VERSION "dbc-export 1 2025.20.8"

NS_ :

BS_:

BU_: ADSP APB APP APS APSB BB BMS CC CMP CMPD CP DAS DI DIF DIR DPB EPAS3P EPAS3S EPASTP EPASTS EPBL EPBR ESP GTW HVP IBST ICR IDB OCS1P ODIN PARK PCS PLG PM PMF PMR PTC RADC RCM RCM2 RCU SCCM SDCR TAS TCU TPMS TRCM UDS UI UIS UMC USM VC VCFRONT VCLEFT VCRIGHT VCSEC

BO_ 1000 EPBR_alertMatrix: 8 EPBR
 SG_ EPBR_matrixIndex M : 0|4@1+ (1,0) [0|15] "" Vector__XXX
 SG_ EPBR_a001_WatchdogReset m0 : 4|1@1+ (1,0) [0|1] "" Vector__XXX
 SG_ EPBR_a002_PowerLossReset m0 : 5|1@1+ (1,0) [0|1] "" Vector__XXX
 SG_ EPBR_a003_SWAssertion m0 : 6|1@1+ (1,0) [0|1] "" Vector__XXX
 SG_ EPBR_a005_CANTXError m0 : 8|1@1+ (1,0) [0|1] "" Vector__XXX
 SG_ EPBR_a006_CANTX_cyclicError m0 : 9|1@1+ (1,0) [0|1] "" Vector__XXX
 SG_ EPBR_a012_CPUReset m0 : 15|1@1+ (1,0) [0|1] "" Vector__XXX
 SG_ EPBR_a013_AlertManagerFault m0 : 16|1@1+ (1,0) [0|1] "" Vector__XXX
 SG_ EPBR_a015_NVMMError m0 : 18|1@1+ (1,0) [0|1] "" Vector__XXX
 SG_ EPBR_a016_NVMMRecordError m0 : 19|1@1+ (1,0) [0|1] "" Vector__XXX
 SG_ EPBR_a021_TaskSchedulerError m0 : 24|1@1+ (1,0) [0|1] "" Vector__XXX
 SG_ EPBR_a022_TaskInitError m0 : 25|1@1+ (1,0) [0|1] "" Vector__XXX
 SG_ EPBR_a029_CoreDump m0 : 32|1@1+ (1,0) [0|1] "" Vector__XXX
 SG_ EPBR_a030_ECULogUploadRequest m0 : 33|1@1+ (1,0) [0|1] "" Vector__XXX
 SG_ EPBR_a031_UDSActive m0 : 34|1@1+ (1,0) [0|1] "" Vector__XXX
 SG_ EPBR_a041_HighCPULoad m0 : 44|1@1+ (1,0) [0|1] "" Vector__XXX
 SG_ EPBR_a042_HighStackUsage m0 : 45|1@1+ (1,0) [0|1] "" Vector__XXX
 SG_ EPBR_a043_Task1msError m0 : 46|1@1+ (1,0) [0|1] "" Vector__XXX
 SG_ EPBR_a044_Task10msError m0 : 47|1@1+ (1,0) [0|1] "" Vector__XXX
 SG_ EPBR_a045_Task100msError m0 : 48|1@1+ (1,0) [0|1] "" Vector__XXX
 SG_ EPBR_a046_Task1000msError m0 : 49|1@1+ (1,0) [0|1] "" Vector__XXX
 SG_ EPBR_a057_HVP_MIA m0 : 60|1@1+ (1,0) [0|1] "" Vector__XXX
 SG_ EPBR_a058_inputRHighSyncDebug m0 : 61|1@1+ (1,0) [0|1] "" Vector__XXX
 SG_ EPBR_a059_inputResistanceHigh m0 : 62|1@1+ (1,0) [0|1] "" Vector__XXX
 SG_ EPBR_a060_engineeringBuild m0 : 63|1@1+ (1,0) [0|1] "" Vector__XXX
 SG_ EPBR_a061_XCPConnected m1 : 4|1@1+ (1,0) [0|1] "" Vector__XXX
 SG_ EPBR_a062_XCPWasConnected m1 : 5|1@1+ (1,0) [0|1] "" Vector__XXX
 SG_ EPBR_a063_SwitchFault m1 : 6|1@1+ (1,0) [0|1] "" Vector__XXX
 SG_ EPBR_a064_busSleepReqTimeout m1 : 7|1@1+ (1,0) [0|1] "" Vector__XXX
 SG_ EPBR_a081_APP_MIA m1 : 24|1@1+ (1,0) [0|1] "" Vector__XXX
 SG_ EPBR_a082_VCRIGHT_IPC_MIA m1 : 25|1@1+ (1,0) [0|1] "" Vector__XXX
 SG_ EPBR_a083_VCLEFT_IPC_MIA m1 : 26|1@1+ (1,0) [0|1] "" Vector__XXX
 SG_ EPBR_a084_TPMS_MIA m1 : 27|1@1+ (1,0) [0|1] "" Vector__XXX
 SG_ EPBR_a085_CCCM_MIA m1 : 28|1@1+ (1,0) [0|1] "" Vector__XXX
 SG_ EPBR_a086_VCBATT_MIA m1 : 29|1@1+ (1,0) [0|1] "" Vector__XXX
 SG_ EPBR_a087_DIREL_MIA m1 : 30|1@1+ (1,0) [0|1] "" Vector__XXX
 SG_ EPBR_a088_DIRER_MIA m1 : 31|1@1+ (1,0) [0|1] "" Vector__XXX
 SG_ EPBR_a089_IBST_MIA m1 : 32|1@1+ (1,0) [0|1] "" Vector__XXX
 SG_ EPBR_a090_APS_MIA m1 : 33|1@1+ (1,0) [0|1] "" Vector__XXX
 SG_ EPBR_a091_CMPD_MIA m1 : 34|1@1+ (1,0) [0|1] "" Vector__XXX
 SG_ EPBR_a092_VCSEATD_MIA m1 : 35|1@1+ (1,0) [0|1] "" Vector__XXX
 SG_ EPBR_a093_VCSEATP_MIA m1 : 36|1@1+ (1,0) [0|1] "" Vector__XXX
 SG_ EPBR_a094_EPAS3P_MIA m1 : 37|1@1+ (1,0) [0|1] "" Vector__XXX
 SG_ EPBR_a095_CHG_MIA m1 : 38|1@1+ (1,0) [0|1] "" Vector__XXX
 SG_ EPBR_a096_OCS1P_MIA m1 : 39|1@1+ (1,0) [0|1] "" Vector__XXX
 SG_ EPBR_a097_CMP_MIA m1 : 40|1@1+ (1,0) [0|1] "" Vector__XXX
 SG_ EPBR_a098_DIR_MIA m1 : 41|1@1+ (1,0) [0|1] "" Vector__XXX
 SG_ EPBR_a099_PARK_MIA m1 : 42|1@1+ (1,0) [0|1] "" Vector__XXX
 SG_ EPBR_a100_CANbus_MIA m1 : 43|1@1+ (1,0) [0|1] "" Vector__XXX
 SG_ EPBR_a101_PM_MIA m1 : 44|1@1+ (1,0) [0|1] "" Vector__XXX
 SG_ EPBR_a102_PTC_MIA m1 : 45|1@1+ (1,0) [0|1] "" Vector__XXX
 SG_ EPBR_a103_CP_MIA m1 : 46|1@1+ (1,0) [0|1] "" Vector__XXX
 SG_ EPBR_a104_DAS_MIA m1 : 47|1@1+ (1,0) [0|1] "" Vector__XXX
 SG_ EPBR_a105_TAS_MIA m1 : 48|1@1+ (1,0) [0|1] "" Vector__XXX
 SG_ EPBR_a106_PCS_MIA m1 : 49|1@1+ (1,0) [0|1] "" Vector__XXX
 SG_ EPBR_a107_BMS_MIA m1 : 50|1@1+ (1,0) [0|1] "" Vector__XXX
 SG_ EPBR_a108_DIF_MIA m1 : 51|1@1+ (1,0) [0|1] "" Vector__XXX
 SG_ EPBR_a109_RCM_MIA m1 : 52|1@1+ (1,0) [0|1] "" Vector__XXX
 SG_ EPBR_a110_GTW_MIA m1 : 53|1@1+ (1,0) [0|1] "" Vector__XXX
 SG_ EPBR_a111_EPBR_MIA m1 : 54|1@1+ (1,0) [0|1] "" Vector__XXX
 SG_ EPBR_a112_EPBL_MIA m1 : 55|1@1+ (1,0) [0|1] "" Vector__XXX
 SG_ EPBR_a113_UI_MIA m1 : 56|1@1+ (1,0) [0|1] "" Vector__XXX
 SG_ EPBR_a114_ESP_MIA m1 : 57|1@1+ (1,0) [0|1] "" Vector__XXX
 SG_ EPBR_a115_VCSEC_MIA m1 : 58|1@1+ (1,0) [0|1] "" Vector__XXX
 SG_ EPBR_a116_VCRIGHT_MIA m1 : 59|1@1+ (1,0) [0|1] "" Vector__XXX
 SG_ EPBR_a117_VCLEFT_MIA m1 : 60|1@1+ (1,0) [0|1] "" Vector__XXX
 SG_ EPBR_a118_VCFRONT_MIA m1 : 61|1@1+ (1,0) [0|1] "" Vector__XXX
 SG_ EPBR_a119_SCCM_MIA m1 : 62|1@1+ (1,0) [0|1] "" Vector__XXX
 SG_ EPBR_a120_DI_DRIVE_MIA m1 : 63|1@1+ (1,0) [0|1] "" Vector__XXX
 SG_ EPBR_a121_nDriveFault m2 : 4|1@1+ (1,0) [0|1] "" Vector__XXX
 SG_ EPBR_a122_Oc m2 : 5|1@1+ (1,0) [0|1] "" Vector__XXX
 SG_ EPBR_a123_Uc m2 : 6|1@1+ (1,0) [0|1] "" Vector__XXX
 SG_ EPBR_a124_calOutOfBounds m2 : 7|1@1+ (1,0) [0|1] "" Vector__XXX
 SG_ EPBR_a125_IdleVMismatch m2 : 8|1@1+ (1,0) [0|1] "" Vector__XXX
 SG_ EPBR_a126_MotorNVoltLow m2 : 9|1@1+ (1,0) [0|1] "" Vector__XXX
 SG_ EPBR_a127_MotorNVoltHigh m2 : 10|1@1+ (1,0) [0|1] "" Vector__XXX
 SG_ EPBR_a128_MotorPVoltHigh m2 : 11|1@1+ (1,0) [0|1] "" Vector__XXX
 SG_ EPBR_a129_ICR_MIA m2 : 12|1@1+ (1,0) [0|1] "" Vector__XXX
 SG_ EPBR_a130_BB_MIA m2 : 13|1@1+ (1,0) [0|1] "" Vector__XXX
 SG_ EPBR_a131_RCU_MIA m2 : 14|1@1+ (1,0) [0|1] "" Vector__XXX
 SG_ EPBR_a132_VCBATT1_MIA m2 : 15|1@1+ (1,0) [0|1] "" Vector__XXX
 SG_ EPBR_a134_NvOv m2 : 17|1@1+ (1,0) [0|1] "" Vector__XXX
 SG_ EPBR_a135_NvUv m2 : 18|1@1+ (1,0) [0|1] "" Vector__XXX
 SG_ EPBR_a136_PvOv m2 : 19|1@1+ (1,0) [0|1] "" Vector__XXX
 SG_ EPBR_a137_PvUv m2 : 20|1@1+ (1,0) [0|1] "" Vector__XXX
 SG_ EPBR_a138_NvmDualFailure m2 : 21|1@1+ (1,0) [0|1] "" Vector__XXX
 SG_ EPBR_a139_NvmRedundancyLoss m2 : 22|1@1+ (1,0) [0|1] "" Vector__XXX
 SG_ EPBR_a140_NvmSlowWrite m2 : 23|1@1+ (1,0) [0|1] "" Vector__XXX
 SG_ EPBR_a141_invalidState m2 : 24|1@1+ (1,0) [0|1] "" Vector__XXX
 SG_ EPBR_a170_12vOv m2 : 53|1@1+ (1,0) [0|1] "" Vector__XXX
 SG_ EPBR_a171_12vUv m2 : 54|1@1+ (1,0) [0|1] "" Vector__XXX
 SG_ EPBR_a172_SPI_MIA m2 : 55|1@1+ (1,0) [0|1] "" Vector__XXX
 SG_ EPBR_a173_hiCurrentMissing m2 : 56|1@1+ (1,0) [0|1] "" Vector__XXX
 SG_ EPBR_a174_csmReleaseFailed m2 : 57|1@1+ (1,0) [0|1] "" Vector__XXX
 SG_ EPBR_a175_csmReleaseRetry m2 : 58|1@1+ (1,0) [0|1] "" Vector__XXX
 SG_ EPBR_a176_csmApplyFailed m2 : 59|1@1+ (1,0) [0|1] "" Vector__XXX
 SG_ EPBR_a177_csmApplyRetry m2 : 60|1@1+ (1,0) [0|1] "" Vector__XXX
 SG_ EPBR_a178_caliperStateUnknown m2 : 61|1@1+ (1,0) [0|1] "" Vector__XXX
 SG_ EPBR_a179_epbProblem m2 : 62|1@1+ (1,0) [0|1] "" Vector__XXX
 SG_ EPBR_a180_dynamicActive m2 : 63|1@1+ (1,0) [0|1] "" Vector__XXX
 SG_ EPBR_a181_TooSteepGradeToPark m3 : 4|1@1+ (1,0) [0|1] "" Vector__XXX
 SG_ EPBR_a182_OneEPBAppliedUnsecEnv m3 : 5|1@1+ (1,0) [0|1] "" Vector__XXX
 SG_ EPBR_a183_cdpNotAvailable m3 : 6|1@1+ (1,0) [0|1] "" Vector__XXX
 SG_ EPBR_a184_dynamicParkAbort m3 : 7|1@1+ (1,0) [0|1] "" Vector__XXX
 SG_ EPBR_a185_summonAborted m3 : 8|1@1+ (1,0) [0|1] "" Vector__XXX
 SG_ EPBR_a186_externalParkAbort m3 : 9|1@1+ (1,0) [0|1] "" Vector__XXX
 SG_ EPBR_a187_cdpDynamic m3 : 10|1@1+ (1,0) [0|1] "" Vector__XXX
 SG_ EPBR_a188_epbDynamic m3 : 11|1@1+ (1,0) [0|1] "" Vector__XXX
 SG_ EPBR_a189_epbDynamicParkCanceled m3 : 12|1@1+ (1,0) [0|1] "" Vector__XXX
 SG_ EPBR_a190_csmApplyDegraded m3 : 13|1@1+ (1,0) [0|1] "" Vector__XXX
 SG_ EPBR_a191_csmReleaseDegraded m3 : 14|1@1+ (1,0) [0|1] "" Vector__XXX
 SG_ EPBR_a195_parkForDriverIsLeaving m3 : 18|1@1+ (1,0) [0|1] "" Vector__XXX
 SG_ EPBR_a196_freeRollModeActive m3 : 19|1@1+ (1,0) [0|1] "" Vector__XXX
 SG_ EPBR_a197_freeRollModeAtSpeed m3 : 20|1@1+ (1,0) [0|1] "" Vector__XXX
 SG_ EPBR_a198_holdClampComplete m3 : 21|1@1+ (1,0) [0|1] "" Vector__XXX
 SG_ EPBR_a200_PmUnparkNotAllowed m3 : 23|1@1+ (1,0) [0|1] "" Vector__XXX
 SG_ EPBR_a202_remoteEpbConfigIncompa m3 : 25|1@1+ (1,0) [0|1] "" Vector__XXX
 SG_ EPBR_a203_hwBrakeTypeMismatch m3 : 26|1@1+ (1,0) [0|1] "" Vector__XXX
 SG_ EPBR_a210_parkForDriverIsLeaving m3 : 33|1@1+ (1,0) [0|1] "" Vector__XXX
 SG_ EPBR_a216_SPI_MIA_debugData1 m3 : 39|1@1+ (1,0) [0|1] "" Vector__XXX
 SG_ EPBR_a217_SPI_MIA_debugData2 m3 : 40|1@1+ (1,0) [0|1] "" Vector__XXX
 SG_ EPBR_a225_epbActiveDecel m3 : 48|1@1+ (1,0) [0|1] "" Vector__XXX
 SG_ EPBR_a241_diOutputLocked m4 : 4|1@1+ (1,0) [0|1] "" Vector__XXX
 SG_ EPBR_a242_hvOutputLocked m4 : 5|1@1+ (1,0) [0|1] "" Vector__XXX
 SG_ EPBR_a243_bdwUnavailable m4 : 6|1@1+ (1,0) [0|1] "" Vector__XXX
 SG_ EPBR_a244_WinchModeActive m4 : 7|1@1+ (1,0) [0|1] "" Vector__XXX
 SG_ EPBR_a245_serviceModeActive m4 : 8|1@1+ (1,0) [0|1] "" Vector__XXX
 SG_ EPBR_a246_idleFaultApply m4 : 9|1@1+ (1,0) [0|1] "" Vector__XXX
 SG_ EPBR_a247_csmDynamicApplyRetry m4 : 10|1@1+ (1,0) [0|1] "" Vector__XXX
 SG_ EPBR_a248_csmDynamicApplyFailed m4 : 11|1@1+ (1,0) [0|1] "" Vector__XXX
 SG_ EPBR_a249_idleFaultRelease m4 : 12|1@1+ (1,0) [0|1] "" Vector__XXX
 SG_ EPBR_a250_WinchModeCanceled m4 : 13|1@1+ (1,0) [0|1] "" Vector__XXX
 SG_ EPBR_a251_currentVarianceHigh m4 : 14|1@1+ (1,0) [0|1] "" Vector__XXX
 SG_ EPBR_a252_winchModePending m4 : 15|1@1+ (1,0) [0|1] "" Vector__XXX
 SG_ EPBR_a253_esmReleaseBlocked m4 : 16|1@1+ (1,0) [0|1] "" Vector__XXX
 SG_ EPBR_a254_showStalkParkButtonFau m4 : 17|1@1+ (1,0) [0|1] "" Vector__XXX
 SG_ EPBR_a256_epbSystemApply m4 : 19|1@1+ (1,0) [0|1] "" Vector__XXX
 SG_ EPBR_a261_winchModeWithoutSteeri m4 : 24|1@1+ (1,0) [0|1] "" Vector__XXX
 SG_ EPBR_a262_cannotPrepareWinchMode m4 : 25|1@1+ (1,0) [0|1] "" Vector__XXX
 SG_ EPBR_a263_epbRecoveryPark m4 : 26|1@1+ (1,0) [0|1] "" Vector__XXX
 SG_ EPBR_a264_winchModeDeactivated m4 : 27|1@1+ (1,0) [0|1] "" Vector__XXX
 SG_ EPBR_a272_vhclPwrStateMsmtch m4 : 35|1@1+ (1,0) [0|1] "" Vector__XXX
 SG_ EPBR_a300_leftRightConfusion m4 : 63|1@1+ (1,0) [0|1] "" Vector__XXX
 SG_ EPBR_a301_oocSpeedViolation m5 : 4|1@1+ (1,0) [0|1] "" Vector__XXX
 SG_ EPBR_a302_csmLongRelease m5 : 5|1@1+ (1,0) [0|1] "" Vector__XXX
 SG_ EPBR_a303_clampingOccuredEarly m5 : 6|1@1+ (1,0) [0|1] "" Vector__XXX
 SG_ EPBR_a304_rearSeatControllerEFus m5 : 7|1@1+ (1,0) [0|1] "" Vector__XXX
 SG_ EPBR_a305_premiumAmpEFuseTrip m5 : 8|1@1+ (1,0) [0|1] "" Vector__XXX
 SG_ EPBR_a350_ensOutOfRange m5 : 53|1@1+ (1,0) [0|1] "" Vector__XXX
 SG_ EPBR_a352_audioCurrentSpikeData m5 : 55|1@1+ (1,0) [0|1] "" Vector__XXX
 SG_ EPBR_a353_missingSpeedUnableToPa m5 : 56|1@1+ (1,0) [0|1] "" Vector__XXX
 SG_ EPBR_a354_parkedForLowBrakeFluid m5 : 57|1@1+ (1,0) [0|1] "" Vector__XXX
 SG_ EPBR_a355_brakeHwAndEpbHwMismatc m5 : 58|1@1+ (1,0) [0|1] "" Vector__XXX
 SG_ EPBR_a356_parkingForStationaryDe m5 : 59|1@1+ (1,0) [0|1] "" Vector__XXX
 SG_ EPBR_a357_brakesTooHotForSlope m5 : 60|1@1+ (1,0) [0|1] "" Vector__XXX
 SG_ EPBR_a358_brakesTooHotForSlopeWi m5 : 61|1@1+ (1,0) [0|1] "" Vector__XXX
 SG_ EPBR_a360_ibstBrakeSwitchInvalid m5 : 63|1@1+ (1,0) [0|1] "" Vector__XXX
 SG_ EPBR_a361_espBrakeSwitchInvalid m6 : 4|1@1+ (1,0) [0|1] "" Vector__XXX
 SG_ EPBR_a362_ibstPressedEspNotPress m6 : 5|1@1+ (1,0) [0|1] "" Vector__XXX
 SG_ EPBR_a363_ibstNotPressedEspPress m6 : 6|1@1+ (1,0) [0|1] "" Vector__XXX
 SG_ EPBR_a364_espMasterCylCompOverTh m6 : 7|1@1+ (1,0) [0|1] "" Vector__XXX
 SG_ EPBR_a365_TooSteepToParkWithTrai m6 : 8|1@1+ (1,0) [0|1] "" Vector__XXX
 SG_ EPBR_a366_TooSteepToParkWithTrai m6 : 9|1@1+ (1,0) [0|1] "" Vector__XXX

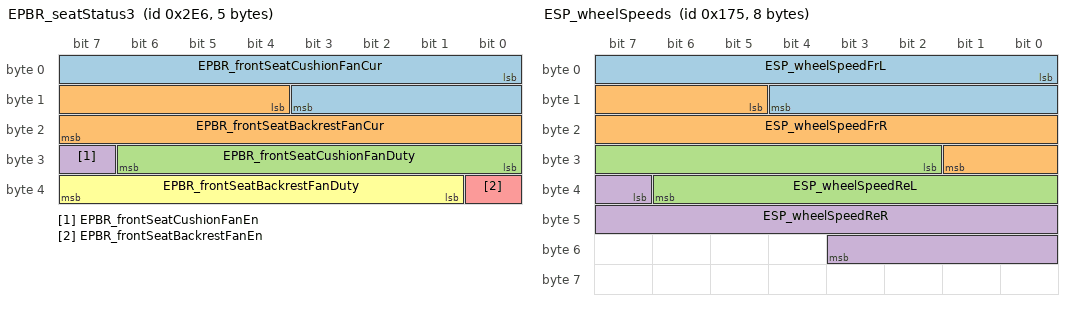
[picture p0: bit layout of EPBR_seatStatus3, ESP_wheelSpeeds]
BO_ 742 EPBR_seatStatus3: 5 EPBR
 SG_ EPBR_frontSeatCushionFanCur : 0|12@1+ (0.01,0) [0|40.95] "A" Vector__XXX
 SG_ EPBR_frontSeatBackrestFanCur : 12|12@1+ (0.01,0) [0|40.95] "A" Vector__XXX
 SG_ EPBR_frontSeatCushionFanDuty : 24|7@1+ (1,0) [0|100] "%" Vector__XXX
 SG_ EPBR_frontSeatCushionFanEn : 31|1@1+ (1,0) [0|1] "" Vector__XXX
 SG_ EPBR_frontSeatBackrestFanEn : 32|1@1+ (1,0) [0|1] "" Vector__XXX
 SG_ EPBR_frontSeatBackrestFanDuty : 33|7@1+ (1,0) [0|100] "%" Vector__XXX

BO_ 744 EPBR_status: 8 EPBR
 SG_ EPBR_systemStatus : 0|4@1+ (1,0) [0|15] "" Vector__XXX
 SG_ EPBR_freeRollModeStatus : 4|2@1+ (1,0) [0|3] "" Vector__XXX
 SG_ EPBR_driverIsLeaving : 6|1@1+ (1,0) [0|1] "" Vector__XXX
 SG_ EPBR_driverIsLeavingAnySpeed : 7|1@1+ (1,0) [0|1] "" Vector__XXX
 SG_ EPBR_systemCdpAvailable : 8|1@1+ (1,0) [0|1] "" Vector__XXX
 SG_ EPBR_chimeRequest : 9|3@1+ (1,0) [0|7] "" Vector__XXX
 SG_ EPBR_telltale : 12|3@1+ (1,0) [0|6] "" Vector__XXX
 SG_ EPBR_audioCurrentSpikeDetected : 15|1@1+ (1,0) [0|1] "" Vector__XXX
 SG_ EPBR_redundantBrakingEnabled : 16|1@1+ (1,0) [0|1] "" Vector__XXX
 SG_ EPBR_summonEnabled : 17|1@1+ (1,0) [0|1] "" Vector__XXX
 SG_ EPBR_brakeLight : 18|1@1+ (1,0) [0|1] "" Vector__XXX
 SG_ EPBR_epbConfigMismatch : 19|1@1+ (1,0) [0|1] "" Vector__XXX
 SG_ EPBR_brakeConfirmedPressed : 20|1@1+ (1,0) [0|1] "" Vector__XXX
 SG_ EPBR_requestUserConfirmation : 21|1@1+ (1,0) [0|1] "" Vector__XXX
 SG_ EPBR_uiWinchModeMiscBlocking : 22|1@1+ (1,0) [0|1] "" Vector__XXX
 SG_ EPBR_winchModeActive : 23|1@1+ (1,0) [0|1] "" Vector__XXX
 SG_ EPBR_updateMode : 24|1@1+ (1,0) [0|1] "" Vector__XXX
 SG_ EPBR_winchModePermissive : 25|1@1+ (1,0) [0|1] "" Vector__XXX
 SG_ EPBR_winchModePending : 26|1@1+ (1,0) [0|1] "" Vector__XXX
 SG_ EPBR_cdpRequest : 27|1@1+ (1,0) [0|1] "" Vector__XXX
 SG_ EPBR_uiParkAvailable : 28|2@1+ (1,0) [0|3] "" Vector__XXX
 SG_ EPBR_brakeDiscWipeRequest : 30|2@1+ (1,0) [0|2] "" Vector__XXX
 SG_ EPBR_showUiGearShifter : 32|1@1+ (1,0) [0|1] "" Vector__XXX
 SG_ EPBR_uiWinchModeLvStatus : 33|2@1+ (1,0) [0|3] "" Vector__XXX
 SG_ EPBR_contactorCycleNotNeededForW : 35|1@1+ (1,0) [0|1] "" Vector__XXX
 SG_ EPBR_showStalkFaultedOnUi : 45|1@1+ (1,0) [0|1] "" Vector__XXX
 SG_ EPBR_espPowerRequest : 46|1@1+ (1,0) [0|1] "" Vector__XXX
 SG_ EPBR_okToPark : 47|1@1+ (1,0) [0|1] "" Vector__XXX
 SG_ EPBR_hornRequest : 48|1@1+ (1,0) [0|1] "" Vector__XXX
 SG_ EPBR_winchModeAvailable : 49|1@1+ (1,0) [0|1] "" Vector__XXX
 SG_ EPBR_bothDisconnected : 50|1@1+ (1,0) [0|1] "" Vector__XXX
 SG_ EPBR_blockDrive : 51|1@1+ (1,0) [0|1] "" Vector__XXX
 SG_ EPBR_statusCounter : 52|4@1+ (1,0) [0|15] "" Vector__XXX
 SG_ EPBR_statusChecksum : 56|8@1+ (1,0) [0|255] "" Vector__XXX

BO_ 1575 EPBR_udsResponse: 8 EPBR
 SG_ EPBR_udsResponseData_H : 7|32@0+ (1,0) [0|4294967295] "" Vector__XXX
 SG_ EPBR_udsResponseData_L : 39|32@0+ (1,0) [0|4294967295] "" Vector__XXX

BO_ 981 ESP_alertMatrix: 8 ESP
 SG_ ESP_matrixIndex M : 0|4@1+ (1,0) [0|15] "" Vector__XXX
 SG_ ESP_a001_ecuGenericFault m0 : 4|1@1+ (1,0) [0|1] "" Vector__XXX
 SG_ ESP_a002_valvesGenericFault m0 : 5|1@1+ (1,0) [0|1] "" Vector__XXX
 SG_ ESP_a003_outletValvesFault m0 : 6|1@1+ (1,0) [0|1] "" Vector__XXX
 SG_ ESP_a004_inletValvesFault m0 : 7|1@1+ (1,0) [0|1] "" Vector__XXX
 SG_ ESP_a005_HSVValvesFault m0 : 8|1@1+ (1,0) [0|1] "" Vector__XXX
 SG_ ESP_a006_USVValvesFault m0 : 9|1@1+ (1,0) [0|1] "" Vector__XXX
 SG_ ESP_a007_pumpMotorFault m0 : 10|1@1+ (1,0) [0|1] "" Vector__XXX
 SG_ ESP_a008_pumpMotor12VsupplyLow m0 : 11|1@1+ (1,0) [0|1] "" Vector__XXX
 SG_ ESP_a009_12VHardUndervoltage m0 : 12|1@1+ (1,0) [0|1] "" Vector__XXX
 SG_ ESP_a010_12VUndervoltage m0 : 13|1@1+ (1,0) [0|1] "" Vector__XXX
 SG_ ESP_a011_12VSystemUndervoltage m0 : 14|1@1+ (1,0) [0|1] "" Vector__XXX
 SG_ ESP_a012_netUndervoltage m0 : 15|1@1+ (1,0) [0|1] "" Vector__XXX
 SG_ ESP_a013_valveRelayUndervoltage m0 : 16|1@1+ (1,0) [0|1] "" Vector__XXX
 SG_ ESP_a014_WSSSupplyUndervoltage m0 : 17|1@1+ (1,0) [0|1] "" Vector__XXX
 SG_ ESP_a015_12VSupplyOvervoltage m0 : 18|1@1+ (1,0) [0|1] "" Vector__XXX
 SG_ ESP_a016_12VSystemOvervoltage m0 : 19|1@1+ (1,0) [0|1] "" Vector__XXX
 SG_ ESP_a017_netOvervoltage m0 : 20|1@1+ (1,0) [0|1] "" Vector__XXX
 SG_ ESP_a018_WSSSignFrontAxle m0 : 21|1@1+ (1,0) [0|1] "" Vector__XXX
 SG_ ESP_a019_WSSSignRearAxle m0 : 22|1@1+ (1,0) [0|1] "" Vector__XXX
 SG_ ESP_a020_WSSGenericTempFault m0 : 23|1@1+ (1,0) [0|1] "" Vector__XXX
 SG_ ESP_a021_WSSGeneralVDiffFault m0 : 24|1@1+ (1,0) [0|1] "" Vector__XXX
 SG_ ESP_a022_WSSDirectionFault m0 : 25|1@1+ (1,0) [0|1] "" Vector__XXX
 SG_ ESP_a023_WSSSeveralSuspected m0 : 26|1@1+ (1,0) [0|1] "" Vector__XXX
 SG_ ESP_a024_WSSReverseCurrent m0 : 27|1@1+ (1,0) [0|1] "" Vector__XXX
 SG_ ESP_a025_FrLWSSOpenOrShortToGnd m0 : 28|1@1+ (1,0) [0|1] "" Vector__XXX
 SG_ ESP_a026_FrLWSSShortTo12V m0 : 29|1@1+ (1,0) [0|1] "" Vector__XXX
 SG_ ESP_a027_FrLWSSLineInterruption m0 : 30|1@1+ (1,0) [0|1] "" Vector__XXX
 SG_ ESP_a028_FrLWSSMaxSpeedExceeded m0 : 31|1@1+ (1,0) [0|1] "" Vector__XXX
 SG_ ESP_a029_FrLWSSTooManyPulses m0 : 32|1@1+ (1,0) [0|1] "" Vector__XXX
 SG_ ESP_a030_FrLWSSLostSignal m0 : 33|1@1+ (1,0) [0|1] "" Vector__XXX
 SG_ ESP_a031_FrLWSSNoPulsesDetected m0 : 34|1@1+ (1,0) [0|1] "" Vector__XXX
 SG_ ESP_a032_FrLWSSWrongSensorType m0 : 35|1@1+ (1,0) [0|1] "" Vector__XXX
 SG_ ESP_a033_FrLWSSSignalNoise m0 : 36|1@1+ (1,0) [0|1] "" Vector__XXX
 SG_ ESP_a034_FrLWSSVDiffFault m0 : 37|1@1+ (1,0) [0|1] "" Vector__XXX
 SG_ ESP_a035_FrLWSSDirectionFault m0 : 38|1@1+ (1,0) [0|1] "" Vector__XXX
 SG_ ESP_a036_FrLWSSLargeAirGap m0 : 39|1@1+ (1,0) [0|1] "" Vector__XXX
 SG_ ESP_a037_FrLWSSSupplyShortToGnd m0 : 40|1@1+ (1,0) [0|1] "" Vector__XXX
 SG_ ESP_a038_FrLWSSGeneralFault m0 : 41|1@1+ (1,0) [0|1] "" Vector__XXX
 SG_ ESP_a039_FrRWSSOpenOrShortToGnd m0 : 42|1@1+ (1,0) [0|1] "" Vector__XXX
 SG_ ESP_a040_FrRWSSShortTo12V m0 : 43|1@1+ (1,0) [0|1] "" Vector__XXX
 SG_ ESP_a041_FrRWSSLineInterruption m0 : 44|1@1+ (1,0) [0|1] "" Vector__XXX
 SG_ ESP_a042_FrRWSSMaxSpeedExceeded m0 : 45|1@1+ (1,0) [0|1] "" Vector__XXX
 SG_ ESP_a043_FrRWSSTooManyPulses m0 : 46|1@1+ (1,0) [0|1] "" Vector__XXX
 SG_ ESP_a044_FrRWSSLostSignal m0 : 47|1@1+ (1,0) [0|1] "" Vector__XXX
 SG_ ESP_a045_FrRWSSNoPulsesDetected m0 : 48|1@1+ (1,0) [0|1] "" Vector__XXX
 SG_ ESP_a046_FrRWSSWrongSensorType m0 : 49|1@1+ (1,0) [0|1] "" Vector__XXX
 SG_ ESP_a047_FrRWSSSignalNoise m0 : 50|1@1+ (1,0) [0|1] "" Vector__XXX
 SG_ ESP_a048_FrRWSSVDiffFault m0 : 51|1@1+ (1,0) [0|1] "" Vector__XXX
 SG_ ESP_a049_FrRWSSDirectionFault m0 : 52|1@1+ (1,0) [0|1] "" Vector__XXX
 SG_ ESP_a050_FrRWSSLargeAirGap m0 : 53|1@1+ (1,0) [0|1] "" Vector__XXX
 SG_ ESP_a051_FrRWSSSupplyShortToGnd m0 : 54|1@1+ (1,0) [0|1] "" Vector__XXX
 SG_ ESP_a052_FrRWSSGeneralFault m0 : 55|1@1+ (1,0) [0|1] "" Vector__XXX
 SG_ ESP_a053_ReLWSSOpenOrShortToGnd m0 : 56|1@1+ (1,0) [0|1] "" Vector__XXX
 SG_ ESP_a054_ReLWSSShortTo12V m0 : 57|1@1+ (1,0) [0|1] "" Vector__XXX
 SG_ ESP_a055_ReLWSSLineInterruption m0 : 58|1@1+ (1,0) [0|1] "" Vector__XXX
 SG_ ESP_a056_ReLWSSMaxSpeedExceeded m0 : 59|1@1+ (1,0) [0|1] "" Vector__XXX
 SG_ ESP_a057_ReLWSSTooManyPulses m0 : 60|1@1+ (1,0) [0|1] "" Vector__XXX
 SG_ ESP_a058_ReLWSSLostSignal m0 : 61|1@1+ (1,0) [0|1] "" Vector__XXX
 SG_ ESP_a059_ReLWSSNoPulsesDetected m0 : 62|1@1+ (1,0) [0|1] "" Vector__XXX
 SG_ ESP_a060_ReLWSSWrongSensorType m0 : 63|1@1+ (1,0) [0|1] "" Vector__XXX
 SG_ ESP_a061_ReLWSSSignalNoise m1 : 4|1@1+ (1,0) [0|1] "" Vector__XXX
 SG_ ESP_a062_ReLWSSVDiffFault m1 : 5|1@1+ (1,0) [0|1] "" Vector__XXX
 SG_ ESP_a063_ReLWSSDirectionFault m1 : 6|1@1+ (1,0) [0|1] "" Vector__XXX
 SG_ ESP_a064_ReLWSSLargeAirGap m1 : 7|1@1+ (1,0) [0|1] "" Vector__XXX
 SG_ ESP_a065_ReLWSSSupplyShortToGnd m1 : 8|1@1+ (1,0) [0|1] "" Vector__XXX
 SG_ ESP_a066_ReLWSSGeneralFault m1 : 9|1@1+ (1,0) [0|1] "" Vector__XXX
 SG_ ESP_a067_ReRWSSOpenOrShortToGnd m1 : 10|1@1+ (1,0) [0|1] "" Vector__XXX
 SG_ ESP_a068_ReRWSSShortTo12V m1 : 11|1@1+ (1,0) [0|1] "" Vector__XXX
 SG_ ESP_a069_ReRWSSLineInterruption m1 : 12|1@1+ (1,0) [0|1] "" Vector__XXX
 SG_ ESP_a070_ReRWSSMaxSpeedExceeded m1 : 13|1@1+ (1,0) [0|1] "" Vector__XXX
 SG_ ESP_a071_ReRWSSTooManyPulses m1 : 14|1@1+ (1,0) [0|1] "" Vector__XXX
 SG_ ESP_a072_ReRWSSLostSignal m1 : 15|1@1+ (1,0) [0|1] "" Vector__XXX
 SG_ ESP_a073_ReRWSSNoPulsesDetected m1 : 16|1@1+ (1,0) [0|1] "" Vector__XXX
 SG_ ESP_a074_ReRWSSWrongSensorType m1 : 17|1@1+ (1,0) [0|1] "" Vector__XXX
 SG_ ESP_a075_ReRWSSSignalNoise m1 : 18|1@1+ (1,0) [0|1] "" Vector__XXX
 SG_ ESP_a076_ReRWSSVDiffFault m1 : 19|1@1+ (1,0) [0|1] "" Vector__XXX
 SG_ ESP_a077_ReRWSSDirectionFault m1 : 20|1@1+ (1,0) [0|1] "" Vector__XXX
 SG_ ESP_a078_ReRWSSLargeAirGap m1 : 21|1@1+ (1,0) [0|1] "" Vector__XXX
 SG_ ESP_a079_ReRWSSSupplyShortToGnd m1 : 22|1@1+ (1,0) [0|1] "" Vector__XXX
 SG_ ESP_a080_ReRWSSGeneralFault m1 : 23|1@1+ (1,0) [0|1] "" Vector__XXX
 SG_ ESP_a081_PressureSensorShort m1 : 24|1@1+ (1,0) [0|1] "" Vector__XXX
 SG_ ESP_a082_PMCSensorOffsetHigh m1 : 25|1@1+ (1,0) [0|1] "" Vector__XXX
 SG_ ESP_a083_PMCSensorFault m1 : 26|1@1+ (1,0) [0|1] "" Vector__XXX
 SG_ ESP_a084_BrakeFluidReservoirLow m1 : 27|1@1+ (1,0) [0|1] "" Vector__XXX
 SG_ ESP_a085_BrakeSwitchStuckHigh m1 : 28|1@1+ (1,0) [0|1] "" Vector__XXX
 SG_ ESP_a086_BrakeSwitchImplausible1 m1 : 29|1@1+ (1,0) [0|1] "" Vector__XXX
 SG_ ESP_a087_BrakeSwitchImplausible3 m1 : 30|1@1+ (1,0) [0|1] "" Vector__XXX
 SG_ ESP_a088_absContinuousControl m1 : 31|1@1+ (1,0) [0|1] "" Vector__XXX
 SG_ ESP_a089_absNoPressureIncrease m1 : 32|1@1+ (1,0) [0|1] "" Vector__XXX
 SG_ ESP_a090_vdcContinuousControl m1 : 33|1@1+ (1,0) [0|1] "" Vector__XXX
 SG_ ESP_a091_CANUndervoltage m1 : 34|1@1+ (1,0) [0|1] "" Vector__XXX
 SG_ ESP_a092_CANOvervoltage m1 : 35|1@1+ (1,0) [0|1] "" Vector__XXX
 SG_ ESP_a093_partyBusOff m1 : 36|1@1+ (1,0) [0|1] "" Vector__XXX
 SG_ ESP_a094_partyBusPassive m1 : 37|1@1+ (1,0) [0|1] "" Vector__XXX
 SG_ ESP_a095_chassisBusOff m1 : 38|1@1+ (1,0) [0|1] "" Vector__XXX
 SG_ ESP_a096_chassisBusPassive m1 : 39|1@1+ (1,0) [0|1] "" Vector__XXX
 SG_ ESP_a097_tcsRefSpeedNotInit m1 : 40|1@1+ (1,0) [0|1] "" Vector__XXX
 SG_ ESP_a098_vdcRefSpeedNotInit m1 : 41|1@1+ (1,0) [0|1] "" Vector__XXX
 SG_ ESP_a099_brakeTempModelOverheat m1 : 42|1@1+ (1,0) [0|1] "" Vector__XXX
 SG_ ESP_a100_brakeTempModelDisabled m1 : 43|1@1+ (1,0) [0|1] "" Vector__XXX
 SG_ ESP_a101_ebdFault m1 : 44|1@1+ (1,0) [0|1] "" Vector__XXX
 SG_ ESP_a102_absFault m1 : 45|1@1+ (1,0) [0|1] "" Vector__XXX
 SG_ ESP_a103_stabilityControlFault m1 : 46|1@1+ (1,0) [0|1] "" Vector__XXX
 SG_ ESP_a104_hbcEnabled m1 : 47|1@1+ (1,0) [0|1] "" Vector__XXX
 SG_ ESP_a105_ebrFault m1 : 48|1@1+ (1,0) [0|1] "" Vector__XXX
 SG_ ESP_a106_vdcActuatorFault m1 : 49|1@1+ (1,0) [0|1] "" Vector__XXX
 SG_ ESP_a107_reserved107 m1 : 50|1@1+ (1,0) [0|1] "" Vector__XXX
 SG_ ESP_a108_reserved108 m1 : 51|1@1+ (1,0) [0|1] "" Vector__XXX
 SG_ ESP_a109_reserved109 m1 : 52|1@1+ (1,0) [0|1] "" Vector__XXX
 SG_ ESP_a110_rollerBenchActive m1 : 53|1@1+ (1,0) [0|1] "" Vector__XXX
 SG_ ESP_a111_absActive m1 : 54|1@1+ (1,0) [0|1] "" Vector__XXX
 SG_ ESP_a112_espActive m1 : 55|1@1+ (1,0) [0|1] "" Vector__XXX
 SG_ ESP_a113_btcActive m1 : 56|1@1+ (1,0) [0|1] "" Vector__XXX
 SG_ ESP_a114_tvdcActive m1 : 57|1@1+ (1,0) [0|1] "" Vector__XXX
 SG_ ESP_a115_ebdActive m1 : 58|1@1+ (1,0) [0|1] "" Vector__XXX
 SG_ ESP_a116_tsmActive m1 : 59|1@1+ (1,0) [0|1] "" Vector__XXX
 SG_ ESP_a117_hbaActive m1 : 60|1@1+ (1,0) [0|1] "" Vector__XXX
 SG_ ESP_a118_hfcActive m1 : 61|1@1+ (1,0) [0|1] "" Vector__XXX
 SG_ ESP_a119_hbbActive m1 : 62|1@1+ (1,0) [0|1] "" Vector__XXX
 SG_ ESP_a120_rmiActive m1 : 63|1@1+ (1,0) [0|1] "" Vector__XXX
 SG_ ESP_a121_regenTcActive m2 : 4|1@1+ (1,0) [0|1] "" Vector__XXX
 SG_ ESP_a122_bdwActive m2 : 5|1@1+ (1,0) [0|1] "" Vector__XXX
 SG_ ESP_a123_ebrActive m2 : 6|1@1+ (1,0) [0|1] "" Vector__XXX
 SG_ ESP_a124_ebrSkidActive m2 : 7|1@1+ (1,0) [0|1] "" Vector__XXX
 SG_ ESP_a125_reserved125 m2 : 8|1@1+ (1,0) [0|1] "" Vector__XXX
 SG_ ESP_a126_reserved126 m2 : 9|1@1+ (1,0) [0|1] "" Vector__XXX
 SG_ ESP_a127_reserved127 m2 : 10|1@1+ (1,0) [0|1] "" Vector__XXX
 SG_ ESP_a128_reserved128 m2 : 11|1@1+ (1,0) [0|1] "" Vector__XXX
 SG_ ESP_a129_reserved129 m2 : 12|1@1+ (1,0) [0|1] "" Vector__XXX
 SG_ ESP_a130_EPAS3PsysStatusTimeout m2 : 13|1@1+ (1,0) [0|1] "" Vector__XXX
 SG_ ESP_a131_EPAS3PsysStatusDLC m2 : 14|1@1+ (1,0) [0|1] "" Vector__XXX
 SG_ ESP_a132_EPAS3PsysStatusChecksum m2 : 15|1@1+ (1,0) [0|1] "" Vector__XXX
 SG_ ESP_a133_EPAS3PsysStatusCounter m2 : 16|1@1+ (1,0) [0|1] "" Vector__XXX
 SG_ ESP_a134_steeringAngleInvalid m2 : 17|1@1+ (1,0) [0|1] "" Vector__XXX
 SG_ ESP_a135_steeringAngleNoCenter m2 : 18|1@1+ (1,0) [0|1] "" Vector__XXX
 SG_ ESP_a136_steeringAngleFrozen m2 : 19|1@1+ (1,0) [0|1] "" Vector__XXX
 SG_ ESP_a137_steeringOffsetTooLarge m2 : 20|1@1+ (1,0) [0|1] "" Vector__XXX
 SG_ ESP_a138_steeringAngleImplaus m2 : 21|1@1+ (1,0) [0|1] "" Vector__XXX
 SG_ ESP_a139_steeringAngleWrongSign m2 : 22|1@1+ (1,0) [0|1] "" Vector__XXX
 SG_ ESP_a140_RCMInertial1Timeout m2 : 23|1@1+ (1,0) [0|1] "" Vector__XXX
 SG_ ESP_a141_RCMInertial1DLC m2 : 24|1@1+ (1,0) [0|1] "" Vector__XXX
 SG_ ESP_a142_RCMInertial1Checksum m2 : 25|1@1+ (1,0) [0|1] "" Vector__XXX
 SG_ ESP_a143_RCMInertial1Counter m2 : 26|1@1+ (1,0) [0|1] "" Vector__XXX
 SG_ ESP_a144_yawMaxLatency m2 : 27|1@1+ (1,0) [0|1] "" Vector__XXX
 SG_ ESP_a145_yawInitFault m2 : 28|1@1+ (1,0) [0|1] "" Vector__XXX
 SG_ ESP_a146_yawInvalidValue m2 : 29|1@1+ (1,0) [0|1] "" Vector__XXX
 SG_ ESP_a147_yawSensorNotAvailable m2 : 30|1@1+ (1,0) [0|1] "" Vector__XXX
 SG_ ESP_a148_yawSignalFault m2 : 31|1@1+ (1,0) [0|1] "" Vector__XXX
 SG_ ESP_a149_yawInvalidSign m2 : 32|1@1+ (1,0) [0|1] "" Vector__XXX
 SG_ ESP_a150_yawImplausible m2 : 33|1@1+ (1,0) [0|1] "" Vector__XXX
 SG_ ESP_a151_RCMInertial2Timeout m2 : 34|1@1+ (1,0) [0|1] "" Vector__XXX
 SG_ ESP_a152_RCMInertial2DLC m2 : 35|1@1+ (1,0) [0|1] "" Vector__XXX
 SG_ ESP_a153_RCMInertial2Checksum m2 : 36|1@1+ (1,0) [0|1] "" Vector__XXX
 SG_ ESP_a154_RCMInertial2Counter m2 : 37|1@1+ (1,0) [0|1] "" Vector__XXX
 SG_ ESP_a155_ayMaxLatency m2 : 38|1@1+ (1,0) [0|1] "" Vector__XXX
 SG_ ESP_a156_ayInitFault m2 : 39|1@1+ (1,0) [0|1] "" Vector__XXX
 SG_ ESP_a157_ayInvalidValue m2 : 40|1@1+ (1,0) [0|1] "" Vector__XXX
 SG_ ESP_a158_aySensorNotAvailable m2 : 41|1@1+ (1,0) [0|1] "" Vector__XXX
 SG_ ESP_a159_aySignalFault m2 : 42|1@1+ (1,0) [0|1] "" Vector__XXX
 SG_ ESP_a160_ayRangeExceeded m2 : 43|1@1+ (1,0) [0|1] "" Vector__XXX
 SG_ ESP_a161_ayOffsetExceeded m2 : 44|1@1+ (1,0) [0|1] "" Vector__XXX
 SG_ ESP_a162_ayImplausible m2 : 45|1@1+ (1,0) [0|1] "" Vector__XXX
 SG_ ESP_a163_axMaxLatency m2 : 46|1@1+ (1,0) [0|1] "" Vector__XXX
 SG_ ESP_a164_axInitFault m2 : 47|1@1+ (1,0) [0|1] "" Vector__XXX
 SG_ ESP_a165_axInvalidValue m2 : 48|1@1+ (1,0) [0|1] "" Vector__XXX
 SG_ ESP_a166_axSensorNotAvailable m2 : 49|1@1+ (1,0) [0|1] "" Vector__XXX
 SG_ ESP_a167_axSignalFault m2 : 50|1@1+ (1,0) [0|1] "" Vector__XXX
 SG_ ESP_a168_axRangeExceeded m2 : 51|1@1+ (1,0) [0|1] "" Vector__XXX
 SG_ ESP_a169_axOffsetExceeded m2 : 52|1@1+ (1,0) [0|1] "" Vector__XXX
 SG_ ESP_a170_axSignalFrozen m2 : 53|1@1+ (1,0) [0|1] "" Vector__XXX
 SG_ ESP_a171_axImplausible m2 : 54|1@1+ (1,0) [0|1] "" Vector__XXX
 SG_ ESP_a172_IBSTparty1Timeout m2 : 55|1@1+ (1,0) [0|1] "" Vector__XXX
 SG_ ESP_a173_IBSTparty1DLC m2 : 56|1@1+ (1,0) [0|1] "" Vector__XXX
 SG_ ESP_a174_IBSTparty1Checksum m2 : 57|1@1+ (1,0) [0|1] "" Vector__XXX
 SG_ ESP_a175_IBSTparty1Counter m2 : 58|1@1+ (1,0) [0|1] "" Vector__XXX
 SG_ ESP_a176_IBSTEBRNotAvailable m2 : 59|1@1+ (1,0) [0|1] "" Vector__XXX
 SG_ ESP_a177_IBSTOutputRodDrvInvalid m2 : 60|1@1+ (1,0) [0|1] "" Vector__XXX
 SG_ ESP_a178_IBSTOutputRodActInvalid m2 : 61|1@1+ (1,0) [0|1] "" Vector__XXX
 SG_ ESP_a179_IBSTparty2Timeout m2 : 62|1@1+ (1,0) [0|1] "" Vector__XXX
 SG_ ESP_a180_IBSTparty2Checksum m2 : 63|1@1+ (1,0) [0|1] "" Vector__XXX
 SG_ ESP_a181_IBSTparty2DLC m3 : 4|1@1+ (1,0) [0|1] "" Vector__XXX
 SG_ ESP_a182_IBSTparty2Counter m3 : 5|1@1+ (1,0) [0|1] "" Vector__XXX
 SG_ ESP_a183_IBSTStatusOff m3 : 6|1@1+ (1,0) [0|1] "" Vector__XXX
 SG_ ESP_a184_IBSTpRunoutInvalid m3 : 7|1@1+ (1,0) [0|1] "" Vector__XXX
 SG_ ESP_a185_IBSTFeedforwardBackup m3 : 8|1@1+ (1,0) [0|1] "" Vector__XXX
 SG_ ESP_a186_IBSTBrakeAppliedInvalid m3 : 9|1@1+ (1,0) [0|1] "" Vector__XXX
 SG_ ESP_a187_DIbtcRequestTimeout m3 : 10|1@1+ (1,0) [0|1] "" Vector__XXX
 SG_ ESP_a188_DIbtcRequestDLC m3 : 11|1@1+ (1,0) [0|1] "" Vector__XXX
 SG_ ESP_a189_DIbtcRequestChecksum m3 : 12|1@1+ (1,0) [0|1] "" Vector__XXX
 SG_ ESP_a190_DIbtcRequestCounter m3 : 13|1@1+ (1,0) [0|1] "" Vector__XXX
 SG_ ESP_a191_DIchassisControlTimeout m3 : 14|1@1+ (1,0) [0|1] "" Vector__XXX
 SG_ ESP_a192_DIchassisControlDLC m3 : 15|1@1+ (1,0) [0|1] "" Vector__XXX
 SG_ ESP_a193_DIchassisControlChecksu m3 : 16|1@1+ (1,0) [0|1] "" Vector__XXX
 SG_ ESP_a194_DIchassisControlCounter m3 : 17|1@1+ (1,0) [0|1] "" Vector__XXX
 SG_ ESP_a195_ptcStateInvalid m3 : 18|1@1+ (1,0) [0|1] "" Vector__XXX
 SG_ ESP_a196_DIsystemStatusTimeout m3 : 19|1@1+ (1,0) [0|1] "" Vector__XXX
 SG_ ESP_a197_DIsystemStatusDLC m3 : 20|1@1+ (1,0) [0|1] "" Vector__XXX
 SG_ ESP_a198_DIsystemStatusChecksum m3 : 21|1@1+ (1,0) [0|1] "" Vector__XXX
 SG_ ESP_a199_DIsystemStatusCounter m3 : 22|1@1+ (1,0) [0|1] "" Vector__XXX
 SG_ ESP_a200_reverseGearStuckHigh m3 : 23|1@1+ (1,0) [0|1] "" Vector__XXX
 SG_ ESP_a201_reverseGearStuckLow m3 : 24|1@1+ (1,0) [0|1] "" Vector__XXX
 SG_ ESP_a202_accelPedalInvalid m3 : 25|1@1+ (1,0) [0|1] "" Vector__XXX
 SG_ ESP_a203_DItorqueTimeout m3 : 26|1@1+ (1,0) [0|1] "" Vector__XXX
 SG_ ESP_a204_DItorqueDLC m3 : 27|1@1+ (1,0) [0|1] "" Vector__XXX
 SG_ ESP_a205_DItorqueChecksum m3 : 28|1@1+ (1,0) [0|1] "" Vector__XXX
 SG_ ESP_a206_DItorqueCounter m3 : 29|1@1+ (1,0) [0|1] "" Vector__XXX
 SG_ ESP_a207_DITorqueCommandInvalid m3 : 30|1@1+ (1,0) [0|1] "" Vector__XXX
 SG_ ESP_a208_DIRPMInvalid m3 : 31|1@1+ (1,0) [0|1] "" Vector__XXX
 SG_ ESP_a209_DITorqueActualInvalid m3 : 32|1@1+ (1,0) [0|1] "" Vector__XXX
 SG_ ESP_a210_DIStorqueTimeout m3 : 33|1@1+ (1,0) [0|1] "" Vector__XXX
 SG_ ESP_a211_DIStorqueDLC m3 : 34|1@1+ (1,0) [0|1] "" Vector__XXX
 SG_ ESP_a212_DIStorqueChecksum m3 : 35|1@1+ (1,0) [0|1] "" Vector__XXX
 SG_ ESP_a213_DIStorqueCounter m3 : 36|1@1+ (1,0) [0|1] "" Vector__XXX
 SG_ ESP_a214_DISTorqueCommandInvalid m3 : 37|1@1+ (1,0) [0|1] "" Vector__XXX
 SG_ ESP_a215_DISRPMInvalid m3 : 38|1@1+ (1,0) [0|1] "" Vector__XXX
 SG_ ESP_a216_DISTorqueActualInvalid m3 : 39|1@1+ (1,0) [0|1] "" Vector__XXX
 SG_ ESP_a217_DIvdcLeftTimeout m3 : 40|1@1+ (1,0) [0|1] "" Vector__XXX
 SG_ ESP_a218_DIvdcLeftDLC m3 : 41|1@1+ (1,0) [0|1] "" Vector__XXX
 SG_ ESP_a219_DIvdcLeftChecksum m3 : 42|1@1+ (1,0) [0|1] "" Vector__XXX
 SG_ ESP_a220_DIvdcLeftCounter m3 : 43|1@1+ (1,0) [0|1] "" Vector__XXX
 SG_ ESP_a221_DIvdcRightTimeout m3 : 44|1@1+ (1,0) [0|1] "" Vector__XXX
 SG_ ESP_a222_DIvdcRightDLC m3 : 45|1@1+ (1,0) [0|1] "" Vector__XXX
 SG_ ESP_a223_DIvdcRightChecksum m3 : 46|1@1+ (1,0) [0|1] "" Vector__XXX
 SG_ ESP_a224_DIvdcRightCounter m3 : 47|1@1+ (1,0) [0|1] "" Vector__XXX
 SG_ ESP_a225_configMismatch m3 : 48|1@1+ (1,0) [0|1] "" Vector__XXX
 SG_ ESP_a226_bdwRequestInvalid m3 : 49|1@1+ (1,0) [0|1] "" Vector__XXX
 SG_ ESP_a227_bdwRequestActiveInvalid m3 : 50|1@1+ (1,0) [0|1] "" Vector__XXX
 SG_ ESP_a228_GTWvinTimeout m3 : 51|1@1+ (1,0) [0|1] "" Vector__XXX
 SG_ ESP_a229_GTWvinDLC m3 : 52|1@1+ (1,0) [0|1] "" Vector__XXX
 SG_ ESP_a230_vinNotLearned m3 : 53|1@1+ (1,0) [0|1] "" Vector__XXX
 SG_ ESP_a231_storedVINMismatch m3 : 54|1@1+ (1,0) [0|1] "" Vector__XXX
 SG_ ESP_a232_PMstate2Timeout m3 : 55|1@1+ (1,0) [0|1] "" Vector__XXX
 SG_ ESP_a233_PMstate2Checksum m3 : 56|1@1+ (1,0) [0|1] "" Vector__XXX
 SG_ ESP_a234_PMstate2DLC m3 : 57|1@1+ (1,0) [0|1] "" Vector__XXX
 SG_ ESP_a235_PMstate2Counter m3 : 58|1@1+ (1,0) [0|1] "" Vector__XXX
 SG_ ESP_a236_ebrCommandStateInvalid m3 : 59|1@1+ (1,0) [0|1] "" Vector__XXX
 SG_ ESP_a237_vdcCommandStateInvalid m3 : 60|1@1+ (1,0) [0|1] "" Vector__XXX
 SG_ ESP_a238_UIodoTimeout m3 : 61|1@1+ (1,0) [0|1] "" Vector__XXX
 SG_ ESP_a239_UIodoDLC m3 : 62|1@1+ (1,0) [0|1] "" Vector__XXX
 SG_ ESP_a240_LVPowerStateTimeout m3 : 63|1@1+ (1,0) [0|1] "" Vector__XXX
 SG_ ESP_a241_LVPowerStateChecksum m4 : 4|1@1+ (1,0) [0|1] "" Vector__XXX
 SG_ ESP_a242_LVPowerStateDLC m4 : 5|1@1+ (1,0) [0|1] "" Vector__XXX
 SG_ ESP_a243_LVPowerStateCounter m4 : 6|1@1+ (1,0) [0|1] "" Vector__XXX
 SG_ ESP_a244_LVOffStateInvalid m4 : 7|1@1+ (1,0) [0|1] "" Vector__XXX
 SG_ ESP_a245_LVGoingDownStateInvalid m4 : 8|1@1+ (1,0) [0|1] "" Vector__XXX
 SG_ ESP_a246_VCFRONTsensorTimeout m4 : 9|1@1+ (1,0) [0|1] "" Vector__XXX
 SG_ ESP_a247_VCFRONTsensorDLC m4 : 10|1@1+ (1,0) [0|1] "" Vector__XXX
 SG_ ESP_a248_vdcBrkeTrqTarFrLInvalid m4 : 11|1@1+ (1,0) [0|1] "" Vector__XXX
 SG_ ESP_a249_vdcBrkeTrqTarFrRInvalid m4 : 12|1@1+ (1,0) [0|1] "" Vector__XXX
 SG_ ESP_a250_vdcBrkeTrqTarReLInvalid m4 : 13|1@1+ (1,0) [0|1] "" Vector__XXX
 SG_ ESP_a251_vdcBrkeTrqTarReRInvalid m4 : 14|1@1+ (1,0) [0|1] "" Vector__XXX
 SG_ ESP_a252_vdcWhlSlipLimFrLInvalid m4 : 15|1@1+ (1,0) [0|1] "" Vector__XXX
 SG_ ESP_a253_vdcWhlSlipLimFrRInvalid m4 : 16|1@1+ (1,0) [0|1] "" Vector__XXX
 SG_ ESP_a254_vdcWhlSlipLimReLInvalid m4 : 17|1@1+ (1,0) [0|1] "" Vector__XXX
 SG_ ESP_a255_vdcWhlSlipLimReRInvalid m4 : 18|1@1+ (1,0) [0|1] "" Vector__XXX
 SG_ ESP_a256_epbmStatusTimeout m4 : 19|1@1+ (1,0) [0|1] "" Vector__XXX
 SG_ ESP_a257_epbmStatusChecksum m4 : 20|1@1+ (1,0) [0|1] "" Vector__XXX
 SG_ ESP_a258_epbmStatusDLC m4 : 21|1@1+ (1,0) [0|1] "" Vector__XXX
 SG_ ESP_a259_epbmStatusCounter m4 : 22|1@1+ (1,0) [0|1] "" Vector__XXX
 SG_ ESP_a260_epblStatusTimeout m4 : 23|1@1+ (1,0) [0|1] "" Vector__XXX
 SG_ ESP_a261_epblStatusChecksum m4 : 24|1@1+ (1,0) [0|1] "" Vector__XXX
 SG_ ESP_a262_epblStatusDLC m4 : 25|1@1+ (1,0) [0|1] "" Vector__XXX
 SG_ ESP_a263_epblStatusCounter m4 : 26|1@1+ (1,0) [0|1] "" Vector__XXX
 SG_ ESP_a264_pumpSpeedLimitInvalid m4 : 27|1@1+ (1,0) [0|1] "" Vector__XXX
 SG_ ESP_a265_DIRELtorqueTimeout m4 : 28|1@1+ (1,0) [0|1] "" Vector__XXX
 SG_ ESP_a266_DIRELtorqueDLC m4 : 29|1@1+ (1,0) [0|1] "" Vector__XXX
 SG_ ESP_a267_DIRELtorqueChecksum m4 : 30|1@1+ (1,0) [0|1] "" Vector__XXX
 SG_ ESP_a268_DIRELtorqueCounter m4 : 31|1@1+ (1,0) [0|1] "" Vector__XXX
 SG_ ESP_a269_DIRELTorqueCommandInval m4 : 32|1@1+ (1,0) [0|1] "" Vector__XXX
 SG_ ESP_a270_DIRELRPMInvalid m4 : 33|1@1+ (1,0) [0|1] "" Vector__XXX
 SG_ ESP_a271_DIRELTorqueActualInvali m4 : 34|1@1+ (1,0) [0|1] "" Vector__XXX
 SG_ ESP_a272_DIRERtorqueTimeout m4 : 35|1@1+ (1,0) [0|1] "" Vector__XXX
 SG_ ESP_a273_DIRERtorqueDLC m4 : 36|1@1+ (1,0) [0|1] "" Vector__XXX
 SG_ ESP_a274_DIRERtorqueChecksum m4 : 37|1@1+ (1,0) [0|1] "" Vector__XXX
 SG_ ESP_a275_DIRERtorqueCounter m4 : 38|1@1+ (1,0) [0|1] "" Vector__XXX
 SG_ ESP_a276_DIRERTorqueCommandInval m4 : 39|1@1+ (1,0) [0|1] "" Vector__XXX
 SG_ ESP_a277_DIRERRPMInvalid m4 : 40|1@1+ (1,0) [0|1] "" Vector__XXX
 SG_ ESP_a278_DIRERTorqueActualInvali m4 : 41|1@1+ (1,0) [0|1] "" Vector__XXX
 SG_ ESP_a279_lifetimeManagementOverr m4 : 42|1@1+ (1,0) [0|1] "" Vector__XXX
 SG_ ESP_a280_trackModeABSEnabled m4 : 43|1@1+ (1,0) [0|1] "" Vector__XXX
 SG_ ESP_a281_trackModeABSdisabled m4 : 44|1@1+ (1,0) [0|1] "" Vector__XXX
 SG_ ESP_a282_trackModeABSRequestInva m4 : 45|1@1+ (1,0) [0|1] "" Vector__XXX
 SG_ ESP_a283_secondaryCollisionMitig m4 : 46|1@1+ (1,0) [0|1] "" Vector__XXX
 SG_ ESP_a284_scmRequestInvalidChecks m4 : 47|1@1+ (1,0) [0|1] "" Vector__XXX
 SG_ ESP_a285_scmRequestDLC m4 : 48|1@1+ (1,0) [0|1] "" Vector__XXX
 SG_ ESP_a286_hydroplaneDetected m4 : 49|1@1+ (1,0) [0|1] "" Vector__XXX
 SG_ ESP_a287_failedBrakeCircuitDetec m4 : 50|1@1+ (1,0) [0|1] "" Vector__XXX
 SG_ ESP_a288_leftBusOff m4 : 51|1@1+ (1,0) [0|1] "" Vector__XXX
 SG_ ESP_a289_leftBusPassive m4 : 52|1@1+ (1,0) [0|1] "" Vector__XXX
 SG_ ESP_a290_brakeBusOff m4 : 53|1@1+ (1,0) [0|1] "" Vector__XXX
 SG_ ESP_a291_brakeBusPassive m4 : 54|1@1+ (1,0) [0|1] "" Vector__XXX
 SG_ ESP_a292_PEPSstatusTimeout m4 : 55|1@1+ (1,0) [0|1] "" Vector__XXX
 SG_ ESP_a293_PEPSstatusDLC m4 : 56|1@1+ (1,0) [0|1] "" Vector__XXX
 SG_ ESP_a294_PEPSstatusChecksum m4 : 57|1@1+ (1,0) [0|1] "" Vector__XXX
 SG_ ESP_a295_PEPSstatusCounter m4 : 58|1@1+ (1,0) [0|1] "" Vector__XXX
 SG_ ESP_a296_roadWheelAngleHealthDeg m4 : 59|1@1+ (1,0) [0|1] "" Vector__XXX
 SG_ ESP_a297_roadWheelAngleHealthFau m4 : 60|1@1+ (1,0) [0|1] "" Vector__XXX
 SG_ ESP_a298_RSArearSteerStatusTimeo m4 : 61|1@1+ (1,0) [0|1] "" Vector__XXX
 SG_ ESP_a299_RSArearSteerStatusDLC m4 : 62|1@1+ (1,0) [0|1] "" Vector__XXX
 SG_ ESP_a300_RSArearSteerStatusCheck m4 : 63|1@1+ (1,0) [0|1] "" Vector__XXX
 SG_ ESP_a301_PEPSstatusCounter m5 : 4|1@1+ (1,0) [0|1] "" Vector__XXX
 SG_ ESP_a302_rearRoadWheelAngleHealt m5 : 5|1@1+ (1,0) [0|1] "" Vector__XXX
 SG_ ESP_a303_rearRoadWheelAngleHealt m5 : 6|1@1+ (1,0) [0|1] "" Vector__XXX
 SG_ ESP_a304_rearVCLVPowerStateTimeo m5 : 7|1@1+ (1,0) [0|1] "" Vector__XXX
 SG_ ESP_a305_rearVCLVPowerStateDLC m5 : 8|1@1+ (1,0) [0|1] "" Vector__XXX
 SG_ ESP_a306_rearVCLVPowerStateCheck m5 : 9|1@1+ (1,0) [0|1] "" Vector__XXX
 SG_ ESP_a307_rearVCLVPowerStateCount m5 : 10|1@1+ (1,0) [0|1] "" Vector__XXX
 SG_ ESP_a308_evacFillNotComplete m5 : 11|1@1+ (1,0) [0|1] "" Vector__XXX
 SG_ ESP_a309_factoryModeActive m5 : 12|1@1+ (1,0) [0|1] "" Vector__XXX
 SG_ ESP_a310_brakeLatencyReductionAc m5 : 13|1@1+ (1,0) [0|1] "" Vector__XXX
 SG_ ESP_a311_aesActive m5 : 14|1@1+ (1,0) [0|1] "" Vector__XXX
 SG_ ESP_a312_undefinedAlertDetected m5 : 15|1@1+ (1,0) [0|1] "" Vector__XXX
 SG_ ESP_a313_cdpRequestStateInvalid m5 : 16|1@1+ (1,0) [0|1] "" Vector__XXX
 SG_ ESP_a314_aesFault m5 : 17|1@1+ (1,0) [0|1] "" Vector__XXX
 SG_ ESP_a315_EMCBackup11Timeout m5 : 18|1@1+ (1,0) [0|1] "" Vector__XXX
 SG_ ESP_a316_EMCBackup11DLC m5 : 19|1@1+ (1,0) [0|1] "" Vector__XXX
 SG_ ESP_a317_EMCBackup11Checksum m5 : 20|1@1+ (1,0) [0|1] "" Vector__XXX
 SG_ ESP_a318_EMCBackup11Counter m5 : 21|1@1+ (1,0) [0|1] "" Vector__XXX
 SG_ ESP_a319_AES_BackupActuatorActiv m5 : 22|1@1+ (1,0) [0|1] "" Vector__XXX
 SG_ ESP_a320_DPB_actuator1Counter m5 : 23|1@1+ (1,0) [0|1] "" Vector__XXX
 SG_ ESP_a321_DPB_actuator1Checksum m5 : 24|1@1+ (1,0) [0|1] "" Vector__XXX
 SG_ ESP_a322_DPB_actuator1DLC m5 : 25|1@1+ (1,0) [0|1] "" Vector__XXX
 SG_ ESP_a323_DPB_actuator1Timeout m5 : 26|1@1+ (1,0) [0|1] "" Vector__XXX
 SG_ ESP_a324_DPB_actuator2Counter m5 : 27|1@1+ (1,0) [0|1] "" Vector__XXX
 SG_ ESP_a325_DPB_actuator2Checksum m5 : 28|1@1+ (1,0) [0|1] "" Vector__XXX
 SG_ ESP_a326_DPB_actuator2DLC m5 : 29|1@1+ (1,0) [0|1] "" Vector__XXX
 SG_ ESP_a327_DPB_actuator2Timeout m5 : 30|1@1+ (1,0) [0|1] "" Vector__XXX
 SG_ ESP_a328_DPB_actuator3Counter m5 : 31|1@1+ (1,0) [0|1] "" Vector__XXX
 SG_ ESP_a329_DPB_actuator3Checksum m5 : 32|1@1+ (1,0) [0|1] "" Vector__XXX
 SG_ ESP_a330_DPB_actuator3DLC m5 : 33|1@1+ (1,0) [0|1] "" Vector__XXX
 SG_ ESP_a331_DPB_actuator3Timeout m5 : 34|1@1+ (1,0) [0|1] "" Vector__XXX
 SG_ ESP_a332_PressureSensorValHigh m5 : 35|1@1+ (1,0) [0|1] "" Vector__XXX
 SG_ ESP_a333_ActCircuitNoPressure m5 : 36|1@1+ (1,0) [0|1] "" Vector__XXX
 SG_ ESP_a334_BrakePedalAppliedInvali m5 : 37|1@1+ (1,0) [0|1] "" Vector__XXX
 SG_ ESP_a335_LdmFxTarBrakeActInvalid m5 : 38|1@1+ (1,0) [0|1] "" Vector__XXX
 SG_ ESP_a336_FxTargetDriverInvalid m5 : 39|1@1+ (1,0) [0|1] "" Vector__XXX
 SG_ ESP_a337_pReductionPotentialInva m5 : 40|1@1+ (1,0) [0|1] "" Vector__XXX
 SG_ ESP_a338_pRunoutInvalid m5 : 41|1@1+ (1,0) [0|1] "" Vector__XXX
 SG_ ESP_a339_sInputRodInvalid m5 : 42|1@1+ (1,0) [0|1] "" Vector__XXX
 SG_ ESP_a340_RollerBenchMisuse m5 : 43|1@1+ (1,0) [0|1] "" Vector__XXX
 SG_ ESP_a341_EnhancedPressureBuildAc m5 : 44|1@1+ (1,0) [0|1] "" Vector__XXX
 SG_ ESP_a342_EnhancedPressureBuildNo m5 : 45|1@1+ (1,0) [0|1] "" Vector__XXX
 SG_ ESP_a343_EnhancedPressureBuildLt m5 : 46|1@1+ (1,0) [0|1] "" Vector__XXX
 SG_ ESP_a344_DIbrakeCommandCounter m5 : 47|1@1+ (1,0) [0|1] "" Vector__XXX
 SG_ ESP_a345_DIbrakeCommandChecksum m5 : 48|1@1+ (1,0) [0|1] "" Vector__XXX
 SG_ ESP_a346_DIbrakeCommandDLC m5 : 49|1@1+ (1,0) [0|1] "" Vector__XXX
 SG_ ESP_a347_DIbrakeCommandTimeout m5 : 50|1@1+ (1,0) [0|1] "" Vector__XXX
 SG_ ESP_a348_brakeCmdStateInvalid m5 : 51|1@1+ (1,0) [0|1] "" Vector__XXX
 SG_ ESP_a349_ForceLampToRed m5 : 52|1@1+ (1,0) [0|1] "" Vector__XXX
 SG_ ESP_a350_ActuatorOff m5 : 53|1@1+ (1,0) [0|1] "" Vector__XXX
 SG_ ESP_a351_ActuatorYellowLampReque m5 : 54|1@1+ (1,0) [0|1] "" Vector__XXX
 SG_ ESP_a352_ActuatorLDMFailure m5 : 55|1@1+ (1,0) [0|1] "" Vector__XXX
 SG_ ESP_a353_PressureSensorImplausHi m5 : 56|1@1+ (1,0) [0|1] "" Vector__XXX
 SG_ ESP_a354_HBCRequestInvalid m5 : 57|1@1+ (1,0) [0|1] "" Vector__XXX
 SG_ ESP_a355_RecuStatusActInvalid m5 : 58|1@1+ (1,0) [0|1] "" Vector__XXX
 SG_ ESP_a356_DIFAxleTorqueInvalid m5 : 59|1@1+ (1,0) [0|1] "" Vector__XXX
 SG_ ESP_a357_DIRAxleTorqueInvalid m5 : 60|1@1+ (1,0) [0|1] "" Vector__XXX
 SG_ ESP_a358_externalActuatorFallbac m5 : 61|1@1+ (1,0) [0|1] "" Vector__XXX
 SG_ ESP_a359_externalActuatorNoExtRe m5 : 62|1@1+ (1,0) [0|1] "" Vector__XXX
 SG_ ESP_a360_BBbrakeActuationTimeout m5 : 63|1@1+ (1,0) [0|1] "" Vector__XXX
 SG_ ESP_a361_BBbrakeActuationDLC m6 : 4|1@1+ (1,0) [0|1] "" Vector__XXX
 SG_ ESP_a362_BBbrakeActuationChecksu m6 : 5|1@1+ (1,0) [0|1] "" Vector__XXX
 SG_ ESP_a363_BBbrakeActuationCounter m6 : 6|1@1+ (1,0) [0|1] "" Vector__XXX
 SG_ ESP_a364_DIgearInvalid m6 : 7|1@1+ (1,0) [0|1] "" Vector__XXX
 SG_ ESP_a365_TCSInputQualityTooLow m6 : 8|1@1+ (1,0) [0|1] "" Vector__XXX
 SG_ ESP_a366_ActuatorBlendingModeReq m6 : 9|1@1+ (1,0) [0|1] "" Vector__XXX
 SG_ ESP_a367_CBDS_fillBufferThreshol m6 : 10|1@1+ (1,0) [0|1] "" Vector__XXX
 SG_ ESP_a368_CBDS_fmeInternalEvent m6 : 11|1@1+ (1,0) [0|1] "" Vector__XXX
 SG_ ESP_a369_LargeLeakageDetectedByD m6 : 12|1@1+ (1,0) [0|1] "" Vector__XXX
 SG_ ESP_a370_DPB_actuator4Timeout m6 : 13|1@1+ (1,0) [0|1] "" Vector__XXX
 SG_ ESP_a371_DPB_actuator4DLC m6 : 14|1@1+ (1,0) [0|1] "" Vector__XXX
 SG_ ESP_a372_DPB_actuator4Checksum m6 : 15|1@1+ (1,0) [0|1] "" Vector__XXX
 SG_ ESP_a373_DPB_actuator4Counter m6 : 16|1@1+ (1,0) [0|1] "" Vector__XXX
 SG_ ESP_a374_StatInvalid_DI_FullSNA m6 : 17|1@1+ (1,0) [0|1] "" Vector__XXX
 SG_ ESP_a375_PM_locStateCounter m6 : 18|1@1+ (1,0) [0|1] "" Vector__XXX
 SG_ ESP_a376_PM_locStateChecksum m6 : 19|1@1+ (1,0) [0|1] "" Vector__XXX
 SG_ ESP_a377_PM_locStateDLC m6 : 20|1@1+ (1,0) [0|1] "" Vector__XXX
 SG_ ESP_a378_PM_locStateTimeout m6 : 21|1@1+ (1,0) [0|1] "" Vector__XXX

BO_ 1621 ESP_udsResponse: 8 ESP
 SG_ ESP_udsResponseData : 7|64@0+ (1,0) [0|1.84467440737e+19] "" Vector__XXX

BO_ 373 ESP_wheelSpeeds: 8 ESP
 SG_ ESP_wheelSpeedFrL : 0|13@1+ (0.042,0) [0|343.98] "km/h" Vector__XXX
 SG_ ESP_wheelSpeedFrR : 13|13@1+ (0.042,0) [0|343.98] "km/h" Vector__XXX
 SG_ ESP_wheelSpeedReL : 26|13@1+ (0.042,0) [0|343.98] "km/h" Vector__XXX
 SG_ ESP_wheelSpeedReR : 39|13@1+ (0.042,0) [0|343.98] "km/h" Vector__XXX

BO_ 888 GTW_ECall: 1 GTW
 SG_ GTW_GTW_SOS_ECALL_RQST : 0|1@1+ (1,0) [0|1] "" Vector__XXX
 SG_ GTW_LTE_ECALL_LOCK : 1|1@1+ (1,0) [0|1] "" Vector__XXX

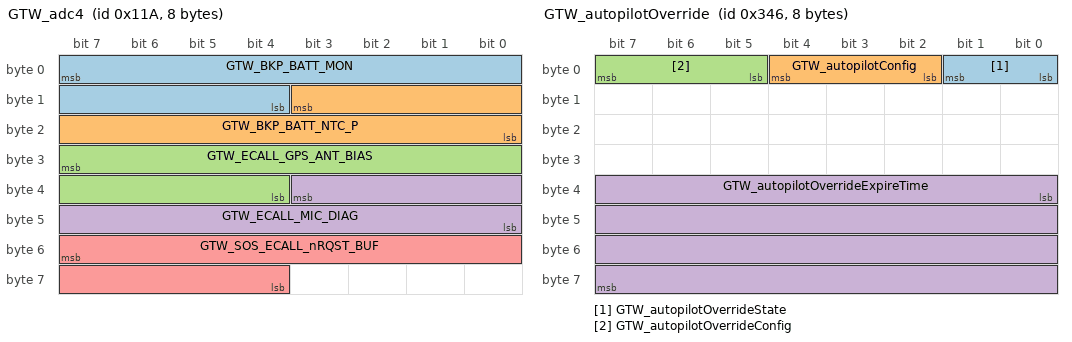
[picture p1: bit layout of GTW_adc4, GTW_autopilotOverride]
BO_ 282 GTW_adc4: 8 GTW
 SG_ GTW_BKP_BATT_MON : 7|12@0+ (1,0) [0|4094] "mV" Vector__XXX
 SG_ GTW_BKP_BATT_NTC_P : 11|12@0+ (1,0) [0|4094] "mV" Vector__XXX
 SG_ GTW_ECALL_GPS_ANT_BIAS : 31|12@0+ (1,0) [0|4094] "mV" Vector__XXX
 SG_ GTW_ECALL_MIC_DIAG : 35|12@0+ (1,0) [0|4094] "mV" Vector__XXX
 SG_ GTW_SOS_ECALL_nRQST_BUF : 55|12@0+ (1,0) [0|4094] "mV" Vector__XXX

BO_ 1384 GTW_alertLog: 8 GTW
 SG_ GTW_alertID M : 0|9@1+ (1,0) [0|511] "" Vector__XXX
 SG_ GTW_alertState : 15|1@1+ (1,0) [0|1] "" Vector__XXX
 SG_ GTW_a014_crcVersion m14 : 16|32@1+ (1,0) [0|4294967295] "" Vector__XXX
 SG_ GTW_a015_crcVersion m15 : 16|32@1+ (1,0) [0|4294967295] "" Vector__XXX
 SG_ GTW_a016_crcVersion m16 : 16|32@1+ (1,0) [0|4294967295] "" Vector__XXX
 SG_ GTW_a017_crcVersion m17 : 16|32@1+ (1,0) [0|4294967295] "" Vector__XXX
 SG_ GTW_a018_crcVersion m18 : 16|32@1+ (1,0) [0|4294967295] "" Vector__XXX
 SG_ GTW_a019_crcVersion m19 : 16|32@1+ (1,0) [0|4294967295] "" Vector__XXX
 SG_ GTW_a020_crcVersion m20 : 16|32@1+ (1,0) [0|4294967295] "" Vector__XXX
 SG_ GTW_a021_crcVersion m21 : 16|32@1+ (1,0) [0|4294967295] "" Vector__XXX
 SG_ GTW_a022_crcVersion m22 : 16|32@1+ (1,0) [0|4294967295] "" Vector__XXX
 SG_ GTW_a023_crcVersion m23 : 16|32@1+ (1,0) [0|4294967295] "" Vector__XXX
 SG_ GTW_a024_crcVersion m24 : 16|32@1+ (1,0) [0|4294967295] "" Vector__XXX
 SG_ GTW_a025_crcVersion m25 : 16|32@1+ (1,0) [0|4294967295] "" Vector__XXX
 SG_ GTW_a026_crcVersion m26 : 16|32@1+ (1,0) [0|4294967295] "" Vector__XXX
 SG_ GTW_a027_crcVersion m27 : 16|32@1+ (1,0) [0|4294967295] "" Vector__XXX
 SG_ GTW_a028_crcVersion m28 : 16|32@1+ (1,0) [0|4294967295] "" Vector__XXX
 SG_ GTW_a029_crcVersion m29 : 16|32@1+ (1,0) [0|4294967295] "" Vector__XXX
 SG_ GTW_a030_crcVersion m30 : 16|32@1+ (1,0) [0|4294967295] "" Vector__XXX
 SG_ GTW_a031_crcVersion m31 : 16|32@1+ (1,0) [0|4294967295] "" Vector__XXX
 SG_ GTW_a032_crcVersion m32 : 16|32@1+ (1,0) [0|4294967295] "" Vector__XXX
 SG_ GTW_a033_crcVersion m33 : 16|32@1+ (1,0) [0|4294967295] "" Vector__XXX
 SG_ GTW_a034_crcVersion m34 : 16|32@1+ (1,0) [0|4294967295] "" Vector__XXX
 SG_ GTW_a035_crcVersion m35 : 16|32@1+ (1,0) [0|4294967295] "" Vector__XXX
 SG_ GTW_a036_crcVersion m36 : 16|32@1+ (1,0) [0|4294967295] "" Vector__XXX
 SG_ GTW_a037_crcVersion m37 : 16|32@1+ (1,0) [0|4294967295] "" Vector__XXX
 SG_ GTW_a038_crcVersion m38 : 16|32@1+ (1,0) [0|4294967295] "" Vector__XXX
 SG_ GTW_a039_crcVersion m39 : 16|32@1+ (1,0) [0|4294967295] "" Vector__XXX
 SG_ GTW_a040_crcVersion m40 : 16|32@1+ (1,0) [0|4294967295] "" Vector__XXX
 SG_ GTW_a041_crcVersion m41 : 16|32@1+ (1,0) [0|4294967295] "" Vector__XXX
 SG_ GTW_a042_crcVersion m42 : 16|32@1+ (1,0) [0|4294967295] "" Vector__XXX
 SG_ GTW_a043_crcVersion m43 : 16|32@1+ (1,0) [0|4294967295] "" Vector__XXX
 SG_ GTW_a045_crcVersion m45 : 16|32@1+ (1,0) [0|4294967295] "" Vector__XXX
 SG_ GTW_a046_crcVersion m46 : 16|32@1+ (1,0) [0|4294967295] "" Vector__XXX
 SG_ GTW_a047_crcVersion m47 : 16|32@1+ (1,0) [0|4294967295] "" Vector__XXX
 SG_ GTW_a048_crcVersion m48 : 16|32@1+ (1,0) [0|4294967295] "" Vector__XXX
 SG_ GTW_a049_headerError m49 : 16|2@1+ (1,0) [0|3] "" Vector__XXX
 SG_ GTW_a054_crcVersion m54 : 16|32@1+ (1,0) [0|4294967295] "" Vector__XXX
 SG_ GTW_a055_crcVersion m55 : 16|32@1+ (1,0) [0|4294967295] "" Vector__XXX
 SG_ GTW_a062_bmpWatchdogReason m62 : 16|2@1+ (1,0) [0|3] "" Vector__XXX
 SG_ GTW_a063_VEH_faultConfinement m63 : 16|2@1+ (1,0) [0|3] "" Vector__XXX
 SG_ GTW_a064_CH_faultConfinement m64 : 16|2@1+ (1,0) [0|3] "" Vector__XXX
 SG_ GTW_a065_PARTY_faultConfinement m65 : 16|2@1+ (1,0) [0|3] "" Vector__XXX
 SG_ GTW_a066_type m66 : 16|8@1+ (1,0) [0|255] "" Vector__XXX
 SG_ GTW_a066_exceptionCfgId m66 : 24|8@1+ (1,0) [0|255] "" Vector__XXX
 SG_ GTW_a066_uptime m66 : 32|32@1+ (1,0) [0|4294967295] "" Vector__XXX
 SG_ GTW_a068_codeKeyMissing m68 : 16|1@1+ (1,0) [0|1] "" Vector__XXX
 SG_ GTW_a068_cmdKeyMissing m68 : 17|1@1+ (1,0) [0|1] "" Vector__XXX
 SG_ GTW_a069_sdIntStatusErrs m69 : 16|1@1+ (1,0) [0|1] "" Vector__XXX
 SG_ GTW_a069_sdTimeout m69 : 17|1@1+ (1,0) [0|1] "" Vector__XXX
 SG_ GTW_a069_sdCmdErr m69 : 18|1@1+ (1,0) [0|1] "" Vector__XXX
 SG_ GTW_a069_sdWriteErr m69 : 19|1@1+ (1,0) [0|1] "" Vector__XXX
 SG_ GTW_a069_sdReadErr m69 : 20|1@1+ (1,0) [0|1] "" Vector__XXX
 SG_ GTW_a069_autoCmd12Err m69 : 21|1@1+ (1,0) [0|1] "" Vector__XXX
 SG_ GTW_a072_updtFailureMask m72 : 16|32@1+ (1,0) [0|4294967295] "" Vector__XXX
 SG_ GTW_a077_bmpPmicErrorType m77 : 16|3@1+ (1,0) [0|7] "" Vector__XXX
 SG_ GTW_a078_loadPercent m78 : 16|7@1+ (1,0) [0|127] "percent" Vector__XXX
 SG_ GTW_a079_loadPercent m79 : 16|7@1+ (1,0) [0|127] "percent" Vector__XXX
 SG_ GTW_a080_loadPercent m80 : 16|7@1+ (1,0) [0|127] "percent" Vector__XXX
 SG_ GTW_a081_canId m81 : 16|11@1+ (1,0) [0|2047] "" Vector__XXX
 SG_ GTW_a081_ISOTPmsgType m81 : 27|2@1+ (1,0) [0|3] "" Vector__XXX
 SG_ GTW_a081_udsSID m81 : 32|30@1+ (1,0) [0|1073741823] "" Vector__XXX
 SG_ GTW_a097_crcVersion m97 : 16|32@1+ (1,0) [0|4294967295] "" Vector__XXX
 SG_ GTW_a098_crcVersion m98 : 16|32@1+ (1,0) [0|4294967295] "" Vector__XXX
 SG_ GTW_a099_crcVersion m99 : 16|32@1+ (1,0) [0|4294967295] "" Vector__XXX
 SG_ GTW_a100_crcVersion m100 : 16|32@1+ (1,0) [0|4294967295] "" Vector__XXX
 SG_ GTW_a101_switchStuck m101 : 16|1@1+ (1,0) [0|1] "" Vector__XXX
 SG_ GTW_a101_ETH_SW_nINT m101 : 17|1@1+ (1,0) [0|1] "" Vector__XXX
 SG_ GTW_a106_crcVersion m106 : 16|32@1+ (1,0) [0|4294967295] "" Vector__XXX
 SG_ GTW_a107_crcVersion m107 : 16|32@1+ (1,0) [0|4294967295] "" Vector__XXX
 SG_ GTW_a108_crcVersion m108 : 16|32@1+ (1,0) [0|4294967295] "" Vector__XXX
 SG_ GTW_a113_bus m113 : 16|8@1+ (1,0) [0|255] "" Vector__XXX
 SG_ GTW_a113_id m113 : 24|11@1+ (1,0) [0|2047] "" Vector__XXX
 SG_ GTW_a117_MC_RGM_DES m117 : 16|32@1+ (1,0) [0|4294967295] "" Vector__XXX
 SG_ GTW_a118_MC_RGM_FES m118 : 16|32@1+ (1,0) [0|4294967295] "" Vector__XXX
 SG_ GTW_a122_BDY_faultConfinement m122 : 16|2@1+ (1,0) [0|3] "" Vector__XXX
 SG_ GTW_a129_crcVersion m129 : 16|32@1+ (1,0) [0|4294967295] "" Vector__XXX
 SG_ GTW_a138_sdLifetimeUsed m138 : 16|8@1+ (1,0) [0|255] "" Vector__XXX
 SG_ GTW_a139_crcVersion m139 : 16|32@1+ (1,0) [0|4294967295] "" Vector__XXX
 SG_ GTW_a150_crcVersion m150 : 16|32@1+ (1,0) [0|4294967295] "" Vector__XXX
 SG_ GTW_a151_crcVersion m151 : 16|32@1+ (1,0) [0|4294967295] "" Vector__XXX
 SG_ GTW_a155_crcVersion m155 : 16|32@1+ (1,0) [0|4294967295] "" Vector__XXX
 SG_ GTW_a165_crcVersion m165 : 16|32@1+ (1,0) [0|4294967295] "" Vector__XXX
 SG_ GTW_a169_TPMS_pressureFL m169 : 16|8@1+ (1,0) [0|255] "" Vector__XXX
 SG_ GTW_a170_TPMS_pressureFR m170 : 16|8@1+ (1,0) [0|255] "" Vector__XXX
 SG_ GTW_a171_TPMS_pressureRL m171 : 16|8@1+ (1,0) [0|255] "" Vector__XXX
 SG_ GTW_a172_TPMS_pressureRR m172 : 16|8@1+ (1,0) [0|255] "" Vector__XXX
 SG_ GTW_a173_TPMS_pressureFL m173 : 16|8@1+ (1,0) [0|255] "" Vector__XXX
 SG_ GTW_a174_TPMS_pressureFR m174 : 16|8@1+ (1,0) [0|255] "" Vector__XXX
 SG_ GTW_a175_TPMS_pressureRL m175 : 16|8@1+ (1,0) [0|255] "" Vector__XXX
 SG_ GTW_a176_TPMS_pressureRR m176 : 16|8@1+ (1,0) [0|255] "" Vector__XXX
 SG_ GTW_a219_crcVersion m219 : 16|32@1+ (1,0) [0|4294967295] "" Vector__XXX
 SG_ GTW_a223_crcVersion m223 : 16|32@1+ (1,0) [0|4294967295] "" Vector__XXX
 SG_ GTW_a226_crcVersion m226 : 16|32@1+ (1,0) [0|4294967295] "" Vector__XXX
 SG_ GTW_a227_crcVersion m227 : 16|32@1+ (1,0) [0|4294967295] "" Vector__XXX
 SG_ GTW_a228_crcVersion m228 : 16|32@1+ (1,0) [0|4294967295] "" Vector__XXX
 SG_ GTW_a244_crcVersion m244 : 16|32@1+ (1,0) [0|4294967295] "" Vector__XXX
 SG_ GTW_a245_page0ControlValue m245 : 16|16@1+ (1,0) [0|65535] "" Vector__XXX
 SG_ GTW_a245_page1ControlValue m245 : 32|16@1+ (1,0) [0|65535] "" Vector__XXX
 SG_ GTW_a261_failureReason m261 : 16|3@1+ (1,0) [0|7] "" Vector__XXX
 SG_ GTW_a261_failureData1 m261 : 24|16@1+ (1,0) [0|65535] "" Vector__XXX
 SG_ GTW_a261_failureData2 m261 : 40|16@1+ (1,0) [0|65535] "" Vector__XXX
 SG_ GTW_a273_crcVersion m273 : 16|32@1+ (1,0) [0|4294967295] "" Vector__XXX
 SG_ GTW_a274_crcVersion m274 : 16|32@1+ (1,0) [0|4294967295] "" Vector__XXX
 SG_ GTW_a277_mitigationFailureReason m277 : 16|3@1+ (1,0) [0|7] "" Vector__XXX
 SG_ GTW_a279_repeatCount m279 : 16|8@1+ (1,0) [0|255] "" Vector__XXX
 SG_ GTW_a279_failureReason m279 : 24|3@1+ (1,0) [0|7] "" Vector__XXX
 SG_ GTW_a279_failureData1 m279 : 32|16@1+ (1,0) [0|65535] "" Vector__XXX
 SG_ GTW_a279_failureData2 m279 : 48|16@1+ (1,0) [0|65535] "" Vector__XXX
 SG_ GTW_a309_crcVersion m309 : 16|32@1+ (1,0) [0|4294967295] "" Vector__XXX
 SG_ GTW_a317_status m317 : 16|3@1+ (1,0) [0|7] "" Vector__XXX
 SG_ GTW_a317_errorCode m317 : 19|5@1+ (1,0) [0|31] "" Vector__XXX
 SG_ GTW_a329_crcVersion m329 : 16|32@1+ (1,0) [0|4294967295] "" Vector__XXX
 SG_ GTW_a330_crcVersion m330 : 16|32@1+ (1,0) [0|4294967295] "" Vector__XXX
 SG_ GTW_a331_crcVersion m331 : 16|32@1+ (1,0) [0|4294967295] "" Vector__XXX
 SG_ GTW_a342_crcVersion m342 : 16|32@1+ (1,0) [0|4294967295] "" Vector__XXX
 SG_ GTW_a348_crcVersion m348 : 16|32@1+ (1,0) [0|4294967295] "" Vector__XXX
 SG_ GTW_a349_crcVersion m349 : 16|32@1+ (1,0) [0|4294967295] "" Vector__XXX
 SG_ GTW_a354_crcVersion m354 : 16|32@1+ (1,0) [0|4294967295] "" Vector__XXX
 SG_ GTW_a355_crcVersion m355 : 16|32@1+ (1,0) [0|4294967295] "" Vector__XXX
 SG_ GTW_a358_crcVersion m358 : 16|32@1+ (1,0) [0|4294967295] "" Vector__XXX
 SG_ GTW_a359_crcVersion m359 : 16|32@1+ (1,0) [0|4294967295] "" Vector__XXX
 SG_ GTW_a360_crcVersion m360 : 16|32@1+ (1,0) [0|4294967295] "" Vector__XXX
 SG_ GTW_a361_crcVersion m361 : 16|32@1+ (1,0) [0|4294967295] "" Vector__XXX
 SG_ GTW_a362_crcVersion m362 : 16|32@1+ (1,0) [0|4294967295] "" Vector__XXX
 SG_ GTW_a363_crcVersion m363 : 16|32@1+ (1,0) [0|4294967295] "" Vector__XXX
 SG_ GTW_a364_crcVersion m364 : 16|32@1+ (1,0) [0|4294967295] "" Vector__XXX
 SG_ GTW_a380_crcVersion m380 : 16|32@1+ (1,0) [0|4294967295] "" Vector__XXX
 SG_ GTW_a381_crcVersion m381 : 16|32@1+ (1,0) [0|4294967295] "" Vector__XXX
 SG_ GTW_a382_crcVersion m382 : 16|32@1+ (1,0) [0|4294967295] "" Vector__XXX
 SG_ GTW_a383_crcVersion m383 : 16|32@1+ (1,0) [0|4294967295] "" Vector__XXX
 SG_ GTW_a384_crcVersion m384 : 16|32@1+ (1,0) [0|4294967295] "" Vector__XXX
 SG_ GTW_a385_crcVersion m385 : 16|32@1+ (1,0) [0|4294967295] "" Vector__XXX
 SG_ GTW_a386_crcVersion m386 : 16|32@1+ (1,0) [0|4294967295] "" Vector__XXX
 SG_ GTW_a409_RES_CAUSE m409 : 16|32@1+ (1,0) [0|4294967295] "" Vector__XXX
 SG_ GTW_a410_RES_CAUSE2 m410 : 16|32@1+ (1,0) [0|4294967295] "" Vector__XXX

BO_ 62 GTW_alertMatrix: 8 GTW
 SG_ GTW_matrixIndex M : 0|4@1+ (1,0) [0|15] "" Vector__XXX
 SG_ GTW_w001_canEthTxQueue m0 : 4|1@1+ (1,0) [0|1] "" Vector__XXX
 SG_ GTW_w002_taskError m0 : 5|1@1+ (1,0) [0|1] "" Vector__XXX
 SG_ GTW_w003_logWriteRecord m0 : 6|1@1+ (1,0) [0|1] "" Vector__XXX
 SG_ GTW_w004_mallocHook m0 : 7|1@1+ (1,0) [0|1] "" Vector__XXX
 SG_ GTW_w005_stackOverflowHook m0 : 8|1@1+ (1,0) [0|1] "" Vector__XXX
 SG_ GTW_w006_ifTxOutputFull m0 : 9|1@1+ (1,0) [0|1] "" Vector__XXX
 SG_ GTW_w007_ifRxBufError m0 : 10|1@1+ (1,0) [0|1] "" Vector__XXX
 SG_ GTW_w008_ifPbufAllocError m0 : 11|1@1+ (1,0) [0|1] "" Vector__XXX
 SG_ GTW_w009_lateTask m0 : 12|1@1+ (1,0) [0|1] "" Vector__XXX
 SG_ GTW_w010_wdTaskCount m0 : 13|1@1+ (1,0) [0|1] "" Vector__XXX
 SG_ GTW_w011_cancoreWatchdog m0 : 14|1@1+ (1,0) [0|1] "" Vector__XXX
 SG_ GTW_w012_maincoreWatchdog m0 : 15|1@1+ (1,0) [0|1] "" Vector__XXX
 SG_ GTW_w014_APSversionMismatch m0 : 17|1@1+ (1,0) [0|1] "" Vector__XXX
 SG_ GTW_w015_DIFversionMismatch m0 : 18|1@1+ (1,0) [0|1] "" Vector__XXX
 SG_ GTW_w016_BLEEPCENTERversionMisma m0 : 19|1@1+ (1,0) [0|1] "" Vector__XXX
 SG_ GTW_w017_BMSversionMismatch m0 : 20|1@1+ (1,0) [0|1] "" Vector__XXX
 SG_ GTW_w018_CMPversionMismatch m0 : 21|1@1+ (1,0) [0|1] "" Vector__XXX
 SG_ GTW_w019_CPversionMismatch m0 : 22|1@1+ (1,0) [0|1] "" Vector__XXX
 SG_ GTW_w020_DIRversionMismatch m0 : 23|1@1+ (1,0) [0|1] "" Vector__XXX
 SG_ GTW_w021_EPAS3PversionMismatch m0 : 24|1@1+ (1,0) [0|1] "" Vector__XXX
 SG_ GTW_w022_EPBLversionMismatch m0 : 25|1@1+ (1,0) [0|1] "" Vector__XXX
 SG_ GTW_w023_EPBRversionMismatch m0 : 26|1@1+ (1,0) [0|1] "" Vector__XXX
 SG_ GTW_w024_ESPversionMismatch m0 : 27|1@1+ (1,0) [0|1] "" Vector__XXX
 SG_ GTW_w025_ESPCALversionMismatch m0 : 28|1@1+ (1,0) [0|1] "" Vector__XXX
 SG_ GTW_w026_GTWversionMismatch m0 : 29|1@1+ (1,0) [0|1] "" Vector__XXX
 SG_ GTW_w027_HVPversionMismatch m0 : 30|1@1+ (1,0) [0|1] "" Vector__XXX
 SG_ GTW_w028_IBSTversionMismatch m0 : 31|1@1+ (1,0) [0|1] "" Vector__XXX
 SG_ GTW_w029_IBSTCALversionMismatch m0 : 32|1@1+ (1,0) [0|1] "" Vector__XXX
 SG_ GTW_w030_OCS1PversionMismatch m0 : 33|1@1+ (1,0) [0|1] "" Vector__XXX
 SG_ GTW_w031_PARKversionMismatch m0 : 34|1@1+ (1,0) [0|1] "" Vector__XXX
 SG_ GTW_w032_PCSversionMismatch m0 : 35|1@1+ (1,0) [0|1] "" Vector__XXX
 SG_ GTW_w033_PCSCPU2versionMismatch m0 : 36|1@1+ (1,0) [0|1] "" Vector__XXX
 SG_ GTW_w034_PMRversionMismatch m0 : 37|1@1+ (1,0) [0|1] "" Vector__XXX
 SG_ GTW_w035_PMFversionMismatch m0 : 38|1@1+ (1,0) [0|1] "" Vector__XXX
 SG_ GTW_w036_PTCversionMismatch m0 : 39|1@1+ (1,0) [0|1] "" Vector__XXX
 SG_ GTW_w037_RADCversionMismatch m0 : 40|1@1+ (1,0) [0|1] "" Vector__XXX
 SG_ GTW_w038_RCMversionMismatch m0 : 41|1@1+ (1,0) [0|1] "" Vector__XXX
 SG_ GTW_w039_RCMCALversionMismatch m0 : 42|1@1+ (1,0) [0|1] "" Vector__XXX
 SG_ GTW_w040_SCCMversionMismatch m0 : 43|1@1+ (1,0) [0|1] "" Vector__XXX
 SG_ GTW_w041_VCSECversionMismatch m0 : 44|1@1+ (1,0) [0|1] "" Vector__XXX
 SG_ GTW_w042_TASversionMismatch m0 : 45|1@1+ (1,0) [0|1] "" Vector__XXX
 SG_ GTW_w043_THSversionMismatch m0 : 46|1@1+ (1,0) [0|1] "" Vector__XXX
 SG_ GTW_w045_VCFRONTversionMismatch m0 : 48|1@1+ (1,0) [0|1] "" Vector__XXX
 SG_ GTW_w046_VCLEFTversionMismatch m0 : 49|1@1+ (1,0) [0|1] "" Vector__XXX
 SG_ GTW_w047_VCRIGHTversionMismatch m0 : 50|1@1+ (1,0) [0|1] "" Vector__XXX
 SG_ GTW_w048_EPAS3SversionMismatch m0 : 51|1@1+ (1,0) [0|1] "" Vector__XXX
 SG_ GTW_w049_corruptedManifest m0 : 52|1@1+ (1,0) [0|1] "" Vector__XXX
 SG_ GTW_w050_sdCardInitFailure m0 : 53|1@1+ (1,0) [0|1] "" Vector__XXX
 SG_ GTW_w051_sdCardFileSystemFailure m0 : 54|1@1+ (1,0) [0|1] "" Vector__XXX
 SG_ GTW_w052_ifTxSpans m0 : 55|1@1+ (1,0) [0|1] "" Vector__XXX
 SG_ GTW_w053_busSleepFailure m0 : 56|1@1+ (1,0) [0|1] "" Vector__XXX
 SG_ GTW_w054_OPCRversionMismatch m0 : 57|1@1+ (1,0) [0|1] "" Vector__XXX
 SG_ GTW_w055_OPCFversionMismatch m0 : 58|1@1+ (1,0) [0|1] "" Vector__XXX
 SG_ GTW_w057_i2cFailure m0 : 60|1@1+ (1,0) [0|1] "" Vector__XXX
 SG_ GTW_w058_rtcAlarmFailure m0 : 61|1@1+ (1,0) [0|1] "" Vector__XXX
 SG_ GTW_w059_inFactoryMode m0 : 62|1@1+ (1,0) [0|1] "" Vector__XXX
 SG_ GTW_w060_unFused m0 : 63|1@1+ (1,0) [0|1] "" Vector__XXX
 SG_ GTW_w061_bmpSleepFailure m1 : 4|1@1+ (1,0) [0|1] "" Vector__XXX
 SG_ GTW_w062_bmpWatchdog m1 : 5|1@1+ (1,0) [0|1] "" Vector__XXX
 SG_ GTW_w063_VEH_canFault m1 : 6|1@1+ (1,0) [0|1] "" Vector__XXX
 SG_ GTW_w064_CH_canFault m1 : 7|1@1+ (1,0) [0|1] "" Vector__XXX
 SG_ GTW_w065_PARTY_canFault m1 : 8|1@1+ (1,0) [0|1] "" Vector__XXX
 SG_ GTW_w066_exception m1 : 9|1@1+ (1,0) [0|1] "" Vector__XXX
 SG_ GTW_w067_tcpDebug m1 : 10|1@1+ (1,0) [0|1] "" Vector__XXX
 SG_ GTW_w068_prodKeyMissing m1 : 11|1@1+ (1,0) [0|1] "" Vector__XXX
 SG_ GTW_w069_diskioErr m1 : 12|1@1+ (1,0) [0|1] "" Vector__XXX
 SG_ GTW_w070_hrlDump m1 : 13|1@1+ (1,0) [0|1] "" Vector__XXX
 SG_ GTW_w071_hrlTrigger m1 : 14|1@1+ (1,0) [0|1] "" Vector__XXX
 SG_ GTW_w072_updateFailure m1 : 15|1@1+ (1,0) [0|1] "" Vector__XXX
 SG_ GTW_w073_steeringWheelReset m1 : 16|1@1+ (1,0) [0|1] "" Vector__XXX
 SG_ GTW_w074_epas3pMIA m1 : 17|1@1+ (1,0) [0|1] "" Vector__XXX
 SG_ GTW_w075_epas3sMIA m1 : 18|1@1+ (1,0) [0|1] "" Vector__XXX
 SG_ GTW_w076_ethInterfaceReset m1 : 19|1@1+ (1,0) [0|1] "" Vector__XXX
 SG_ GTW_w077_bmpPmicError m1 : 20|1@1+ (1,0) [0|1] "" Vector__XXX
 SG_ GTW_w078_VEHbusOverloaded m1 : 21|1@1+ (1,0) [0|1] "" Vector__XXX
 SG_ GTW_w079_PARTYbusOverloaded m1 : 22|1@1+ (1,0) [0|1] "" Vector__XXX
 SG_ GTW_w080_CHbusOverloaded m1 : 23|1@1+ (1,0) [0|1] "" Vector__XXX
 SG_ GTW_w081_udsMessageRejected m1 : 24|1@1+ (1,0) [0|1] "" Vector__XXX
 SG_ GTW_w082_sdCardBSCorrupted m1 : 25|1@1+ (1,0) [0|1] "" Vector__XXX
 SG_ GTW_w083_udsMsgDroppedByTcpStack m1 : 26|1@1+ (1,0) [0|1] "" Vector__XXX
 SG_ GTW_w084_canFrameDropped m1 : 27|1@1+ (1,0) [0|1] "" Vector__XXX
 SG_ GTW_w086_ocu m1 : 29|1@1+ (1,0) [0|1] "" Vector__XXX
 SG_ GTW_w087_ocuInProgress m1 : 30|1@1+ (1,0) [0|1] "" Vector__XXX
 SG_ GTW_w088_sdCardInvReqParallel m1 : 31|1@1+ (1,0) [0|1] "" Vector__XXX
 SG_ GTW_w089_sdCardWatchdog m1 : 32|1@1+ (1,0) [0|1] "" Vector__XXX
 SG_ GTW_w090_ocuFailed m1 : 33|1@1+ (1,0) [0|1] "" Vector__XXX
 SG_ GTW_w091_lowStack m1 : 34|1@1+ (1,0) [0|1] "" Vector__XXX
 SG_ GTW_w092_sdCardInvReqZero m1 : 35|1@1+ (1,0) [0|1] "" Vector__XXX
 SG_ GTW_w093_sdCardInvReqOverflowBas m1 : 36|1@1+ (1,0) [0|1] "" Vector__XXX
 SG_ GTW_w094_sdCardInvReqOverflowCou m1 : 37|1@1+ (1,0) [0|1] "" Vector__XXX
 SG_ GTW_w095_sdCardFull m1 : 38|1@1+ (1,0) [0|1] "" Vector__XXX
 SG_ GTW_w096_sdCardFatCorrupted m1 : 39|1@1+ (1,0) [0|1] "" Vector__XXX
 SG_ GTW_w097_HCMLversionMismatch m1 : 40|1@1+ (1,0) [0|1] "" Vector__XXX
 SG_ GTW_w098_HCMRversionMismatch m1 : 41|1@1+ (1,0) [0|1] "" Vector__XXX
 SG_ GTW_w099_SWCversionMismatch m1 : 42|1@1+ (1,0) [0|1] "" Vector__XXX
 SG_ GTW_w100_CBCversionMismatch m1 : 43|1@1+ (1,0) [0|1] "" Vector__XXX
 SG_ GTW_w101_switchWatchdog m1 : 44|1@1+ (1,0) [0|1] "" Vector__XXX
 SG_ GTW_w103_sdCardFormatted m1 : 46|1@1+ (1,0) [0|1] "" Vector__XXX
 SG_ GTW_w104_sdCardDriverArgCorrupte m1 : 47|1@1+ (1,0) [0|1] "" Vector__XXX
 SG_ GTW_w105_eBuckConfigured m1 : 48|1@1+ (1,0) [0|1] "" Vector__XXX
 SG_ GTW_w106_BLEEPLEFTversionMismatc m1 : 49|1@1+ (1,0) [0|1] "" Vector__XXX
 SG_ GTW_w107_BLEEPRIGHTversionMismat m1 : 50|1@1+ (1,0) [0|1] "" Vector__XXX
 SG_ GTW_w108_BLEEPREARversionMismatc m1 : 51|1@1+ (1,0) [0|1] "" Vector__XXX
 SG_ GTW_w109_failedToStartUpdater m1 : 52|1@1+ (1,0) [0|1] "" Vector__XXX
 SG_ GTW_w110_readMdioFailed m1 : 53|1@1+ (1,0) [0|1] "" Vector__XXX
 SG_ GTW_w111_writeMdioFailed m1 : 54|1@1+ (1,0) [0|1] "" Vector__XXX
 SG_ GTW_w112_z4bDisabled m1 : 55|1@1+ (1,0) [0|1] "" Vector__XXX
 SG_ GTW_w113_unrecognizedCanMessage m1 : 56|1@1+ (1,0) [0|1] "" Vector__XXX
 SG_ GTW_w114_updtRetried m1 : 57|1@1+ (1,0) [0|1] "" Vector__XXX
 SG_ GTW_w115_hrlEventFileAvail m1 : 58|1@1+ (1,0) [0|1] "" Vector__XXX
 SG_ GTW_w116_switchInitFailed m1 : 59|1@1+ (1,0) [0|1] "" Vector__XXX
 SG_ GTW_w117_unexpectedDestructiveRe m1 : 60|1@1+ (1,0) [0|1] "" Vector__XXX
 SG_ GTW_w118_unexpectedFunctionalRes m1 : 61|1@1+ (1,0) [0|1] "" Vector__XXX
 SG_ GTW_w120_switchUnlocked m1 : 63|1@1+ (1,0) [0|1] "" Vector__XXX
 SG_ GTW_w122_BDY_canFault m2 : 5|1@1+ (1,0) [0|1] "" Vector__XXX
 SG_ GTW_w123_BDYbusOverloaded m2 : 6|1@1+ (1,0) [0|1] "" Vector__XXX
 SG_ GTW_w125_switchReplayUnlocked m2 : 8|1@1+ (1,0) [0|1] "" Vector__XXX
 SG_ GTW_w127_noFilePointersAvailable m2 : 10|1@1+ (1,0) [0|1] "" Vector__XXX
 SG_ GTW_w129_ICRversionMismatch m2 : 12|1@1+ (1,0) [0|1] "" Vector__XXX
 SG_ GTW_w133_adspFaultDetected m2 : 16|1@1+ (1,0) [0|1] "" Vector__XXX
 SG_ GTW_w134_disableFeatureFailed m2 : 17|1@1+ (1,0) [0|1] "" Vector__XXX
 SG_ GTW_w135_canLogQueueFull m2 : 18|1@1+ (1,0) [0|1] "" Vector__XXX
 SG_ GTW_w136_hrlGameModeFileAvail m2 : 19|1@1+ (1,0) [0|1] "" Vector__XXX
 SG_ GTW_w137_lowHeap m2 : 20|1@1+ (1,0) [0|1] "" Vector__XXX
 SG_ GTW_w138_sdCardEndOfLife m2 : 21|1@1+ (1,0) [0|1] "" Vector__XXX
 SG_ GTW_w139_CMPDversionMismatch m2 : 22|1@1+ (1,0) [0|1] "" Vector__XXX
 SG_ GTW_w140_cancoreHeartbeat m2 : 23|1@1+ (1,0) [0|1] "" Vector__XXX
 SG_ GTW_w141_teleCANETHis m2 : 24|1@1+ (1,0) [0|1] "" Vector__XXX
 SG_ GTW_w143_possibleCanWakeIssue m2 : 26|1@1+ (1,0) [0|1] "" Vector__XXX
 SG_ GTW_w144_hrlStateMachine m2 : 27|1@1+ (1,0) [0|1] "" Vector__XXX
 SG_ GTW_w145_carConfigsNotWritten m2 : 28|1@1+ (1,0) [0|1] "" Vector__XXX
 SG_ GTW_w146_performancePackageMisma m2 : 29|1@1+ (1,0) [0|1] "" Vector__XXX
 SG_ GTW_w147_updateAbortFor12v m2 : 30|1@1+ (1,0) [0|1] "" Vector__XXX
 SG_ GTW_w149_rtcTimeSetInPast m2 : 32|1@1+ (1,0) [0|1] "" Vector__XXX
 SG_ GTW_w150_HCM3LversionMismatch m2 : 33|1@1+ (1,0) [0|1] "" Vector__XXX
 SG_ GTW_w151_HCM3RversionMismatch m2 : 34|1@1+ (1,0) [0|1] "" Vector__XXX
 SG_ GTW_w153_externalRtcAlarmFailure m2 : 36|1@1+ (1,0) [0|1] "" Vector__XXX
 SG_ GTW_w155_PMversionMismatch m2 : 38|1@1+ (1,0) [0|1] "" Vector__XXX
 SG_ GTW_w165_USMversionMismatch m2 : 48|1@1+ (1,0) [0|1] "" Vector__XXX
 SG_ GTW_w166_nErrCanFaultVeh m2 : 49|1@1+ (1,0) [0|1] "" Vector__XXX
 SG_ GTW_w167_nErrCanFaultCh m2 : 50|1@1+ (1,0) [0|1] "" Vector__XXX
 SG_ GTW_w168_nErrCanFaultParty m2 : 51|1@1+ (1,0) [0|1] "" Vector__XXX
 SG_ GTW_w169_TPMSsoftWarnFrontLeft m2 : 52|1@1+ (1,0) [0|1] "" Vector__XXX
 SG_ GTW_w170_TPMSsoftWarnFrontRight m2 : 53|1@1+ (1,0) [0|1] "" Vector__XXX
 SG_ GTW_w171_TPMSsoftWarnRearLeft m2 : 54|1@1+ (1,0) [0|1] "" Vector__XXX
 SG_ GTW_w172_TPMSsoftWarnRearRight m2 : 55|1@1+ (1,0) [0|1] "" Vector__XXX
 SG_ GTW_w173_TPMShardWarnFrontLeft m2 : 56|1@1+ (1,0) [0|1] "" Vector__XXX
 SG_ GTW_w174_TPMShardWarnFrontRight m2 : 57|1@1+ (1,0) [0|1] "" Vector__XXX
 SG_ GTW_w175_TPMShardWarnRearLeft m2 : 58|1@1+ (1,0) [0|1] "" Vector__XXX
 SG_ GTW_w176_TPMShardWarnRearRight m2 : 59|1@1+ (1,0) [0|1] "" Vector__XXX
 SG_ GTW_w186_swrPrecaution m3 : 9|1@1+ (1,0) [0|1] "" Vector__XXX
 SG_ GTW_w218_switchOTPIncorrect m3 : 41|1@1+ (1,0) [0|1] "" Vector__XXX
 SG_ GTW_w219_CMPSversionMismatch m3 : 42|1@1+ (1,0) [0|1] "" Vector__XXX
 SG_ GTW_w223_LVBMSversionMismatch m3 : 46|1@1+ (1,0) [0|1] "" Vector__XXX
 SG_ GTW_w224_sdCardUpgradeNeeded m3 : 47|1@1+ (1,0) [0|1] "" Vector__XXX
 SG_ GTW_w225_resetOnSleepWake m3 : 48|1@1+ (1,0) [0|1] "" Vector__XXX
 SG_ GTW_w226_DISPversionMismatch m3 : 49|1@1+ (1,0) [0|1] "" Vector__XXX
 SG_ GTW_w227_DISPTOUCHversionMismatc m3 : 50|1@1+ (1,0) [0|1] "" Vector__XXX
 SG_ GTW_w228_DISPOSDversionMismatch m3 : 51|1@1+ (1,0) [0|1] "" Vector__XXX
 SG_ GTW_w229_displaySoftsetConnectio m3 : 52|1@1+ (1,0) [0|1] "" Vector__XXX
 SG_ GTW_w230_touchInterruptStorm m3 : 53|1@1+ (1,0) [0|1] "" Vector__XXX
 SG_ GTW_w244_SDCRversionMismatch m4 : 7|1@1+ (1,0) [0|1] "" Vector__XXX
 SG_ GTW_w245_apsNotDisabled m4 : 8|1@1+ (1,0) [0|1] "" Vector__XXX
 SG_ GTW_w246_touchcoreHeartbeat m4 : 9|1@1+ (1,0) [0|1] "" Vector__XXX
 SG_ GTW_w255_rtc32KHzWatchdog m4 : 18|1@1+ (1,0) [0|1] "" Vector__XXX
 SG_ GTW_w260_unknownPN m4 : 23|1@1+ (1,0) [0|1] "" Vector__XXX
 SG_ GTW_w261_adspWatchdog m4 : 24|1@1+ (1,0) [0|1] "" Vector__XXX
 SG_ GTW_w262_canLogBlockDropped m4 : 25|1@1+ (1,0) [0|1] "" Vector__XXX
 SG_ GTW_w263_hrlUdpFileAvail m4 : 26|1@1+ (1,0) [0|1] "" Vector__XXX
 SG_ GTW_w264_hrlPseudoFileAvail m4 : 27|1@1+ (1,0) [0|1] "" Vector__XXX
 SG_ GTW_w265_optionFlagsError m4 : 28|1@1+ (1,0) [0|1] "" Vector__XXX
 SG_ GTW_w266_dpp1MIA m4 : 29|1@1+ (1,0) [0|1] "" Vector__XXX
 SG_ GTW_w267_dpp2MIA m4 : 30|1@1+ (1,0) [0|1] "" Vector__XXX
 SG_ GTW_w268_stoMIA m4 : 31|1@1+ (1,0) [0|1] "" Vector__XXX
 SG_ GTW_w273_BLEEPREARLEFTversionMis m4 : 36|1@1+ (1,0) [0|1] "" Vector__XXX
 SG_ GTW_w274_BLEEPREARRIGHTversionMi m4 : 37|1@1+ (1,0) [0|1] "" Vector__XXX
 SG_ GTW_w275_VDDCORE_DrMOS_Fault m4 : 38|1@1+ (1,0) [0|1] "" Vector__XXX
 SG_ GTW_w276_VDDSOC_DrMOS_Fault m4 : 39|1@1+ (1,0) [0|1] "" Vector__XXX
 SG_ GTW_w277_NonRevCDrMOSMitigationF m4 : 40|1@1+ (1,0) [0|1] "" Vector__XXX
 SG_ GTW_w278_ethSwitchCongested m4 : 41|1@1+ (1,0) [0|1] "" Vector__XXX
 SG_ GTW_w279_adspRepeatedWatchdog m4 : 42|1@1+ (1,0) [0|1] "" Vector__XXX
 SG_ GTW_w280_hrlFrameDropped m4 : 43|1@1+ (1,0) [0|1] "" Vector__XXX
 SG_ GTW_w281_likelyMissedPoke m4 : 44|1@1+ (1,0) [0|1] "" Vector__XXX
 SG_ GTW_w282_tcuPhyConfigurationFail m4 : 45|1@1+ (1,0) [0|1] "" Vector__XXX
 SG_ GTW_w309_VCUSBversionMismatch m5 : 12|1@1+ (1,0) [0|1] "" Vector__XXX
 SG_ GTW_w311_canLogQueueFullBeforeFs m5 : 14|1@1+ (1,0) [0|1] "" Vector__XXX
 SG_ GTW_w312_hrlFileIncomplete m5 : 15|1@1+ (1,0) [0|1] "" Vector__XXX
 SG_ GTW_w313_OSDActive m5 : 16|1@1+ (1,0) [0|1] "" Vector__XXX
 SG_ GTW_w314_canLogBlockWriteErr m5 : 17|1@1+ (1,0) [0|1] "" Vector__XXX
 SG_ GTW_w316_sdCardChkdskRepair m5 : 19|1@1+ (1,0) [0|1] "" Vector__XXX
 SG_ GTW_w317_sdCardChkdskRepairFaile m5 : 20|1@1+ (1,0) [0|1] "" Vector__XXX
 SG_ GTW_w322_gestureUnrecognizedFrom m5 : 25|1@1+ (1,0) [0|1] "" Vector__XXX
 SG_ GTW_w323_gestureStartOutOfStrip m5 : 26|1@1+ (1,0) [0|1] "" Vector__XXX
 SG_ GTW_w328_smartShiftDisabled m5 : 31|1@1+ (1,0) [0|1] "" Vector__XXX
 SG_ GTW_w329_FOHMversionMismatch m5 : 32|1@1+ (1,0) [0|1] "" Vector__XXX
 SG_ GTW_w330_SWSLversionMismatch m5 : 33|1@1+ (1,0) [0|1] "" Vector__XXX
 SG_ GTW_w331_SWSRversionMismatch m5 : 34|1@1+ (1,0) [0|1] "" Vector__XXX
 SG_ GTW_w332_unknownDisplayPN m5 : 35|1@1+ (1,0) [0|1] "" Vector__XXX
 SG_ GTW_w334_hrlFolderSpaceLow m5 : 37|1@1+ (1,0) [0|1] "" Vector__XXX
 SG_ GTW_w336_possibleCanTxIssue m5 : 39|1@1+ (1,0) [0|1] "" Vector__XXX
 SG_ GTW_w342_VCBLDCPPversionMismatch m5 : 45|1@1+ (1,0) [0|1] "" Vector__XXX
 SG_ GTW_w348_VCBLDCFversionMismatch m5 : 51|1@1+ (1,0) [0|1] "" Vector__XXX
 SG_ GTW_w349_VCBLDCPBversionMismatch m5 : 52|1@1+ (1,0) [0|1] "" Vector__XXX
 SG_ GTW_w350_mOSDCrcCheck m5 : 53|1@1+ (1,0) [0|1] "" Vector__XXX
 SG_ GTW_w351_sOSDCrcCheck m5 : 54|1@1+ (1,0) [0|1] "" Vector__XXX
 SG_ GTW_w352_mASILStatusCheck m5 : 55|1@1+ (1,0) [0|1] "" Vector__XXX
 SG_ GTW_w353_sASILStatusCheck m5 : 56|1@1+ (1,0) [0|1] "" Vector__XXX
 SG_ GTW_w354_EPASTPversionMismatch m5 : 57|1@1+ (1,0) [0|1] "" Vector__XXX
 SG_ GTW_w355_EPASTSversionMismatch m5 : 58|1@1+ (1,0) [0|1] "" Vector__XXX
 SG_ GTW_w356_touchGPIOStatusCheck m5 : 59|1@1+ (1,0) [0|1] "" Vector__XXX
 SG_ GTW_w358_RGBIPFLversionMismatch m5 : 61|1@1+ (1,0) [0|1] "" Vector__XXX
 SG_ GTW_w359_RGBIPFRversionMismatch m5 : 62|1@1+ (1,0) [0|1] "" Vector__XXX
 SG_ GTW_w360_RGBDOORFLversionMismatc m5 : 63|1@1+ (1,0) [0|1] "" Vector__XXX
 SG_ GTW_w361_RGBDOORRLversionMismatc m6 : 4|1@1+ (1,0) [0|1] "" Vector__XXX
 SG_ GTW_w362_RGBDOORFRversionMismatc m6 : 5|1@1+ (1,0) [0|1] "" Vector__XXX
 SG_ GTW_w363_RGBDOORRRversionMismatc m6 : 6|1@1+ (1,0) [0|1] "" Vector__XXX
 SG_ GTW_w364_BLEEPCRADLEversionMisma m6 : 7|1@1+ (1,0) [0|1] "" Vector__XXX
 SG_ GTW_w366_uiGearRequestMismatch m6 : 9|1@1+ (1,0) [0|1] "" Vector__XXX
 SG_ GTW_w376_blFailedToExecBootImg m6 : 19|1@1+ (1,0) [0|1] "" Vector__XXX
 SG_ GTW_w380_DPBversionMismatch m6 : 23|1@1+ (1,0) [0|1] "" Vector__XXX
 SG_ GTW_w381_DPBCALversionMismatch m6 : 24|1@1+ (1,0) [0|1] "" Vector__XXX
 SG_ GTW_w382_IDBversionMismatch m6 : 25|1@1+ (1,0) [0|1] "" Vector__XXX
 SG_ GTW_w383_IDB1versionMismatch m6 : 26|1@1+ (1,0) [0|1] "" Vector__XXX
 SG_ GTW_w384_IDBCALversionMismatch m6 : 27|1@1+ (1,0) [0|1] "" Vector__XXX
 SG_ GTW_w385_RCUversionMismatch m6 : 28|1@1+ (1,0) [0|1] "" Vector__XXX
 SG_ GTW_w386_RCUCALversionMismatch m6 : 29|1@1+ (1,0) [0|1] "" Vector__XXX
 SG_ GTW_w387_externalRtcReadFailure m6 : 30|1@1+ (1,0) [0|1] "" Vector__XXX
 SG_ GTW_w388_adspWatchdogSkipped m6 : 31|1@1+ (1,0) [0|1] "" Vector__XXX
 SG_ GTW_w389_rcmEventDetected m6 : 32|1@1+ (1,0) [0|1] "" Vector__XXX
 SG_ GTW_w391_adspMacAddrCheckFailed m6 : 34|1@1+ (1,0) [0|1] "" Vector__XXX
 SG_ GTW_w393_osdSramCrcMismatch m6 : 36|1@1+ (1,0) [0|1] "" Vector__XXX
 SG_ GTW_w395_lwipIcmpError m6 : 38|1@1+ (1,0) [0|1] "" Vector__XXX
 SG_ GTW_w396_alreadyInReverse m6 : 39|1@1+ (1,0) [0|1] "" Vector__XXX
 SG_ GTW_w397_alreadyInDrive m6 : 40|1@1+ (1,0) [0|1] "" Vector__XXX
 SG_ GTW_w398_awakeForExtendedTime m6 : 41|1@1+ (1,0) [0|1] "" Vector__XXX
 SG_ GTW_w399_ethIfRxTcpipQueueDrop m6 : 42|1@1+ (1,0) [0|1] "" Vector__XXX
 SG_ GTW_w400_ethlSwitchOTPIncorrect m6 : 43|1@1+ (1,0) [0|1] "" Vector__XXX
 SG_ GTW_w409_unexpectedResetCause m6 : 52|1@1+ (1,0) [0|1] "" Vector__XXX
 SG_ GTW_w410_unexpectedResetCause2 m6 : 53|1@1+ (1,0) [0|1] "" Vector__XXX
 SG_ GTW_w414_socHeldInReset m6 : 57|1@1+ (1,0) [0|1] "" Vector__XXX

BO_ 838 GTW_autopilotOverride: 8 GTW
 SG_ GTW_autopilotOverrideState : 0|2@1+ (1,0) [0|3] "" Vector__XXX
 SG_ GTW_autopilotConfig : 2|3@1+ (1,0) [0|7] "" Vector__XXX
 SG_ GTW_autopilotOverrideConfig : 5|3@1+ (1,0) [0|7] "" Vector__XXX
 SG_ GTW_autopilotOverrideExpireTime : 32|32@1+ (1,0) [0|4294967295] "" Vector__XXX

BO_TX_BU_ 1000 : EPBR;
BO_TX_BU_ 742 : EPBR;
BO_TX_BU_ 744 : EPBR;
BO_TX_BU_ 1575 : EPBR;
BO_TX_BU_ 981 : ESP;
BO_TX_BU_ 1621 : ESP;
BO_TX_BU_ 373 : ESP;
BO_TX_BU_ 888 : GTW;
BO_TX_BU_ 282 : GTW;
BO_TX_BU_ 1384 : GTW;
BO_TX_BU_ 62 : GTW;
BO_TX_BU_ 838 : GTW;
CM_ BO_ 1000 "Right electric parking brake message: alert matrix";
CM_ SG_ 1000 EPBR_matrixIndex "Right electric parking brake: matrix index";
CM_ SG_ 1000 EPBR_a001_WatchdogReset "Right electric parking brake: a001 watchdog reset";
CM_ SG_ 1000 EPBR_a002_PowerLossReset "Right electric parking brake: a002 power loss reset";
CM_ SG_ 1000 EPBR_a003_SWAssertion "Right electric parking brake: a003 SW assertion";
CM_ SG_ 1000 EPBR_a005_CANTXError "Right electric parking brake: a005 CANTX error";
CM_ SG_ 1000 EPBR_a006_CANTX_cyclicError "Right electric parking brake: a006 CANTX cyclic error";
CM_ SG_ 1000 EPBR_a012_CPUReset "Right electric parking brake: a012 CPU reset";
CM_ SG_ 1000 EPBR_a013_AlertManagerFault "Right electric parking brake: a013 alert manager fault";
CM_ SG_ 1000 EPBR_a015_NVMMError "Right electric parking brake: a015 NVMM error";
CM_ SG_ 1000 EPBR_a016_NVMMRecordError "Right electric parking brake: a016 NVMM record error";
CM_ SG_ 1000 EPBR_a021_TaskSchedulerError "Right electric parking brake: a021 task scheduler error";
CM_ SG_ 1000 EPBR_a022_TaskInitError "Right electric parking brake: a022 task init error";
CM_ SG_ 1000 EPBR_a029_CoreDump "Right electric parking brake: a029 core dump";
CM_ SG_ 1000 EPBR_a030_ECULogUploadRequest "Right electric parking brake: a030 ECU log upload request";
CM_ SG_ 1000 EPBR_a031_UDSActive "Right electric parking brake: a031 UDS active";
CM_ SG_ 1000 EPBR_a041_HighCPULoad "Right electric parking brake: a041 high CPU load";
CM_ SG_ 1000 EPBR_a042_HighStackUsage "Right electric parking brake: a042 high stack usage";
CM_ SG_ 1000 EPBR_a043_Task1msError "Right electric parking brake: a043 task1ms error";
CM_ SG_ 1000 EPBR_a044_Task10msError "Right electric parking brake: a044 task10ms error";
CM_ SG_ 1000 EPBR_a045_Task100msError "Right electric parking brake: a045 task100ms error";
CM_ SG_ 1000 EPBR_a046_Task1000msError "Right electric parking brake: a046 task1000ms error";
CM_ SG_ 1000 EPBR_a057_HVP_MIA "Right electric parking brake: a057 HVP MIA";
CM_ SG_ 1000 EPBR_a058_inputRHighSyncDebug "Right electric parking brake: a058 input r high sync debug";
CM_ SG_ 1000 EPBR_a059_inputResistanceHigh "Right electric parking brake: a059 input resistance high";
CM_ SG_ 1000 EPBR_a060_engineeringBuild "Right electric parking brake: a060 engineering build";
CM_ SG_ 1000 EPBR_a061_XCPConnected "Right electric parking brake: a061 XCP connected";
CM_ SG_ 1000 EPBR_a062_XCPWasConnected "Right electric parking brake: a062 XCP was connected";
CM_ SG_ 1000 EPBR_a063_SwitchFault "Right electric parking brake: a063 switch fault";
CM_ SG_ 1000 EPBR_a064_busSleepReqTimeout "Right electric parking brake: a064 bus sleep req timeout";
CM_ SG_ 1000 EPBR_a081_APP_MIA "Right electric parking brake: a081 APP MIA";
CM_ SG_ 1000 EPBR_a082_VCRIGHT_IPC_MIA "Right electric parking brake: a082 VCRIGHT IPC MIA";
CM_ SG_ 1000 EPBR_a083_VCLEFT_IPC_MIA "Right electric parking brake: a083 VCLEFT IPC MIA";
CM_ SG_ 1000 EPBR_a084_TPMS_MIA "Right electric parking brake: a084 TPMS MIA";
CM_ SG_ 1000 EPBR_a085_CCCM_MIA "Right electric parking brake: a085 CCCM MIA";
CM_ SG_ 1000 EPBR_a086_VCBATT_MIA "Right electric parking brake: a086 VCBATT MIA";
CM_ SG_ 1000 EPBR_a087_DIREL_MIA "Right electric parking brake: a087 DIREL MIA";
CM_ SG_ 1000 EPBR_a088_DIRER_MIA "Right electric parking brake: a088 DIRER MIA";
CM_ SG_ 1000 EPBR_a089_IBST_MIA "Right electric parking brake: a089 IBST MIA";
CM_ SG_ 1000 EPBR_a090_APS_MIA "Right electric parking brake: a090 APS MIA";
CM_ SG_ 1000 EPBR_a091_CMPD_MIA "Right electric parking brake: a091 CMPD MIA";
CM_ SG_ 1000 EPBR_a092_VCSEATD_MIA "Right electric parking brake: a092 VCSEATD MIA";
CM_ SG_ 1000 EPBR_a093_VCSEATP_MIA "Right electric parking brake: a093 VCSEATP MIA";
CM_ SG_ 1000 EPBR_a094_EPAS3P_MIA "Right electric parking brake: a094 EPAS3 p MIA";
CM_ SG_ 1000 EPBR_a095_CHG_MIA "Right electric parking brake: a095 CHG MIA";
CM_ SG_ 1000 EPBR_a096_OCS1P_MIA "Right electric parking brake: a096 OCS1 p MIA";
CM_ SG_ 1000 EPBR_a097_CMP_MIA "Right electric parking brake: a097 CMP MIA";
CM_ SG_ 1000 EPBR_a098_DIR_MIA "Right electric parking brake: a098 DIR MIA";
CM_ SG_ 1000 EPBR_a099_PARK_MIA "Right electric parking brake: a099 PARK MIA";
CM_ SG_ 1000 EPBR_a100_CANbus_MIA "Right electric parking brake: a100 CA nbus MIA";
CM_ SG_ 1000 EPBR_a101_PM_MIA "Right electric parking brake: a101 PM MIA";
CM_ SG_ 1000 EPBR_a102_PTC_MIA "Right electric parking brake: a102 PTC MIA";
CM_ SG_ 1000 EPBR_a103_CP_MIA "Right electric parking brake: a103 CP MIA";
CM_ SG_ 1000 EPBR_a104_DAS_MIA "Right electric parking brake: a104 DAS MIA";
CM_ SG_ 1000 EPBR_a105_TAS_MIA "Right electric parking brake: a105 TAS MIA";
CM_ SG_ 1000 EPBR_a106_PCS_MIA "Right electric parking brake: a106 PCS MIA";
CM_ SG_ 1000 EPBR_a107_BMS_MIA "Right electric parking brake: a107 BMS MIA";
CM_ SG_ 1000 EPBR_a108_DIF_MIA "Right electric parking brake: a108 DIF MIA";
CM_ SG_ 1000 EPBR_a109_RCM_MIA "Right electric parking brake: a109 RCM MIA";
CM_ SG_ 1000 EPBR_a110_GTW_MIA "Right electric parking brake: a110 GTW MIA";
CM_ SG_ 1000 EPBR_a111_EPBR_MIA "Right electric parking brake: a111 EPBR MIA";
CM_ SG_ 1000 EPBR_a112_EPBL_MIA "Right electric parking brake: a112 EPBL MIA";
CM_ SG_ 1000 EPBR_a113_UI_MIA "Right electric parking brake: a113 UI MIA";
CM_ SG_ 1000 EPBR_a114_ESP_MIA "Right electric parking brake: a114 ESP MIA";
CM_ SG_ 1000 EPBR_a115_VCSEC_MIA "Right electric parking brake: a115 VCSEC MIA";
CM_ SG_ 1000 EPBR_a116_VCRIGHT_MIA "Right electric parking brake: a116 VCRIGHT MIA";
CM_ SG_ 1000 EPBR_a117_VCLEFT_MIA "Right electric parking brake: a117 VCLEFT MIA";
CM_ SG_ 1000 EPBR_a118_VCFRONT_MIA "Right electric parking brake: a118 VCFRONT MIA";
CM_ SG_ 1000 EPBR_a119_SCCM_MIA "Right electric parking brake: a119 SCCM MIA";
CM_ SG_ 1000 EPBR_a120_DI_DRIVE_MIA "Right electric parking brake: a120 DI DRIVE MIA";
CM_ SG_ 1000 EPBR_a121_nDriveFault "Right electric parking brake: a121 n drive fault";
CM_ SG_ 1000 EPBR_a122_Oc "Right electric parking brake: a122 oc";
CM_ SG_ 1000 EPBR_a123_Uc "Right electric parking brake: a123 uc";
CM_ SG_ 1000 EPBR_a124_calOutOfBounds "Right electric parking brake: a124 cal out of bounds";
CM_ SG_ 1000 EPBR_a125_IdleVMismatch "Right electric parking brake: a125 idle v mismatch";
CM_ SG_ 1000 EPBR_a126_MotorNVoltLow "Right electric parking brake: a126 motor n volt low";
CM_ SG_ 1000 EPBR_a127_MotorNVoltHigh "Right electric parking brake: a127 motor n volt high";
CM_ SG_ 1000 EPBR_a128_MotorPVoltHigh "Right electric parking brake: a128 motor p volt high";
CM_ SG_ 1000 EPBR_a129_ICR_MIA "Right electric parking brake: a129 ICR MIA";
CM_ SG_ 1000 EPBR_a130_BB_MIA "Right electric parking brake: a130 BB MIA";
CM_ SG_ 1000 EPBR_a131_RCU_MIA "Right electric parking brake: a131 RCU MIA";
CM_ SG_ 1000 EPBR_a132_VCBATT1_MIA "Right electric parking brake: a132 VCBATT1 MIA";
CM_ SG_ 1000 EPBR_a134_NvOv "Right electric parking brake: a134 nv ov";
CM_ SG_ 1000 EPBR_a135_NvUv "Right electric parking brake: a135 nv uv";
CM_ SG_ 1000 EPBR_a136_PvOv "Right electric parking brake: a136 pv ov";
CM_ SG_ 1000 EPBR_a137_PvUv "Right electric parking brake: a137 pv uv";
CM_ SG_ 1000 EPBR_a138_NvmDualFailure "Right electric parking brake: a138 nvm dual failure";
CM_ SG_ 1000 EPBR_a139_NvmRedundancyLoss "Right electric parking brake: a139 nvm redundancy loss";
CM_ SG_ 1000 EPBR_a140_NvmSlowWrite "Right electric parking brake: a140 nvm slow write";
CM_ SG_ 1000 EPBR_a141_invalidState "Right electric parking brake: a141 invalid state";
CM_ SG_ 1000 EPBR_a170_12vOv "Right electric parking brake: a170 12v ov";
CM_ SG_ 1000 EPBR_a171_12vUv "Right electric parking brake: a171 12v uv";
CM_ SG_ 1000 EPBR_a172_SPI_MIA "Right electric parking brake: a172 SPI MIA";
CM_ SG_ 1000 EPBR_a173_hiCurrentMissing "Right electric parking brake: a173 hi current missing";
CM_ SG_ 1000 EPBR_a174_csmReleaseFailed "Right electric parking brake: a174 csm release failed";
CM_ SG_ 1000 EPBR_a175_csmReleaseRetry "Right electric parking brake: a175 csm release retry";
CM_ SG_ 1000 EPBR_a176_csmApplyFailed "Right electric parking brake: a176 csm apply failed";
CM_ SG_ 1000 EPBR_a177_csmApplyRetry "Right electric parking brake: a177 csm apply retry";
CM_ SG_ 1000 EPBR_a178_caliperStateUnknown "Right electric parking brake: a178 caliper state unknown";
CM_ SG_ 1000 EPBR_a179_epbProblem "Right electric parking brake: a179 epb problem";
CM_ SG_ 1000 EPBR_a180_dynamicActive "Right electric parking brake: a180 dynamic active";
CM_ SG_ 1000 EPBR_a181_TooSteepGradeToPark "Right electric parking brake: a181 too steep grade to park";
CM_ SG_ 1000 EPBR_a182_OneEPBAppliedUnsecEnv "Right electric parking brake: a182 one EPB applied unsec env";
CM_ SG_ 1000 EPBR_a183_cdpNotAvailable "Right electric parking brake: a183 cdp not available";
CM_ SG_ 1000 EPBR_a184_dynamicParkAbort "Right electric parking brake: a184 dynamic park abort";
CM_ SG_ 1000 EPBR_a185_summonAborted "Right electric parking brake: a185 summon aborted";
CM_ SG_ 1000 EPBR_a186_externalParkAbort "Right electric parking brake: a186 external park abort";
CM_ SG_ 1000 EPBR_a187_cdpDynamic "Right electric parking brake: a187 cdp dynamic";
CM_ SG_ 1000 EPBR_a188_epbDynamic "Right electric parking brake: a188 epb dynamic";
CM_ SG_ 1000 EPBR_a189_epbDynamicParkCanceled "Right electric parking brake: a189 epb dynamic park canceled";
CM_ SG_ 1000 EPBR_a190_csmApplyDegraded "Right electric parking brake: a190 csm apply degraded";
CM_ SG_ 1000 EPBR_a191_csmReleaseDegraded "Right electric parking brake: a191 csm release degraded";
CM_ SG_ 1000 EPBR_a195_parkForDriverIsLeaving "Right electric parking brake: a195 park for driver is leaving";
CM_ SG_ 1000 EPBR_a196_freeRollModeActive "Right electric parking brake: a196 free roll mode active";
CM_ SG_ 1000 EPBR_a197_freeRollModeAtSpeed "Right electric parking brake: a197 free roll mode at speed";
CM_ SG_ 1000 EPBR_a198_holdClampComplete "Right electric parking brake: a198 hold clamp complete";
CM_ SG_ 1000 EPBR_a200_PmUnparkNotAllowed "Right electric parking brake: a200 pm unpark not allowed";
CM_ SG_ 1000 EPBR_a202_remoteEpbConfigIncompa "Right electric parking brake: a202 remote epb config incompatible";
CM_ SG_ 1000 EPBR_a203_hwBrakeTypeMismatch "Right electric parking brake: a203 hw brake type mismatch";
CM_ SG_ 1000 EPBR_a210_parkForDriverIsLeaving "Right electric parking brake: a210 park for driver is leaving debug";
CM_ SG_ 1000 EPBR_a216_SPI_MIA_debugData1 "Right electric parking brake: a216 SPI MIA debug data1";
CM_ SG_ 1000 EPBR_a217_SPI_MIA_debugData2 "Right electric parking brake: a217 SPI MIA debug data2";
CM_ SG_ 1000 EPBR_a225_epbActiveDecel "Right electric parking brake: a225 epb active decel";
CM_ SG_ 1000 EPBR_a241_diOutputLocked "Right electric parking brake: a241 di output locked";
CM_ SG_ 1000 EPBR_a242_hvOutputLocked "Right electric parking brake: a242 hv output locked";
CM_ SG_ 1000 EPBR_a243_bdwUnavailable "Right electric parking brake: a243 bdw unavailable";
CM_ SG_ 1000 EPBR_a244_WinchModeActive "Right electric parking brake: a244 winch mode active";
CM_ SG_ 1000 EPBR_a245_serviceModeActive "Signal reported by Right electric parking brake";
CM_ SG_ 1000 EPBR_a246_idleFaultApply "Right electric parking brake: a246 idle fault apply";
CM_ SG_ 1000 EPBR_a247_csmDynamicApplyRetry "Right electric parking brake: a247 csm dynamic apply retry";
CM_ SG_ 1000 EPBR_a248_csmDynamicApplyFailed "Right electric parking brake: a248 csm dynamic apply failed";
CM_ SG_ 1000 EPBR_a249_idleFaultRelease "Right electric parking brake: a249 idle fault release";
CM_ SG_ 1000 EPBR_a250_WinchModeCanceled "Right electric parking brake: a250 winch mode canceled";
CM_ SG_ 1000 EPBR_a251_currentVarianceHigh "Right electric parking brake: a251 current variance high";
CM_ SG_ 1000 EPBR_a252_winchModePending "Right electric parking brake: a252 winch mode pending";
CM_ SG_ 1000 EPBR_a253_esmReleaseBlocked "Right electric parking brake: a253 esm release blocked";
CM_ SG_ 1000 EPBR_a254_showStalkParkButtonFau "Right electric parking brake: a254 show stalk park button fault on ui";
CM_ SG_ 1000 EPBR_a256_epbSystemApply "Right electric parking brake: a256 epb system apply";
CM_ SG_ 1000 EPBR_a261_winchModeWithoutSteeri "Right electric parking brake: a261 winch mode without steering";
CM_ SG_ 1000 EPBR_a262_cannotPrepareWinchMode "Right electric parking brake: a262 cannot prepare winch mode";
CM_ SG_ 1000 EPBR_a263_epbRecoveryPark "Right electric parking brake: a263 epb recovery park";
CM_ SG_ 1000 EPBR_a264_winchModeDeactivated "Right electric parking brake: a264 winch mode deactivated";
CM_ SG_ 1000 EPBR_a272_vhclPwrStateMsmtch "Right electric parking brake: a272 vhcl pwr state msmtch";
CM_ SG_ 1000 EPBR_a300_leftRightConfusion "Right electric parking brake: a300 left right confusion";
CM_ SG_ 1000 EPBR_a301_oocSpeedViolation "Right electric parking brake: a301 ooc speed violation";
CM_ SG_ 1000 EPBR_a302_csmLongRelease "Right electric parking brake: a302 csm long release";
CM_ SG_ 1000 EPBR_a303_clampingOccuredEarly "Right electric parking brake: a303 clamping occured early";
CM_ SG_ 1000 EPBR_a304_rearSeatControllerEFus "Right electric parking brake: a304 rear seat controller e fuse trip";
CM_ SG_ 1000 EPBR_a305_premiumAmpEFuseTrip "Right electric parking brake: a305 premium amp e fuse trip";
CM_ SG_ 1000 EPBR_a350_ensOutOfRange "Right electric parking brake: a350 ens out of range";
CM_ SG_ 1000 EPBR_a352_audioCurrentSpikeData "Right electric parking brake: a352 audio current spike data";
CM_ SG_ 1000 EPBR_a353_missingSpeedUnableToPa "Right electric parking brake: a353 missing speed unable to park";
CM_ SG_ 1000 EPBR_a354_parkedForLowBrakeFluid "Right electric parking brake: a354 parked for low brake fluid mode";
CM_ SG_ 1000 EPBR_a355_brakeHwAndEpbHwMismatc "Right electric parking brake: a355 brake hw and epb hw mismatch";
CM_ SG_ 1000 EPBR_a356_parkingForStationaryDe "Right electric parking brake: a356 parking for stationary detect";
CM_ SG_ 1000 EPBR_a357_brakesTooHotForSlope "Right electric parking brake: a357 brakes too hot for slope";
CM_ SG_ 1000 EPBR_a358_brakesTooHotForSlopeWi "Right electric parking brake: a358 brakes too hot for slope with only one epb";
CM_ SG_ 1000 EPBR_a360_ibstBrakeSwitchInvalid "Right electric parking brake: a360 ibst brake switch invalid";
CM_ SG_ 1000 EPBR_a361_espBrakeSwitchInvalid "Right electric parking brake: a361 esp brake switch invalid";
CM_ SG_ 1000 EPBR_a362_ibstPressedEspNotPress "Right electric parking brake: a362 ibst pressed esp not pressed mismatch";
CM_ SG_ 1000 EPBR_a363_ibstNotPressedEspPress "Right electric parking brake: a363 ibst not pressed esp pressed mismatch";
CM_ SG_ 1000 EPBR_a364_espMasterCylCompOverTh "Right electric parking brake: a364 esp master cyl comp over threshold";
CM_ SG_ 1000 EPBR_a365_TooSteepToParkWithTrai "Right electric parking brake: a365 too steep to park with trailer warning";
CM_ SG_ 1000 EPBR_a366_TooSteepToParkWithTrai "Right electric parking brake: a366 too steep to park with trailer un sec env";
CM_ BO_ 742 "Right electric parking brake message: seat status3";
CM_ SG_ 742 EPBR_frontSeatCushionFanCur "Right electric parking brake: front seat cushion fan cur";
CM_ SG_ 742 EPBR_frontSeatBackrestFanCur "Right electric parking brake: front seat backrest fan cur";
CM_ SG_ 742 EPBR_frontSeatCushionFanDuty "Right electric parking brake: front seat cushion fan duty";
CM_ SG_ 742 EPBR_frontSeatCushionFanEn "Right electric parking brake: front seat cushion fan en";
CM_ SG_ 742 EPBR_frontSeatBackrestFanEn "Right electric parking brake: front seat backrest fan en";
CM_ SG_ 742 EPBR_frontSeatBackrestFanDuty "Right electric parking brake: front seat backrest fan duty";
CM_ BO_ 744 "Right electric parking brake message: status";
CM_ SG_ 744 EPBR_systemStatus "Coordinated state representing the vehicle level parking brake state.";
CM_ SG_ 744 EPBR_freeRollModeStatus "Right electric parking brake: free roll mode status";
CM_ SG_ 744 EPBR_driverIsLeaving "Right electric parking brake: driver is leaving";
CM_ SG_ 744 EPBR_driverIsLeavingAnySpeed "Right electric parking brake: driver is leaving any speed";
CM_ SG_ 744 EPBR_systemCdpAvailable "Right electric parking brake: system cdp available";
CM_ SG_ 744 EPBR_chimeRequest "Right electric parking brake: chime request";
CM_ SG_ 744 EPBR_telltale "Controls the telltale illumination on the instrument cluster; raw 7 = signal not available (SNA)";
CM_ SG_ 744 EPBR_audioCurrentSpikeDetected "Right electric parking brake: audio current spike detected";
CM_ SG_ 744 EPBR_redundantBrakingEnabled "Right electric parking brake: redundant braking enabled";
CM_ SG_ 744 EPBR_summonEnabled "Right electric parking brake: summon enabled";
CM_ SG_ 744 EPBR_brakeLight "Right electric parking brake: brake light";
CM_ SG_ 744 EPBR_epbConfigMismatch "Right electric parking brake: epb config mismatch";
CM_ SG_ 744 EPBR_brakeConfirmedPressed "Right electric parking brake: brake confirmed pressed";
CM_ SG_ 744 EPBR_requestUserConfirmation "Right electric parking brake: request user confirmation";
CM_ SG_ 744 EPBR_uiWinchModeMiscBlocking "Reports the expected appearance of system error message on User Interface (UI) winch mode panel.";
CM_ SG_ 744 EPBR_winchModeActive "Right electric parking brake: winch mode active";
CM_ SG_ 744 EPBR_updateMode "Right electric parking brake: update mode";
CM_ SG_ 744 EPBR_winchModePermissive "Right electric parking brake: winch mode permissive";
CM_ SG_ 744 EPBR_winchModePending "Right electric parking brake: winch mode pending";
CM_ SG_ 744 EPBR_cdpRequest "Right electric parking brake: cdp request";
CM_ SG_ 744 EPBR_uiParkAvailable "Reports the expected availability and appearance of the park button on User Interface (UI) safety panel.";
CM_ SG_ 744 EPBR_brakeDiscWipeRequest "Right electric parking brake: brake disc wipe request; raw 3 = signal not available (SNA)";
CM_ SG_ 744 EPBR_showUiGearShifter "Right electric parking brake: show ui gear shifter";
CM_ SG_ 744 EPBR_uiWinchModeLvStatus "Reports the expected availability and appearance of Low Voltage (LV) system status on UI winch mode panel.";
CM_ SG_ 744 EPBR_contactorCycleNotNeededForW "Right electric parking brake: contactor cycle not needed for winch entry";
CM_ SG_ 744 EPBR_showStalkFaultedOnUi "Right electric parking brake: show stalk faulted on ui";
CM_ SG_ 744 EPBR_espPowerRequest "Right electric parking brake: esp power request";
CM_ SG_ 744 EPBR_okToPark "Right electric parking brake: ok to park";
CM_ SG_ 744 EPBR_hornRequest "Right electric parking brake: horn request";
CM_ SG_ 744 EPBR_winchModeAvailable "Right electric parking brake: winch mode available";
CM_ SG_ 744 EPBR_bothDisconnected "Right electric parking brake: both disconnected";
CM_ SG_ 744 EPBR_blockDrive "Right electric parking brake: block drive";
CM_ SG_ 744 EPBR_statusCounter "Right electric parking brake: status counter";
CM_ SG_ 744 EPBR_statusChecksum "Right electric parking brake: status checksum";
CM_ BO_ 1575 "Right electric parking brake message: uds response";
CM_ SG_ 1575 EPBR_udsResponseData_H "Right electric parking brake: uds response data h";
CM_ SG_ 1575 EPBR_udsResponseData_L "Right electric parking brake: uds response data l";
CM_ BO_ 981 "Electronic stability control message: alert matrix";
CM_ SG_ 981 ESP_matrixIndex "Electronic stability control: matrix index";
CM_ SG_ 981 ESP_a001_ecuGenericFault "Electronic stability control: a001 ecu generic fault";
CM_ SG_ 981 ESP_a002_valvesGenericFault "Electronic stability control: a002 valves generic fault";
CM_ SG_ 981 ESP_a003_outletValvesFault "Electronic stability control: a003 outlet valves fault";
CM_ SG_ 981 ESP_a004_inletValvesFault "Electronic stability control: a004 inlet valves fault";
CM_ SG_ 981 ESP_a005_HSVValvesFault "Electronic stability control: a005 HSV valves fault";
CM_ SG_ 981 ESP_a006_USVValvesFault "Electronic stability control: a006 USV valves fault";
CM_ SG_ 981 ESP_a007_pumpMotorFault "Electronic stability control: a007 pump motor fault";
CM_ SG_ 981 ESP_a008_pumpMotor12VsupplyLow "Electronic stability control: a008 pump motor12 vsupply low";
CM_ SG_ 981 ESP_a009_12VHardUndervoltage "Electronic stability control: a009 12 v hard undervoltage";
CM_ SG_ 981 ESP_a010_12VUndervoltage "Electronic stability control: a010 12 v undervoltage";
CM_ SG_ 981 ESP_a011_12VSystemUndervoltage "Electronic stability control: a011 12 v system undervoltage";
CM_ SG_ 981 ESP_a012_netUndervoltage "Electronic stability control: a012 net undervoltage";
CM_ SG_ 981 ESP_a013_valveRelayUndervoltage "Electronic stability control: a013 valve relay undervoltage";
CM_ SG_ 981 ESP_a014_WSSSupplyUndervoltage "Electronic stability control: a014 WSS supply undervoltage";
CM_ SG_ 981 ESP_a015_12VSupplyOvervoltage "Electronic stability control: a015 12 v supply overvoltage";
CM_ SG_ 981 ESP_a016_12VSystemOvervoltage "Electronic stability control: a016 12 v system overvoltage";
CM_ SG_ 981 ESP_a017_netOvervoltage "Electronic stability control: a017 net overvoltage";
CM_ SG_ 981 ESP_a018_WSSSignFrontAxle "Electronic stability control: a018 WSS sign front axle";
CM_ SG_ 981 ESP_a019_WSSSignRearAxle "Electronic stability control: a019 WSS sign rear axle";
CM_ SG_ 981 ESP_a020_WSSGenericTempFault "Electronic stability control: a020 WSS generic temp fault";
CM_ SG_ 981 ESP_a021_WSSGeneralVDiffFault "Electronic stability control: a021 WSS general v diff fault";
CM_ SG_ 981 ESP_a022_WSSDirectionFault "Electronic stability control: a022 WSS direction fault";
CM_ SG_ 981 ESP_a023_WSSSeveralSuspected "Electronic stability control: a023 WSS several suspected";
CM_ SG_ 981 ESP_a024_WSSReverseCurrent "Electronic stability control: a024 WSS reverse current";
CM_ SG_ 981 ESP_a025_FrLWSSOpenOrShortToGnd "Electronic stability control: a025 fr LWSS open or short to gnd";
CM_ SG_ 981 ESP_a026_FrLWSSShortTo12V "Electronic stability control: a026 fr LWSS short to12 v";
CM_ SG_ 981 ESP_a027_FrLWSSLineInterruption "Electronic stability control: a027 fr LWSS line interruption";
CM_ SG_ 981 ESP_a028_FrLWSSMaxSpeedExceeded "Electronic stability control: a028 fr LWSS max speed exceeded";
CM_ SG_ 981 ESP_a029_FrLWSSTooManyPulses "Electronic stability control: a029 fr LWSS too many pulses";
CM_ SG_ 981 ESP_a030_FrLWSSLostSignal "Electronic stability control: a030 fr LWSS lost signal";
CM_ SG_ 981 ESP_a031_FrLWSSNoPulsesDetected "Electronic stability control: a031 fr LWSS no pulses detected";
CM_ SG_ 981 ESP_a032_FrLWSSWrongSensorType "Electronic stability control: a032 fr LWSS wrong sensor type";
CM_ SG_ 981 ESP_a033_FrLWSSSignalNoise "Electronic stability control: a033 fr LWSS signal noise";
CM_ SG_ 981 ESP_a034_FrLWSSVDiffFault "Electronic stability control: a034 fr LWSSV diff fault";
CM_ SG_ 981 ESP_a035_FrLWSSDirectionFault "Electronic stability control: a035 fr LWSS direction fault";
CM_ SG_ 981 ESP_a036_FrLWSSLargeAirGap "Electronic stability control: a036 fr LWSS large air gap";
CM_ SG_ 981 ESP_a037_FrLWSSSupplyShortToGnd "Electronic stability control: a037 fr LWSS supply short to gnd";
CM_ SG_ 981 ESP_a038_FrLWSSGeneralFault "Electronic stability control: a038 fr LWSS general fault";
CM_ SG_ 981 ESP_a039_FrRWSSOpenOrShortToGnd "Electronic stability control: a039 fr RWSS open or short to gnd";
CM_ SG_ 981 ESP_a040_FrRWSSShortTo12V "Electronic stability control: a040 fr RWSS short to12 v";
CM_ SG_ 981 ESP_a041_FrRWSSLineInterruption "Electronic stability control: a041 fr RWSS line interruption";
CM_ SG_ 981 ESP_a042_FrRWSSMaxSpeedExceeded "Electronic stability control: a042 fr RWSS max speed exceeded";
CM_ SG_ 981 ESP_a043_FrRWSSTooManyPulses "Electronic stability control: a043 fr RWSS too many pulses";
CM_ SG_ 981 ESP_a044_FrRWSSLostSignal "Electronic stability control: a044 fr RWSS lost signal";
CM_ SG_ 981 ESP_a045_FrRWSSNoPulsesDetected "Electronic stability control: a045 fr RWSS no pulses detected";
CM_ SG_ 981 ESP_a046_FrRWSSWrongSensorType "Electronic stability control: a046 fr RWSS wrong sensor type";
CM_ SG_ 981 ESP_a047_FrRWSSSignalNoise "Electronic stability control: a047 fr RWSS signal noise";
CM_ SG_ 981 ESP_a048_FrRWSSVDiffFault "Electronic stability control: a048 fr RWSSV diff fault";
CM_ SG_ 981 ESP_a049_FrRWSSDirectionFault "Electronic stability control: a049 fr RWSS direction fault";
CM_ SG_ 981 ESP_a050_FrRWSSLargeAirGap "Electronic stability control: a050 fr RWSS large air gap";
CM_ SG_ 981 ESP_a051_FrRWSSSupplyShortToGnd "Electronic stability control: a051 fr RWSS supply short to gnd";
CM_ SG_ 981 ESP_a052_FrRWSSGeneralFault "Electronic stability control: a052 fr RWSS general fault";
CM_ SG_ 981 ESP_a053_ReLWSSOpenOrShortToGnd "Electronic stability control: a053 re LWSS open or short to gnd";
CM_ SG_ 981 ESP_a054_ReLWSSShortTo12V "Electronic stability control: a054 re LWSS short to12 v";
CM_ SG_ 981 ESP_a055_ReLWSSLineInterruption "Electronic stability control: a055 re LWSS line interruption";
CM_ SG_ 981 ESP_a056_ReLWSSMaxSpeedExceeded "Electronic stability control: a056 re LWSS max speed exceeded";
CM_ SG_ 981 ESP_a057_ReLWSSTooManyPulses "Electronic stability control: a057 re LWSS too many pulses";
CM_ SG_ 981 ESP_a058_ReLWSSLostSignal "Electronic stability control: a058 re LWSS lost signal";
CM_ SG_ 981 ESP_a059_ReLWSSNoPulsesDetected "Electronic stability control: a059 re LWSS no pulses detected";
CM_ SG_ 981 ESP_a060_ReLWSSWrongSensorType "Electronic stability control: a060 re LWSS wrong sensor type";
CM_ SG_ 981 ESP_a061_ReLWSSSignalNoise "Electronic stability control: a061 re LWSS signal noise";
CM_ SG_ 981 ESP_a062_ReLWSSVDiffFault "Electronic stability control: a062 re LWSSV diff fault";
CM_ SG_ 981 ESP_a063_ReLWSSDirectionFault "Electronic stability control: a063 re LWSS direction fault";
CM_ SG_ 981 ESP_a064_ReLWSSLargeAirGap "Electronic stability control: a064 re LWSS large air gap";
CM_ SG_ 981 ESP_a065_ReLWSSSupplyShortToGnd "Electronic stability control: a065 re LWSS supply short to gnd";
CM_ SG_ 981 ESP_a066_ReLWSSGeneralFault "Electronic stability control: a066 re LWSS general fault";
CM_ SG_ 981 ESP_a067_ReRWSSOpenOrShortToGnd "Electronic stability control: a067 re RWSS open or short to gnd";
CM_ SG_ 981 ESP_a068_ReRWSSShortTo12V "Electronic stability control: a068 re RWSS short to12 v";
CM_ SG_ 981 ESP_a069_ReRWSSLineInterruption "Electronic stability control: a069 re RWSS line interruption";
CM_ SG_ 981 ESP_a070_ReRWSSMaxSpeedExceeded "Electronic stability control: a070 re RWSS max speed exceeded";
CM_ SG_ 981 ESP_a071_ReRWSSTooManyPulses "Electronic stability control: a071 re RWSS too many pulses";
CM_ SG_ 981 ESP_a072_ReRWSSLostSignal "Electronic stability control: a072 re RWSS lost signal";
CM_ SG_ 981 ESP_a073_ReRWSSNoPulsesDetected "Electronic stability control: a073 re RWSS no pulses detected";
CM_ SG_ 981 ESP_a074_ReRWSSWrongSensorType "Electronic stability control: a074 re RWSS wrong sensor type";
CM_ SG_ 981 ESP_a075_ReRWSSSignalNoise "Electronic stability control: a075 re RWSS signal noise";
CM_ SG_ 981 ESP_a076_ReRWSSVDiffFault "Electronic stability control: a076 re RWSSV diff fault";
CM_ SG_ 981 ESP_a077_ReRWSSDirectionFault "Electronic stability control: a077 re RWSS direction fault";
CM_ SG_ 981 ESP_a078_ReRWSSLargeAirGap "Electronic stability control: a078 re RWSS large air gap";
CM_ SG_ 981 ESP_a079_ReRWSSSupplyShortToGnd "Electronic stability control: a079 re RWSS supply short to gnd";
CM_ SG_ 981 ESP_a080_ReRWSSGeneralFault "Electronic stability control: a080 re RWSS general fault";
CM_ SG_ 981 ESP_a081_PressureSensorShort "Electronic stability control: a081 pressure sensor short";
CM_ SG_ 981 ESP_a082_PMCSensorOffsetHigh "Electronic stability control: a082 PMC sensor offset high";
CM_ SG_ 981 ESP_a083_PMCSensorFault "Electronic stability control: a083 PMC sensor fault";
CM_ SG_ 981 ESP_a084_BrakeFluidReservoirLow "Electronic stability control: a084 brake fluid reservoir low";
CM_ SG_ 981 ESP_a085_BrakeSwitchStuckHigh "Electronic stability control: a085 brake switch stuck high";
CM_ SG_ 981 ESP_a086_BrakeSwitchImplausible1 "Electronic stability control: a086 brake switch implausible1";
CM_ SG_ 981 ESP_a087_BrakeSwitchImplausible3 "Electronic stability control: a087 brake switch implausible3";
CM_ SG_ 981 ESP_a088_absContinuousControl "Electronic stability control: a088 abs continuous control";
CM_ SG_ 981 ESP_a089_absNoPressureIncrease "Electronic stability control: a089 abs no pressure increase";
CM_ SG_ 981 ESP_a090_vdcContinuousControl "Electronic stability control: a090 vdc continuous control";
CM_ SG_ 981 ESP_a091_CANUndervoltage "Electronic stability control: a091 CAN undervoltage";
CM_ SG_ 981 ESP_a092_CANOvervoltage "Electronic stability control: a092 CAN overvoltage";
CM_ SG_ 981 ESP_a093_partyBusOff "Electronic stability control: a093 party bus off";
CM_ SG_ 981 ESP_a094_partyBusPassive "Electronic stability control: a094 party bus passive";
CM_ SG_ 981 ESP_a095_chassisBusOff "Electronic stability control: a095 chassis bus off";
CM_ SG_ 981 ESP_a096_chassisBusPassive "Electronic stability control: a096 chassis bus passive";
CM_ SG_ 981 ESP_a097_tcsRefSpeedNotInit "Electronic stability control: a097 tcs ref speed not init";
CM_ SG_ 981 ESP_a098_vdcRefSpeedNotInit "Electronic stability control: a098 vdc ref speed not init";
CM_ SG_ 981 ESP_a099_brakeTempModelOverheat "Electronic stability control: a099 brake temp model overheat";
CM_ SG_ 981 ESP_a100_brakeTempModelDisabled "Electronic stability control: a100 brake temp model disabled";
CM_ SG_ 981 ESP_a101_ebdFault "Electronic stability control: a101 ebd fault";
CM_ SG_ 981 ESP_a102_absFault "Electronic stability control: a102 abs fault";
CM_ SG_ 981 ESP_a103_stabilityControlFault "Electronic stability control: a103 stability control fault";
CM_ SG_ 981 ESP_a104_hbcEnabled "Electronic stability control: a104 hbc enabled";
CM_ SG_ 981 ESP_a105_ebrFault "Electronic stability control: a105 ebr fault";
CM_ SG_ 981 ESP_a106_vdcActuatorFault "Electronic stability control: a106 vdc actuator fault";
CM_ SG_ 981 ESP_a107_reserved107 "Electronic stability control: a107 reserved107";
CM_ SG_ 981 ESP_a108_reserved108 "Electronic stability control: a108 reserved108";
CM_ SG_ 981 ESP_a109_reserved109 "Electronic stability control: a109 reserved109";
CM_ SG_ 981 ESP_a110_rollerBenchActive "Electronic stability control: a110 roller bench active";
CM_ SG_ 981 ESP_a111_absActive "Electronic stability control: a111 abs active";
CM_ SG_ 981 ESP_a112_espActive "Electronic stability control: a112 esp active";
CM_ SG_ 981 ESP_a113_btcActive "Electronic stability control: a113 btc active";
CM_ SG_ 981 ESP_a114_tvdcActive "Electronic stability control: a114 tvdc active";
CM_ SG_ 981 ESP_a115_ebdActive "Electronic stability control: a115 ebd active";
CM_ SG_ 981 ESP_a116_tsmActive "Electronic stability control: a116 tsm active";
CM_ SG_ 981 ESP_a117_hbaActive "Electronic stability control: a117 hba active";
CM_ SG_ 981 ESP_a118_hfcActive "Electronic stability control: a118 hfc active";
CM_ SG_ 981 ESP_a119_hbbActive "Electronic stability control: a119 hbb active";
CM_ SG_ 981 ESP_a120_rmiActive "Electronic stability control: a120 rmi active";
CM_ SG_ 981 ESP_a121_regenTcActive "Electronic stability control: a121 regen tc active";
CM_ SG_ 981 ESP_a122_bdwActive "Electronic stability control: a122 bdw active";
CM_ SG_ 981 ESP_a123_ebrActive "Electronic stability control: a123 ebr active";
CM_ SG_ 981 ESP_a124_ebrSkidActive "Electronic stability control: a124 ebr skid active";
CM_ SG_ 981 ESP_a125_reserved125 "Electronic stability control: a125 reserved125";
CM_ SG_ 981 ESP_a126_reserved126 "Electronic stability control: a126 reserved126";
CM_ SG_ 981 ESP_a127_reserved127 "Electronic stability control: a127 reserved127";
CM_ SG_ 981 ESP_a128_reserved128 "Electronic stability control: a128 reserved128";
CM_ SG_ 981 ESP_a129_reserved129 "Electronic stability control: a129 reserved129";
CM_ SG_ 981 ESP_a130_EPAS3PsysStatusTimeout "Electronic stability control: a130 EPAS3 psys status timeout";
CM_ SG_ 981 ESP_a131_EPAS3PsysStatusDLC "Electronic stability control: a131 EPAS3 psys status DLC";
CM_ SG_ 981 ESP_a132_EPAS3PsysStatusChecksum "Electronic stability control: a132 EPAS3 psys status checksum";
CM_ SG_ 981 ESP_a133_EPAS3PsysStatusCounter "Electronic stability control: a133 EPAS3 psys status counter";
CM_ SG_ 981 ESP_a134_steeringAngleInvalid "Electronic stability control: a134 steering angle invalid";
CM_ SG_ 981 ESP_a135_steeringAngleNoCenter "Electronic stability control: a135 steering angle no center";
CM_ SG_ 981 ESP_a136_steeringAngleFrozen "Electronic stability control: a136 steering angle frozen";
CM_ SG_ 981 ESP_a137_steeringOffsetTooLarge "Electronic stability control: a137 steering offset too large";
CM_ SG_ 981 ESP_a138_steeringAngleImplaus "Electronic stability control: a138 steering angle implaus";
CM_ SG_ 981 ESP_a139_steeringAngleWrongSign "Electronic stability control: a139 steering angle wrong sign";
CM_ SG_ 981 ESP_a140_RCMInertial1Timeout "Electronic stability control: a140 RCM inertial1 timeout";
CM_ SG_ 981 ESP_a141_RCMInertial1DLC "Electronic stability control: a141 RCM inertial1 DLC";
CM_ SG_ 981 ESP_a142_RCMInertial1Checksum "Electronic stability control: a142 RCM inertial1 checksum";
CM_ SG_ 981 ESP_a143_RCMInertial1Counter "Electronic stability control: a143 RCM inertial1 counter";
CM_ SG_ 981 ESP_a144_yawMaxLatency "Electronic stability control: a144 yaw max latency";
CM_ SG_ 981 ESP_a145_yawInitFault "Electronic stability control: a145 yaw init fault";
CM_ SG_ 981 ESP_a146_yawInvalidValue "Electronic stability control: a146 yaw invalid value";
CM_ SG_ 981 ESP_a147_yawSensorNotAvailable "Electronic stability control: a147 yaw sensor not available";
CM_ SG_ 981 ESP_a148_yawSignalFault "Electronic stability control: a148 yaw signal fault";
CM_ SG_ 981 ESP_a149_yawInvalidSign "Electronic stability control: a149 yaw invalid sign";
CM_ SG_ 981 ESP_a150_yawImplausible "Electronic stability control: a150 yaw implausible";
CM_ SG_ 981 ESP_a151_RCMInertial2Timeout "Electronic stability control: a151 RCM inertial2 timeout";
CM_ SG_ 981 ESP_a152_RCMInertial2DLC "Electronic stability control: a152 RCM inertial2 DLC";
CM_ SG_ 981 ESP_a153_RCMInertial2Checksum "Electronic stability control: a153 RCM inertial2 checksum";
CM_ SG_ 981 ESP_a154_RCMInertial2Counter "Electronic stability control: a154 RCM inertial2 counter";
CM_ SG_ 981 ESP_a155_ayMaxLatency "Electronic stability control: a155 ay max latency";
CM_ SG_ 981 ESP_a156_ayInitFault "Electronic stability control: a156 ay init fault";
CM_ SG_ 981 ESP_a157_ayInvalidValue "Electronic stability control: a157 ay invalid value";
CM_ SG_ 981 ESP_a158_aySensorNotAvailable "Electronic stability control: a158 ay sensor not available";
CM_ SG_ 981 ESP_a159_aySignalFault "Electronic stability control: a159 ay signal fault";
CM_ SG_ 981 ESP_a160_ayRangeExceeded "Electronic stability control: a160 ay range exceeded";
CM_ SG_ 981 ESP_a161_ayOffsetExceeded "Electronic stability control: a161 ay offset exceeded";
CM_ SG_ 981 ESP_a162_ayImplausible "Electronic stability control: a162 ay implausible";
CM_ SG_ 981 ESP_a163_axMaxLatency "Electronic stability control: a163 ax max latency";
CM_ SG_ 981 ESP_a164_axInitFault "Electronic stability control: a164 ax init fault";
CM_ SG_ 981 ESP_a165_axInvalidValue "Electronic stability control: a165 ax invalid value";
CM_ SG_ 981 ESP_a166_axSensorNotAvailable "Electronic stability control: a166 ax sensor not available";
CM_ SG_ 981 ESP_a167_axSignalFault "Electronic stability control: a167 ax signal fault";
CM_ SG_ 981 ESP_a168_axRangeExceeded "Electronic stability control: a168 ax range exceeded";
CM_ SG_ 981 ESP_a169_axOffsetExceeded "Electronic stability control: a169 ax offset exceeded";
CM_ SG_ 981 ESP_a170_axSignalFrozen "Electronic stability control: a170 ax signal frozen";
CM_ SG_ 981 ESP_a171_axImplausible "Electronic stability control: a171 ax implausible";
CM_ SG_ 981 ESP_a172_IBSTparty1Timeout "Electronic stability control: a172 IBS tparty1 timeout";
CM_ SG_ 981 ESP_a173_IBSTparty1DLC "Electronic stability control: a173 IBS tparty1 DLC";
CM_ SG_ 981 ESP_a174_IBSTparty1Checksum "Electronic stability control: a174 IBS tparty1 checksum";
CM_ SG_ 981 ESP_a175_IBSTparty1Counter "Electronic stability control: a175 IBS tparty1 counter";
CM_ SG_ 981 ESP_a176_IBSTEBRNotAvailable "Electronic stability control: a176 IBSTEBR not available";
CM_ SG_ 981 ESP_a177_IBSTOutputRodDrvInvalid "Electronic stability control: a177 IBST output rod drv invalid";
CM_ SG_ 981 ESP_a178_IBSTOutputRodActInvalid "Electronic stability control: a178 IBST output rod act invalid";
CM_ SG_ 981 ESP_a179_IBSTparty2Timeout "Electronic stability control: a179 IBS tparty2 timeout";
CM_ SG_ 981 ESP_a180_IBSTparty2Checksum "Electronic stability control: a180 IBS tparty2 checksum";
CM_ SG_ 981 ESP_a181_IBSTparty2DLC "Electronic stability control: a181 IBS tparty2 DLC";
CM_ SG_ 981 ESP_a182_IBSTparty2Counter "Electronic stability control: a182 IBS tparty2 counter";
CM_ SG_ 981 ESP_a183_IBSTStatusOff "Electronic stability control: a183 IBST status off";
CM_ SG_ 981 ESP_a184_IBSTpRunoutInvalid "Electronic stability control: a184 IBS tp runout invalid";
CM_ SG_ 981 ESP_a185_IBSTFeedforwardBackup "Electronic stability control: a185 IBST feedforward backup";
CM_ SG_ 981 ESP_a186_IBSTBrakeAppliedInvalid "Electronic stability control: a186 IBST brake applied invalid";
CM_ SG_ 981 ESP_a187_DIbtcRequestTimeout "Electronic stability control: a187 d ibtc request timeout";
CM_ SG_ 981 ESP_a188_DIbtcRequestDLC "Electronic stability control: a188 d ibtc request DLC";
CM_ SG_ 981 ESP_a189_DIbtcRequestChecksum "Electronic stability control: a189 d ibtc request checksum";
CM_ SG_ 981 ESP_a190_DIbtcRequestCounter "Electronic stability control: a190 d ibtc request counter";
CM_ SG_ 981 ESP_a191_DIchassisControlTimeout "Electronic stability control: a191 d ichassis control timeout";
CM_ SG_ 981 ESP_a192_DIchassisControlDLC "Electronic stability control: a192 d ichassis control DLC";
CM_ SG_ 981 ESP_a193_DIchassisControlChecksu "Electronic stability control: a193 d ichassis control checksum";
CM_ SG_ 981 ESP_a194_DIchassisControlCounter "Electronic stability control: a194 d ichassis control counter";
CM_ SG_ 981 ESP_a195_ptcStateInvalid "Electronic stability control: a195 ptc state invalid";
CM_ SG_ 981 ESP_a196_DIsystemStatusTimeout "Electronic stability control: a196 d isystem status timeout";
CM_ SG_ 981 ESP_a197_DIsystemStatusDLC "Electronic stability control: a197 d isystem status DLC";
CM_ SG_ 981 ESP_a198_DIsystemStatusChecksum "Electronic stability control: a198 d isystem status checksum";
CM_ SG_ 981 ESP_a199_DIsystemStatusCounter "Electronic stability control: a199 d isystem status counter";
CM_ SG_ 981 ESP_a200_reverseGearStuckHigh "Electronic stability control: a200 reverse gear stuck high";
CM_ SG_ 981 ESP_a201_reverseGearStuckLow "Electronic stability control: a201 reverse gear stuck low";
CM_ SG_ 981 ESP_a202_accelPedalInvalid "Electronic stability control: a202 accel pedal invalid";
CM_ SG_ 981 ESP_a203_DItorqueTimeout "Electronic stability control: a203 d itorque timeout";
CM_ SG_ 981 ESP_a204_DItorqueDLC "Electronic stability control: a204 d itorque DLC";
CM_ SG_ 981 ESP_a205_DItorqueChecksum "Electronic stability control: a205 d itorque checksum";
CM_ SG_ 981 ESP_a206_DItorqueCounter "Electronic stability control: a206 d itorque counter";
CM_ SG_ 981 ESP_a207_DITorqueCommandInvalid "Electronic stability control: a207 DI torque command invalid";
CM_ SG_ 981 ESP_a208_DIRPMInvalid "Electronic stability control: a208 DIRPM invalid";
CM_ SG_ 981 ESP_a209_DITorqueActualInvalid "Electronic stability control: a209 DI torque actual invalid";
CM_ SG_ 981 ESP_a210_DIStorqueTimeout "Electronic stability control: a210 DI storque timeout";
CM_ SG_ 981 ESP_a211_DIStorqueDLC "Electronic stability control: a211 DI storque DLC";
CM_ SG_ 981 ESP_a212_DIStorqueChecksum "Electronic stability control: a212 DI storque checksum";
CM_ SG_ 981 ESP_a213_DIStorqueCounter "Electronic stability control: a213 DI storque counter";
CM_ SG_ 981 ESP_a214_DISTorqueCommandInvalid "Electronic stability control: a214 DIS torque command invalid";
CM_ SG_ 981 ESP_a215_DISRPMInvalid "Electronic stability control: a215 DISRPM invalid";
CM_ SG_ 981 ESP_a216_DISTorqueActualInvalid "Electronic stability control: a216 DIS torque actual invalid";
CM_ SG_ 981 ESP_a217_DIvdcLeftTimeout "Electronic stability control: a217 d ivdc left timeout";
CM_ SG_ 981 ESP_a218_DIvdcLeftDLC "Electronic stability control: a218 d ivdc left DLC";
CM_ SG_ 981 ESP_a219_DIvdcLeftChecksum "Electronic stability control: a219 d ivdc left checksum";
CM_ SG_ 981 ESP_a220_DIvdcLeftCounter "Electronic stability control: a220 d ivdc left counter";
CM_ SG_ 981 ESP_a221_DIvdcRightTimeout "Electronic stability control: a221 d ivdc right timeout";
CM_ SG_ 981 ESP_a222_DIvdcRightDLC "Electronic stability control: a222 d ivdc right DLC";
CM_ SG_ 981 ESP_a223_DIvdcRightChecksum "Electronic stability control: a223 d ivdc right checksum";
CM_ SG_ 981 ESP_a224_DIvdcRightCounter "Electronic stability control: a224 d ivdc right counter";
CM_ SG_ 981 ESP_a225_configMismatch "Electronic stability control: a225 config mismatch";
CM_ SG_ 981 ESP_a226_bdwRequestInvalid "Electronic stability control: a226 bdw request invalid";
CM_ SG_ 981 ESP_a227_bdwRequestActiveInvalid "Electronic stability control: a227 bdw request active invalid";
CM_ SG_ 981 ESP_a228_GTWvinTimeout "Electronic stability control: a228 GT wvin timeout";
CM_ SG_ 981 ESP_a229_GTWvinDLC "Electronic stability control: a229 GT wvin DLC";
CM_ SG_ 981 ESP_a230_vinNotLearned "Electronic stability control: a230 vin not learned";
CM_ SG_ 981 ESP_a231_storedVINMismatch "Electronic stability control: a231 stored VIN mismatch";
CM_ SG_ 981 ESP_a232_PMstate2Timeout "Electronic stability control: a232 p mstate2 timeout";
CM_ SG_ 981 ESP_a233_PMstate2Checksum "Electronic stability control: a233 p mstate2 checksum";
CM_ SG_ 981 ESP_a234_PMstate2DLC "Electronic stability control: a234 p mstate2 DLC";
CM_ SG_ 981 ESP_a235_PMstate2Counter "Electronic stability control: a235 p mstate2 counter";
CM_ SG_ 981 ESP_a236_ebrCommandStateInvalid "Electronic stability control: a236 ebr command state invalid";
CM_ SG_ 981 ESP_a237_vdcCommandStateInvalid "Electronic stability control: a237 vdc command state invalid";
CM_ SG_ 981 ESP_a238_UIodoTimeout "Electronic stability control: a238 u iodo timeout";
CM_ SG_ 981 ESP_a239_UIodoDLC "Electronic stability control: a239 u iodo DLC";
CM_ SG_ 981 ESP_a240_LVPowerStateTimeout "Electronic stability control: a240 LV power state timeout";
CM_ SG_ 981 ESP_a241_LVPowerStateChecksum "Electronic stability control: a241 LV power state checksum";
CM_ SG_ 981 ESP_a242_LVPowerStateDLC "Electronic stability control: a242 LV power state DLC";
CM_ SG_ 981 ESP_a243_LVPowerStateCounter "Electronic stability control: a243 LV power state counter";
CM_ SG_ 981 ESP_a244_LVOffStateInvalid "Electronic stability control: a244 LV off state invalid";
CM_ SG_ 981 ESP_a245_LVGoingDownStateInvalid "Electronic stability control: a245 LV going down state invalid";
CM_ SG_ 981 ESP_a246_VCFRONTsensorTimeout "Electronic stability control: a246 VCFRON tsensor timeout";
CM_ SG_ 981 ESP_a247_VCFRONTsensorDLC "Electronic stability control: a247 VCFRON tsensor DLC";
CM_ SG_ 981 ESP_a248_vdcBrkeTrqTarFrLInvalid "Electronic stability control: a248 vdc brke trq tar fr l invalid";
CM_ SG_ 981 ESP_a249_vdcBrkeTrqTarFrRInvalid "Electronic stability control: a249 vdc brke trq tar fr r invalid";
CM_ SG_ 981 ESP_a250_vdcBrkeTrqTarReLInvalid "Electronic stability control: a250 vdc brke trq tar re l invalid";
CM_ SG_ 981 ESP_a251_vdcBrkeTrqTarReRInvalid "Electronic stability control: a251 vdc brke trq tar re r invalid";
CM_ SG_ 981 ESP_a252_vdcWhlSlipLimFrLInvalid "Electronic stability control: a252 vdc whl slip lim fr l invalid";
CM_ SG_ 981 ESP_a253_vdcWhlSlipLimFrRInvalid "Electronic stability control: a253 vdc whl slip lim fr r invalid";
CM_ SG_ 981 ESP_a254_vdcWhlSlipLimReLInvalid "Electronic stability control: a254 vdc whl slip lim re l invalid";
CM_ SG_ 981 ESP_a255_vdcWhlSlipLimReRInvalid "Electronic stability control: a255 vdc whl slip lim re r invalid";
CM_ SG_ 981 ESP_a256_epbmStatusTimeout "Electronic stability control: a256 epbm status timeout";
CM_ SG_ 981 ESP_a257_epbmStatusChecksum "Electronic stability control: a257 epbm status checksum";
CM_ SG_ 981 ESP_a258_epbmStatusDLC "Electronic stability control: a258 epbm status DLC";
CM_ SG_ 981 ESP_a259_epbmStatusCounter "Electronic stability control: a259 epbm status counter";
CM_ SG_ 981 ESP_a260_epblStatusTimeout "Electronic stability control: a260 epbl status timeout";
CM_ SG_ 981 ESP_a261_epblStatusChecksum "Electronic stability control: a261 epbl status checksum";
CM_ SG_ 981 ESP_a262_epblStatusDLC "Electronic stability control: a262 epbl status DLC";
CM_ SG_ 981 ESP_a263_epblStatusCounter "Electronic stability control: a263 epbl status counter";
CM_ SG_ 981 ESP_a264_pumpSpeedLimitInvalid "Electronic stability control: a264 pump speed limit invalid";
CM_ SG_ 981 ESP_a265_DIRELtorqueTimeout "Electronic stability control: a265 DIRE ltorque timeout";
CM_ SG_ 981 ESP_a266_DIRELtorqueDLC "Electronic stability control: a266 DIRE ltorque DLC";
CM_ SG_ 981 ESP_a267_DIRELtorqueChecksum "Electronic stability control: a267 DIRE ltorque checksum";
CM_ SG_ 981 ESP_a268_DIRELtorqueCounter "Electronic stability control: a268 DIRE ltorque counter";
CM_ SG_ 981 ESP_a269_DIRELTorqueCommandInval "Electronic stability control: a269 DIREL torque command invalid";
CM_ SG_ 981 ESP_a270_DIRELRPMInvalid "Electronic stability control: a270 DIRELRPM invalid";
CM_ SG_ 981 ESP_a271_DIRELTorqueActualInvali "Electronic stability control: a271 DIREL torque actual invalid";
CM_ SG_ 981 ESP_a272_DIRERtorqueTimeout "Electronic stability control: a272 DIRE rtorque timeout";
CM_ SG_ 981 ESP_a273_DIRERtorqueDLC "Electronic stability control: a273 DIRE rtorque DLC";
CM_ SG_ 981 ESP_a274_DIRERtorqueChecksum "Electronic stability control: a274 DIRE rtorque checksum";
CM_ SG_ 981 ESP_a275_DIRERtorqueCounter "Electronic stability control: a275 DIRE rtorque counter";
CM_ SG_ 981 ESP_a276_DIRERTorqueCommandInval "Electronic stability control: a276 DIRER torque command invalid";
CM_ SG_ 981 ESP_a277_DIRERRPMInvalid "Electronic stability control: a277 DIRERRPM invalid";
CM_ SG_ 981 ESP_a278_DIRERTorqueActualInvali "Electronic stability control: a278 DIRER torque actual invalid";
CM_ SG_ 981 ESP_a279_lifetimeManagementOverr "Electronic stability control: a279 lifetime management overrun";
CM_ SG_ 981 ESP_a280_trackModeABSEnabled "Electronic stability control: a280 track mode ABS enabled";
CM_ SG_ 981 ESP_a281_trackModeABSdisabled "Electronic stability control: a281 track mode AB sdisabled";
CM_ SG_ 981 ESP_a282_trackModeABSRequestInva "Electronic stability control: a282 track mode ABS request invalid";
CM_ SG_ 981 ESP_a283_secondaryCollisionMitig "Electronic stability control: a283 secondary collision mitigation active";
CM_ SG_ 981 ESP_a284_scmRequestInvalidChecks "Electronic stability control: a284 scm request invalid checksum";
CM_ SG_ 981 ESP_a285_scmRequestDLC "Electronic stability control: a285 scm request DLC";
CM_ SG_ 981 ESP_a286_hydroplaneDetected "Electronic stability control: a286 hydroplane detected";
CM_ SG_ 981 ESP_a287_failedBrakeCircuitDetec "Electronic stability control: a287 failed brake circuit detected";
CM_ SG_ 981 ESP_a288_leftBusOff "Electronic stability control: a288 left bus off";
CM_ SG_ 981 ESP_a289_leftBusPassive "Electronic stability control: a289 left bus passive";
CM_ SG_ 981 ESP_a290_brakeBusOff "Electronic stability control: a290 brake bus off";
CM_ SG_ 981 ESP_a291_brakeBusPassive "Electronic stability control: a291 brake bus passive";
CM_ SG_ 981 ESP_a292_PEPSstatusTimeout "Electronic stability control: a292 PEP sstatus timeout";
CM_ SG_ 981 ESP_a293_PEPSstatusDLC "Electronic stability control: a293 PEP sstatus DLC";
CM_ SG_ 981 ESP_a294_PEPSstatusChecksum "Electronic stability control: a294 PEP sstatus checksum";
CM_ SG_ 981 ESP_a295_PEPSstatusCounter "Electronic stability control: a295 PEP sstatus counter";
CM_ SG_ 981 ESP_a296_roadWheelAngleHealthDeg "Electronic stability control: a296 road wheel angle health degraded";
CM_ SG_ 981 ESP_a297_roadWheelAngleHealthFau "Electronic stability control: a297 road wheel angle health faulted";
CM_ SG_ 981 ESP_a298_RSArearSteerStatusTimeo "Electronic stability control: a298 RS arear steer status timeout";
CM_ SG_ 981 ESP_a299_RSArearSteerStatusDLC "Electronic stability control: a299 RS arear steer status DLC";
CM_ SG_ 981 ESP_a300_RSArearSteerStatusCheck "Electronic stability control: a300 RS arear steer status checksum";
CM_ SG_ 981 ESP_a301_PEPSstatusCounter "Electronic stability control: a301 PEP sstatus counter";
CM_ SG_ 981 ESP_a302_rearRoadWheelAngleHealt "Electronic stability control: a302 rear road wheel angle health degraded";
CM_ SG_ 981 ESP_a303_rearRoadWheelAngleHealt "Electronic stability control: a303 rear road wheel angle health faulted";
CM_ SG_ 981 ESP_a304_rearVCLVPowerStateTimeo "Electronic stability control: a304 rear VCLV power state timeout";
CM_ SG_ 981 ESP_a305_rearVCLVPowerStateDLC "Electronic stability control: a305 rear VCLV power state DLC";
CM_ SG_ 981 ESP_a306_rearVCLVPowerStateCheck "Electronic stability control: a306 rear VCLV power state checksum";
CM_ SG_ 981 ESP_a307_rearVCLVPowerStateCount "Electronic stability control: a307 rear VCLV power state counter";
CM_ SG_ 981 ESP_a308_evacFillNotComplete "Electronic stability control: a308 evac fill not complete";
CM_ SG_ 981 ESP_a309_factoryModeActive "Electronic stability control: a309 factory mode active";
CM_ SG_ 981 ESP_a310_brakeLatencyReductionAc "Electronic stability control: a310 brake latency reduction active";
CM_ SG_ 981 ESP_a311_aesActive "Electronic stability control: a311 aes active";
CM_ SG_ 981 ESP_a312_undefinedAlertDetected "Electronic stability control: a312 undefined alert detected";
CM_ SG_ 981 ESP_a313_cdpRequestStateInvalid "Electronic stability control: a313 cdp request state invalid";
CM_ SG_ 981 ESP_a314_aesFault "Electronic stability control: a314 aes fault";
CM_ SG_ 981 ESP_a315_EMCBackup11Timeout "Electronic stability control: a315 EMC backup11 timeout";
CM_ SG_ 981 ESP_a316_EMCBackup11DLC "Electronic stability control: a316 EMC backup11 DLC";
CM_ SG_ 981 ESP_a317_EMCBackup11Checksum "Electronic stability control: a317 EMC backup11 checksum";
CM_ SG_ 981 ESP_a318_EMCBackup11Counter "Electronic stability control: a318 EMC backup11 counter";
CM_ SG_ 981 ESP_a319_AES_BackupActuatorActiv "Electronic stability control: a319 AES backup actuator active";
CM_ SG_ 981 ESP_a320_DPB_actuator1Counter "Electronic stability control: a320 DPB actuator1 counter";
CM_ SG_ 981 ESP_a321_DPB_actuator1Checksum "Electronic stability control: a321 DPB actuator1 checksum";
CM_ SG_ 981 ESP_a322_DPB_actuator1DLC "Electronic stability control: a322 DPB actuator1 DLC";
CM_ SG_ 981 ESP_a323_DPB_actuator1Timeout "Electronic stability control: a323 DPB actuator1 timeout";
CM_ SG_ 981 ESP_a324_DPB_actuator2Counter "Electronic stability control: a324 DPB actuator2 counter";
CM_ SG_ 981 ESP_a325_DPB_actuator2Checksum "Electronic stability control: a325 DPB actuator2 checksum";
CM_ SG_ 981 ESP_a326_DPB_actuator2DLC "Electronic stability control: a326 DPB actuator2 DLC";
CM_ SG_ 981 ESP_a327_DPB_actuator2Timeout "Electronic stability control: a327 DPB actuator2 timeout";
CM_ SG_ 981 ESP_a328_DPB_actuator3Counter "Electronic stability control: a328 DPB actuator3 counter";
CM_ SG_ 981 ESP_a329_DPB_actuator3Checksum "Electronic stability control: a329 DPB actuator3 checksum";
CM_ SG_ 981 ESP_a330_DPB_actuator3DLC "Electronic stability control: a330 DPB actuator3 DLC";
CM_ SG_ 981 ESP_a331_DPB_actuator3Timeout "Electronic stability control: a331 DPB actuator3 timeout";
CM_ SG_ 981 ESP_a332_PressureSensorValHigh "Electronic stability control: a332 pressure sensor val high";
CM_ SG_ 981 ESP_a333_ActCircuitNoPressure "Electronic stability control: a333 act circuit no pressure";
CM_ SG_ 981 ESP_a334_BrakePedalAppliedInvali "Electronic stability control: a334 brake pedal applied invalid";
CM_ SG_ 981 ESP_a335_LdmFxTarBrakeActInvalid "Electronic stability control: a335 ldm fx tar brake act invalid";
CM_ SG_ 981 ESP_a336_FxTargetDriverInvalid "Electronic stability control: a336 fx target driver invalid";
CM_ SG_ 981 ESP_a337_pReductionPotentialInva "Electronic stability control: a337 p reduction potential invalid";
CM_ SG_ 981 ESP_a338_pRunoutInvalid "Electronic stability control: a338 p runout invalid";
CM_ SG_ 981 ESP_a339_sInputRodInvalid "Electronic stability control: a339 s input rod invalid";
CM_ SG_ 981 ESP_a340_RollerBenchMisuse "Electronic stability control: a340 roller bench misuse";
CM_ SG_ 981 ESP_a341_EnhancedPressureBuildAc "Electronic stability control: a341 enhanced pressure build active";
CM_ SG_ 981 ESP_a342_EnhancedPressureBuildNo "Electronic stability control: a342 enhanced pressure build not active";
CM_ SG_ 981 ESP_a343_EnhancedPressureBuildLt "Electronic stability control: a343 enhanced pressure build ltm reached";
CM_ SG_ 981 ESP_a344_DIbrakeCommandCounter "Electronic stability control: a344 d ibrake command counter";
CM_ SG_ 981 ESP_a345_DIbrakeCommandChecksum "Electronic stability control: a345 d ibrake command checksum";
CM_ SG_ 981 ESP_a346_DIbrakeCommandDLC "Electronic stability control: a346 d ibrake command DLC";
CM_ SG_ 981 ESP_a347_DIbrakeCommandTimeout "Electronic stability control: a347 d ibrake command timeout";
CM_ SG_ 981 ESP_a348_brakeCmdStateInvalid "Electronic stability control: a348 brake cmd state invalid";
CM_ SG_ 981 ESP_a349_ForceLampToRed "Electronic stability control: a349 force lamp to red";
CM_ SG_ 981 ESP_a350_ActuatorOff "Electronic stability control: a350 actuator off";
CM_ SG_ 981 ESP_a351_ActuatorYellowLampReque "Electronic stability control: a351 actuator yellow lamp requested";
CM_ SG_ 981 ESP_a352_ActuatorLDMFailure "Electronic stability control: a352 actuator LDM failure";
CM_ SG_ 981 ESP_a353_PressureSensorImplausHi "Electronic stability control: a353 pressure sensor implaus high";
CM_ SG_ 981 ESP_a354_HBCRequestInvalid "Electronic stability control: a354 HBC request invalid";
CM_ SG_ 981 ESP_a355_RecuStatusActInvalid "Electronic stability control: a355 recu status act invalid";
CM_ SG_ 981 ESP_a356_DIFAxleTorqueInvalid "Electronic stability control: a356 DIF axle torque invalid";
CM_ SG_ 981 ESP_a357_DIRAxleTorqueInvalid "Electronic stability control: a357 DIR axle torque invalid";
CM_ SG_ 981 ESP_a358_externalActuatorFallbac "Electronic stability control: a358 external actuator fallback";
CM_ SG_ 981 ESP_a359_externalActuatorNoExtRe "Electronic stability control: a359 external actuator no ext req";
CM_ SG_ 981 ESP_a360_BBbrakeActuationTimeout "Electronic stability control: a360 b bbrake actuation timeout";
CM_ SG_ 981 ESP_a361_BBbrakeActuationDLC "Electronic stability control: a361 b bbrake actuation DLC";
CM_ SG_ 981 ESP_a362_BBbrakeActuationChecksu "Electronic stability control: a362 b bbrake actuation checksum";
CM_ SG_ 981 ESP_a363_BBbrakeActuationCounter "Electronic stability control: a363 b bbrake actuation counter";
CM_ SG_ 981 ESP_a364_DIgearInvalid "Electronic stability control: a364 d igear invalid";
CM_ SG_ 981 ESP_a365_TCSInputQualityTooLow "Electronic stability control: a365 TCS input quality too low";
CM_ SG_ 981 ESP_a366_ActuatorBlendingModeReq "Electronic stability control: a366 actuator blending mode req not available";
CM_ SG_ 981 ESP_a367_CBDS_fillBufferThreshol "Electronic stability control: a367 CBDS fill buffer threshold";
CM_ SG_ 981 ESP_a368_CBDS_fmeInternalEvent "Electronic stability control: a368 CBDS fme internal event";
CM_ SG_ 981 ESP_a369_LargeLeakageDetectedByD "Electronic stability control: a369 large leakage detected by DPB";
CM_ SG_ 981 ESP_a370_DPB_actuator4Timeout "Electronic stability control: a370 DPB actuator4 timeout";
CM_ SG_ 981 ESP_a371_DPB_actuator4DLC "Electronic stability control: a371 DPB actuator4 DLC";
CM_ SG_ 981 ESP_a372_DPB_actuator4Checksum "Electronic stability control: a372 DPB actuator4 checksum";
CM_ SG_ 981 ESP_a373_DPB_actuator4Counter "Electronic stability control: a373 DPB actuator4 counter";
CM_ SG_ 981 ESP_a374_StatInvalid_DI_FullSNA "Electronic stability control: a374 stat invalid DI full SNA";
CM_ SG_ 981 ESP_a375_PM_locStateCounter "Electronic stability control: a375 PM loc state counter";
CM_ SG_ 981 ESP_a376_PM_locStateChecksum "Electronic stability control: a376 PM loc state checksum";
CM_ SG_ 981 ESP_a377_PM_locStateDLC "Electronic stability control: a377 PM loc state DLC";
CM_ SG_ 981 ESP_a378_PM_locStateTimeout "Electronic stability control: a378 PM loc state timeout";
CM_ BO_ 1621 "Electronic stability control message: uds response";
CM_ SG_ 1621 ESP_udsResponseData "Electronic stability control: uds response data";
CM_ BO_ 373 "Electronic stability control message: wheel speeds";
CM_ SG_ 373 ESP_wheelSpeedFrL "Electronic stability control: wheel speed fr l";
CM_ SG_ 373 ESP_wheelSpeedFrR "Electronic stability control: wheel speed fr r";
CM_ SG_ 373 ESP_wheelSpeedReL "Electronic stability control: wheel speed re l";
CM_ SG_ 373 ESP_wheelSpeedReR "Electronic stability control: wheel speed re r";
CM_ BO_ 888 "Gateway message: e call";
CM_ SG_ 888 GTW_GTW_SOS_ECALL_RQST "State of the GTW-SOS-ECALL-RQST pin";
CM_ SG_ 888 GTW_LTE_ECALL_LOCK "State of the LTE-ECALL-LOCK pin";
CM_ BO_ 282 "Gateway message: adc4";
CM_ SG_ 282 GTW_BKP_BATT_MON "Gateway: BKP BATT MON; raw 4095 = signal not available (SNA)";
CM_ SG_ 282 GTW_BKP_BATT_NTC_P "BKP_BATT_NTC_P pni voltage; raw 4095 = signal not available (SNA)";
CM_ SG_ 282 GTW_ECALL_GPS_ANT_BIAS "Gateway: ECALL GPS ANT BIAS; raw 4095 = signal not available (SNA)";
CM_ SG_ 282 GTW_ECALL_MIC_DIAG "ECALL_MIC_DIAG voltage; raw 4095 = signal not available (SNA)";
CM_ SG_ 282 GTW_SOS_ECALL_nRQST_BUF "SOS_ECALL_nRQST_BUF voltage; raw 4095 = signal not available (SNA)";
CM_ BO_ 1384 "Gateway message: alert log";
CM_ SG_ 1384 GTW_alertID "Gateway: alert ID";
CM_ SG_ 1384 GTW_alertState "Gateway: alert state";
CM_ SG_ 1384 GTW_a014_crcVersion "Gateway: a014 crc version";
CM_ SG_ 1384 GTW_a015_crcVersion "Gateway: a015 crc version";
CM_ SG_ 1384 GTW_a016_crcVersion "Gateway: a016 crc version";
CM_ SG_ 1384 GTW_a017_crcVersion "Gateway: a017 crc version";
CM_ SG_ 1384 GTW_a018_crcVersion "Gateway: a018 crc version";
CM_ SG_ 1384 GTW_a019_crcVersion "Gateway: a019 crc version";
CM_ SG_ 1384 GTW_a020_crcVersion "Gateway: a020 crc version";
CM_ SG_ 1384 GTW_a021_crcVersion "Gateway: a021 crc version";
CM_ SG_ 1384 GTW_a022_crcVersion "Gateway: a022 crc version";
CM_ SG_ 1384 GTW_a023_crcVersion "Gateway: a023 crc version";
CM_ SG_ 1384 GTW_a024_crcVersion "Gateway: a024 crc version";
CM_ SG_ 1384 GTW_a025_crcVersion "Gateway: a025 crc version";
CM_ SG_ 1384 GTW_a026_crcVersion "Gateway: a026 crc version";
CM_ SG_ 1384 GTW_a027_crcVersion "Gateway: a027 crc version";
CM_ SG_ 1384 GTW_a028_crcVersion "Gateway: a028 crc version";
CM_ SG_ 1384 GTW_a029_crcVersion "Gateway: a029 crc version";
CM_ SG_ 1384 GTW_a030_crcVersion "Gateway: a030 crc version";
CM_ SG_ 1384 GTW_a031_crcVersion "Gateway: a031 crc version";
CM_ SG_ 1384 GTW_a032_crcVersion "Gateway: a032 crc version";
CM_ SG_ 1384 GTW_a033_crcVersion "Gateway: a033 crc version";
CM_ SG_ 1384 GTW_a034_crcVersion "Gateway: a034 crc version";
CM_ SG_ 1384 GTW_a035_crcVersion "Gateway: a035 crc version";
CM_ SG_ 1384 GTW_a036_crcVersion "Gateway: a036 crc version";
CM_ SG_ 1384 GTW_a037_crcVersion "Gateway: a037 crc version";
CM_ SG_ 1384 GTW_a038_crcVersion "Gateway: a038 crc version";
CM_ SG_ 1384 GTW_a039_crcVersion "Gateway: a039 crc version";
CM_ SG_ 1384 GTW_a040_crcVersion "Gateway: a040 crc version";
CM_ SG_ 1384 GTW_a041_crcVersion "Gateway: a041 crc version";
CM_ SG_ 1384 GTW_a042_crcVersion "Gateway: a042 crc version";
CM_ SG_ 1384 GTW_a043_crcVersion "Gateway: a043 crc version";
CM_ SG_ 1384 GTW_a045_crcVersion "Gateway: a045 crc version";
CM_ SG_ 1384 GTW_a046_crcVersion "Gateway: a046 crc version";
CM_ SG_ 1384 GTW_a047_crcVersion "Gateway: a047 crc version";
CM_ SG_ 1384 GTW_a048_crcVersion "Gateway: a048 crc version";
CM_ SG_ 1384 GTW_a049_headerError "Gateway: a049 header error";
CM_ SG_ 1384 GTW_a054_crcVersion "Gateway: a054 crc version";
CM_ SG_ 1384 GTW_a055_crcVersion "Gateway: a055 crc version";
CM_ SG_ 1384 GTW_a062_bmpWatchdogReason "Gateway: a062 bmp watchdog reason";
CM_ SG_ 1384 GTW_a063_VEH_faultConfinement "Gateway: a063 VEH fault confinement";
CM_ SG_ 1384 GTW_a064_CH_faultConfinement "Gateway: a064 CH fault confinement";
CM_ SG_ 1384 GTW_a065_PARTY_faultConfinement "Gateway: a065 PARTY fault confinement";
CM_ SG_ 1384 GTW_a066_type "Gateway: a066 type";
CM_ SG_ 1384 GTW_a066_exceptionCfgId "Gateway: a066 exception cfg id";
CM_ SG_ 1384 GTW_a066_uptime "Gateway: a066 uptime";
CM_ SG_ 1384 GTW_a068_codeKeyMissing "Gateway: a068 code key missing";
CM_ SG_ 1384 GTW_a068_cmdKeyMissing "Gateway: a068 cmd key missing";
CM_ SG_ 1384 GTW_a069_sdIntStatusErrs "Gateway: a069 sd int status errs";
CM_ SG_ 1384 GTW_a069_sdTimeout "Gateway: a069 sd timeout";
CM_ SG_ 1384 GTW_a069_sdCmdErr "Gateway: a069 sd cmd err";
CM_ SG_ 1384 GTW_a069_sdWriteErr "Gateway: a069 sd write err";
CM_ SG_ 1384 GTW_a069_sdReadErr "Gateway: a069 sd read err";
CM_ SG_ 1384 GTW_a069_autoCmd12Err "Gateway: a069 auto cmd12 err";
CM_ SG_ 1384 GTW_a072_updtFailureMask "Gateway: a072 updt failure mask";
CM_ SG_ 1384 GTW_a077_bmpPmicErrorType "Gateway: a077 bmp pmic error type";
CM_ SG_ 1384 GTW_a078_loadPercent "Gateway: a078 load percent";
CM_ SG_ 1384 GTW_a079_loadPercent "Gateway: a079 load percent";
CM_ SG_ 1384 GTW_a080_loadPercent "Gateway: a080 load percent";
CM_ SG_ 1384 GTW_a081_canId "Gateway: a081 can id";
CM_ SG_ 1384 GTW_a081_ISOTPmsgType "Gateway: a081 ISOT pmsg type";
CM_ SG_ 1384 GTW_a081_udsSID "Gateway: a081 uds SID";
CM_ SG_ 1384 GTW_a097_crcVersion "Gateway: a097 crc version";
CM_ SG_ 1384 GTW_a098_crcVersion "Gateway: a098 crc version";
CM_ SG_ 1384 GTW_a099_crcVersion "Gateway: a099 crc version";
CM_ SG_ 1384 GTW_a100_crcVersion "Gateway: a100 crc version";
CM_ SG_ 1384 GTW_a101_switchStuck "Gateway: a101 switch stuck";
CM_ SG_ 1384 GTW_a101_ETH_SW_nINT "Gateway: a101 ETH SW n INT";
CM_ SG_ 1384 GTW_a106_crcVersion "Gateway: a106 crc version";
CM_ SG_ 1384 GTW_a107_crcVersion "Gateway: a107 crc version";
CM_ SG_ 1384 GTW_a108_crcVersion "Gateway: a108 crc version";
CM_ SG_ 1384 GTW_a113_bus "Gateway: a113 bus";
CM_ SG_ 1384 GTW_a113_id "Gateway: a113 id";
CM_ SG_ 1384 GTW_a117_MC_RGM_DES "Gateway: a117 MC RGM DES";
CM_ SG_ 1384 GTW_a118_MC_RGM_FES "Gateway: a118 MC RGM FES";
CM_ SG_ 1384 GTW_a122_BDY_faultConfinement "Gateway: a122 BDY fault confinement";
CM_ SG_ 1384 GTW_a129_crcVersion "Gateway: a129 crc version";
CM_ SG_ 1384 GTW_a138_sdLifetimeUsed "Gateway: a138 sd lifetime used";
CM_ SG_ 1384 GTW_a139_crcVersion "Gateway: a139 crc version";
CM_ SG_ 1384 GTW_a150_crcVersion "Gateway: a150 crc version";
CM_ SG_ 1384 GTW_a151_crcVersion "Gateway: a151 crc version";
CM_ SG_ 1384 GTW_a155_crcVersion "Gateway: a155 crc version";
CM_ SG_ 1384 GTW_a165_crcVersion "Gateway: a165 crc version";
CM_ SG_ 1384 GTW_a169_TPMS_pressureFL "Gateway: a169 TPMS pressure FL";
CM_ SG_ 1384 GTW_a170_TPMS_pressureFR "Gateway: a170 TPMS pressure FR";
CM_ SG_ 1384 GTW_a171_TPMS_pressureRL "Gateway: a171 TPMS pressure RL";
CM_ SG_ 1384 GTW_a172_TPMS_pressureRR "Gateway: a172 TPMS pressure RR";
CM_ SG_ 1384 GTW_a173_TPMS_pressureFL "Gateway: a173 TPMS pressure FL";
CM_ SG_ 1384 GTW_a174_TPMS_pressureFR "Gateway: a174 TPMS pressure FR";
CM_ SG_ 1384 GTW_a175_TPMS_pressureRL "Gateway: a175 TPMS pressure RL";
CM_ SG_ 1384 GTW_a176_TPMS_pressureRR "Gateway: a176 TPMS pressure RR";
CM_ SG_ 1384 GTW_a219_crcVersion "Gateway: a219 crc version";
CM_ SG_ 1384 GTW_a223_crcVersion "Gateway: a223 crc version";
CM_ SG_ 1384 GTW_a226_crcVersion "Gateway: a226 crc version";
CM_ SG_ 1384 GTW_a227_crcVersion "Gateway: a227 crc version";
CM_ SG_ 1384 GTW_a228_crcVersion "Gateway: a228 crc version";
CM_ SG_ 1384 GTW_a244_crcVersion "Gateway: a244 crc version";
CM_ SG_ 1384 GTW_a245_page0ControlValue "Gateway: a245 page0 control value";
CM_ SG_ 1384 GTW_a245_page1ControlValue "Gateway: a245 page1 control value";
CM_ SG_ 1384 GTW_a261_failureReason "Gateway: a261 failure reason";
CM_ SG_ 1384 GTW_a261_failureData1 "Gateway: a261 failure data1";
CM_ SG_ 1384 GTW_a261_failureData2 "Gateway: a261 failure data2";
CM_ SG_ 1384 GTW_a273_crcVersion "Gateway: a273 crc version";
CM_ SG_ 1384 GTW_a274_crcVersion "Gateway: a274 crc version";
CM_ SG_ 1384 GTW_a277_mitigationFailureReason "Gateway: a277 mitigation failure reason";
CM_ SG_ 1384 GTW_a279_repeatCount "Gateway: a279 repeat count";
CM_ SG_ 1384 GTW_a279_failureReason "Gateway: a279 failure reason";
CM_ SG_ 1384 GTW_a279_failureData1 "Gateway: a279 failure data1";
CM_ SG_ 1384 GTW_a279_failureData2 "Gateway: a279 failure data2";
CM_ SG_ 1384 GTW_a309_crcVersion "Gateway: a309 crc version";
CM_ SG_ 1384 GTW_a317_status "Gateway: a317 status";
CM_ SG_ 1384 GTW_a317_errorCode "Gateway: a317 error code";
CM_ SG_ 1384 GTW_a329_crcVersion "Gateway: a329 crc version";
CM_ SG_ 1384 GTW_a330_crcVersion "Gateway: a330 crc version";
CM_ SG_ 1384 GTW_a331_crcVersion "Gateway: a331 crc version";
CM_ SG_ 1384 GTW_a342_crcVersion "Gateway: a342 crc version";
CM_ SG_ 1384 GTW_a348_crcVersion "Gateway: a348 crc version";
CM_ SG_ 1384 GTW_a349_crcVersion "Gateway: a349 crc version";
CM_ SG_ 1384 GTW_a354_crcVersion "Gateway: a354 crc version";
CM_ SG_ 1384 GTW_a355_crcVersion "Gateway: a355 crc version";
CM_ SG_ 1384 GTW_a358_crcVersion "Gateway: a358 crc version";
CM_ SG_ 1384 GTW_a359_crcVersion "Gateway: a359 crc version";
CM_ SG_ 1384 GTW_a360_crcVersion "Gateway: a360 crc version";
CM_ SG_ 1384 GTW_a361_crcVersion "Gateway: a361 crc version";
CM_ SG_ 1384 GTW_a362_crcVersion "Gateway: a362 crc version";
CM_ SG_ 1384 GTW_a363_crcVersion "Gateway: a363 crc version";
CM_ SG_ 1384 GTW_a364_crcVersion "Gateway: a364 crc version";
CM_ SG_ 1384 GTW_a380_crcVersion "Gateway: a380 crc version";
CM_ SG_ 1384 GTW_a381_crcVersion "Gateway: a381 crc version";
CM_ SG_ 1384 GTW_a382_crcVersion "Gateway: a382 crc version";
CM_ SG_ 1384 GTW_a383_crcVersion "Gateway: a383 crc version";
CM_ SG_ 1384 GTW_a384_crcVersion "Gateway: a384 crc version";
CM_ SG_ 1384 GTW_a385_crcVersion "Gateway: a385 crc version";
CM_ SG_ 1384 GTW_a386_crcVersion "Gateway: a386 crc version";
CM_ SG_ 1384 GTW_a409_RES_CAUSE "Gateway: a409 RES CAUSE";
CM_ SG_ 1384 GTW_a410_RES_CAUSE2 "Gateway: a410 RES CAUSE2";
CM_ BO_ 62 "Gateway message: alert matrix";
CM_ SG_ 62 GTW_matrixIndex "Gateway: matrix index";
CM_ SG_ 62 GTW_w001_canEthTxQueue "Gateway: w001 can eth tx queue";
CM_ SG_ 62 GTW_w002_taskError "Gateway: w002 task error";
CM_ SG_ 62 GTW_w003_logWriteRecord "Gateway: w003 log write record";
CM_ SG_ 62 GTW_w004_mallocHook "Gateway: w004 malloc hook";
CM_ SG_ 62 GTW_w005_stackOverflowHook "Gateway: w005 stack overflow hook";
CM_ SG_ 62 GTW_w006_ifTxOutputFull "Gateway: w006 if tx output full";
CM_ SG_ 62 GTW_w007_ifRxBufError "Gateway: w007 if rx buf error";
CM_ SG_ 62 GTW_w008_ifPbufAllocError "Gateway: w008 if pbuf alloc error";
CM_ SG_ 62 GTW_w009_lateTask "Gateway: w009 late task";
CM_ SG_ 62 GTW_w010_wdTaskCount "Gateway: w010 wd task count";
CM_ SG_ 62 GTW_w011_cancoreWatchdog "Gateway: w011 cancore watchdog";
CM_ SG_ 62 GTW_w012_maincoreWatchdog "Gateway: w012 maincore watchdog";
CM_ SG_ 62 GTW_w014_APSversionMismatch "Gateway: w014 AP sversion mismatch";
CM_ SG_ 62 GTW_w015_DIFversionMismatch "Gateway: w015 DI fversion mismatch";
CM_ SG_ 62 GTW_w016_BLEEPCENTERversionMisma "Gateway: w016 BLEEPCENTE rversion mismatch";
CM_ SG_ 62 GTW_w017_BMSversionMismatch "Gateway: w017 BM sversion mismatch";
CM_ SG_ 62 GTW_w018_CMPversionMismatch "Gateway: w018 CM pversion mismatch";
CM_ SG_ 62 GTW_w019_CPversionMismatch "Gateway: w019 c pversion mismatch";
CM_ SG_ 62 GTW_w020_DIRversionMismatch "Gateway: w020 DI rversion mismatch";
CM_ SG_ 62 GTW_w021_EPAS3PversionMismatch "Gateway: w021 EPAS3 pversion mismatch";
CM_ SG_ 62 GTW_w022_EPBLversionMismatch "Gateway: w022 EPB lversion mismatch";
CM_ SG_ 62 GTW_w023_EPBRversionMismatch "Gateway: w023 EPB rversion mismatch";
CM_ SG_ 62 GTW_w024_ESPversionMismatch "Gateway: w024 ES pversion mismatch";
CM_ SG_ 62 GTW_w025_ESPCALversionMismatch "Gateway: w025 ESPCA lversion mismatch";
CM_ SG_ 62 GTW_w026_GTWversionMismatch "Gateway: w026 GT wversion mismatch";
CM_ SG_ 62 GTW_w027_HVPversionMismatch "Gateway: w027 HV pversion mismatch";
CM_ SG_ 62 GTW_w028_IBSTversionMismatch "Gateway: w028 IBS tversion mismatch";
CM_ SG_ 62 GTW_w029_IBSTCALversionMismatch "Gateway: w029 IBSTCA lversion mismatch";
CM_ SG_ 62 GTW_w030_OCS1PversionMismatch "Gateway: w030 OCS1 pversion mismatch";
CM_ SG_ 62 GTW_w031_PARKversionMismatch "Gateway: w031 PAR kversion mismatch";
CM_ SG_ 62 GTW_w032_PCSversionMismatch "Gateway: w032 PC sversion mismatch";
CM_ SG_ 62 GTW_w033_PCSCPU2versionMismatch "Gateway: w033 pcscpu2version mismatch";
CM_ SG_ 62 GTW_w034_PMRversionMismatch "Gateway: w034 PM rversion mismatch";
CM_ SG_ 62 GTW_w035_PMFversionMismatch "Gateway: w035 PM fversion mismatch";
CM_ SG_ 62 GTW_w036_PTCversionMismatch "Gateway: w036 PT cversion mismatch";
CM_ SG_ 62 GTW_w037_RADCversionMismatch "Gateway: w037 RAD cversion mismatch";
CM_ SG_ 62 GTW_w038_RCMversionMismatch "Gateway: w038 RC mversion mismatch";
CM_ SG_ 62 GTW_w039_RCMCALversionMismatch "Gateway: w039 RCMCA lversion mismatch";
CM_ SG_ 62 GTW_w040_SCCMversionMismatch "Gateway: w040 SCC mversion mismatch";
CM_ SG_ 62 GTW_w041_VCSECversionMismatch "Gateway: w041 VCSE cversion mismatch";
CM_ SG_ 62 GTW_w042_TASversionMismatch "Gateway: w042 TA sversion mismatch";
CM_ SG_ 62 GTW_w043_THSversionMismatch "Gateway: w043 TH sversion mismatch";
CM_ SG_ 62 GTW_w045_VCFRONTversionMismatch "Gateway: w045 VCFRON tversion mismatch";
CM_ SG_ 62 GTW_w046_VCLEFTversionMismatch "Gateway: w046 VCLEF tversion mismatch";
CM_ SG_ 62 GTW_w047_VCRIGHTversionMismatch "Gateway: w047 VCRIGH tversion mismatch";
CM_ SG_ 62 GTW_w048_EPAS3SversionMismatch "Gateway: w048 EPAS3 sversion mismatch";
CM_ SG_ 62 GTW_w049_corruptedManifest "Gateway: w049 corrupted manifest";
CM_ SG_ 62 GTW_w050_sdCardInitFailure "Gateway: w050 sd card init failure";
CM_ SG_ 62 GTW_w051_sdCardFileSystemFailure "Gateway: w051 sd card file system failure";
CM_ SG_ 62 GTW_w052_ifTxSpans "Gateway: w052 if tx spans";
CM_ SG_ 62 GTW_w053_busSleepFailure "Gateway: w053 bus sleep failure";
CM_ SG_ 62 GTW_w054_OPCRversionMismatch "Gateway: w054 OPC rversion mismatch";
CM_ SG_ 62 GTW_w055_OPCFversionMismatch "Gateway: w055 OPC fversion mismatch";
CM_ SG_ 62 GTW_w057_i2cFailure "Gateway: w057 i2c failure";
CM_ SG_ 62 GTW_w058_rtcAlarmFailure "Gateway: w058 rtc alarm failure";
CM_ SG_ 62 GTW_w059_inFactoryMode "Gateway: w059 in factory mode";
CM_ SG_ 62 GTW_w060_unFused "Gateway: w060 un fused";
CM_ SG_ 62 GTW_w061_bmpSleepFailure "Gateway: w061 bmp sleep failure";
CM_ SG_ 62 GTW_w062_bmpWatchdog "Gateway: w062 bmp watchdog";
CM_ SG_ 62 GTW_w063_VEH_canFault "Gateway: w063 VEH can fault";
CM_ SG_ 62 GTW_w064_CH_canFault "Gateway: w064 CH can fault";
CM_ SG_ 62 GTW_w065_PARTY_canFault "Gateway: w065 PARTY can fault";
CM_ SG_ 62 GTW_w066_exception "Gateway: w066 exception";
CM_ SG_ 62 GTW_w067_tcpDebug "Gateway: w067 tcp debug";
CM_ SG_ 62 GTW_w068_prodKeyMissing "Gateway: w068 prod key missing";
CM_ SG_ 62 GTW_w069_diskioErr "Gateway: w069 diskio err";
CM_ SG_ 62 GTW_w070_hrlDump "Gateway: w070 hrl dump";
CM_ SG_ 62 GTW_w071_hrlTrigger "Gateway: w071 hrl trigger";
CM_ SG_ 62 GTW_w072_updateFailure "Gateway: w072 update failure";
CM_ SG_ 62 GTW_w073_steeringWheelReset "Gateway: w073 steering wheel reset";
CM_ SG_ 62 GTW_w074_epas3pMIA "Gateway: w074 epas3p MIA";
CM_ SG_ 62 GTW_w075_epas3sMIA "Gateway: w075 epas3s MIA";
CM_ SG_ 62 GTW_w076_ethInterfaceReset "Gateway: w076 eth interface reset";
CM_ SG_ 62 GTW_w077_bmpPmicError "Gateway: w077 bmp pmic error";
CM_ SG_ 62 GTW_w078_VEHbusOverloaded "Gateway: w078 VE hbus overloaded";
CM_ SG_ 62 GTW_w079_PARTYbusOverloaded "Gateway: w079 PART ybus overloaded";
CM_ SG_ 62 GTW_w080_CHbusOverloaded "Gateway: w080 c hbus overloaded";
CM_ SG_ 62 GTW_w081_udsMessageRejected "Gateway: w081 uds message rejected";
CM_ SG_ 62 GTW_w082_sdCardBSCorrupted "Gateway: w082 sd card BS corrupted";
CM_ SG_ 62 GTW_w083_udsMsgDroppedByTcpStack "Gateway: w083 uds msg dropped by tcp stack";
CM_ SG_ 62 GTW_w084_canFrameDropped "Gateway: w084 can frame dropped";
CM_ SG_ 62 GTW_w086_ocu "Gateway: w086 ocu";
CM_ SG_ 62 GTW_w087_ocuInProgress "Gateway: w087 ocu in progress";
CM_ SG_ 62 GTW_w088_sdCardInvReqParallel "Gateway: w088 sd card inv req parallel";
CM_ SG_ 62 GTW_w089_sdCardWatchdog "Gateway: w089 sd card watchdog";
CM_ SG_ 62 GTW_w090_ocuFailed "Gateway: w090 ocu failed";
CM_ SG_ 62 GTW_w091_lowStack "Gateway: w091 low stack";
CM_ SG_ 62 GTW_w092_sdCardInvReqZero "Gateway: w092 sd card inv req zero";
CM_ SG_ 62 GTW_w093_sdCardInvReqOverflowBas "Gateway: w093 sd card inv req overflow base";
CM_ SG_ 62 GTW_w094_sdCardInvReqOverflowCou "Gateway: w094 sd card inv req overflow count";
CM_ SG_ 62 GTW_w095_sdCardFull "Gateway: w095 sd card full";
CM_ SG_ 62 GTW_w096_sdCardFatCorrupted "Gateway: w096 sd card fat corrupted";
CM_ SG_ 62 GTW_w097_HCMLversionMismatch "Gateway: w097 HCM lversion mismatch";
CM_ SG_ 62 GTW_w098_HCMRversionMismatch "Gateway: w098 HCM rversion mismatch";
CM_ SG_ 62 GTW_w099_SWCversionMismatch "Gateway: w099 SW cversion mismatch";
CM_ SG_ 62 GTW_w100_CBCversionMismatch "Gateway: w100 CB cversion mismatch";
CM_ SG_ 62 GTW_w101_switchWatchdog "Gateway: w101 switch watchdog";
CM_ SG_ 62 GTW_w103_sdCardFormatted "Gateway: w103 sd card formatted";
CM_ SG_ 62 GTW_w104_sdCardDriverArgCorrupte "Gateway: w104 sd card driver arg corrupted";
CM_ SG_ 62 GTW_w105_eBuckConfigured "Gateway: w105 e buck configured";
CM_ SG_ 62 GTW_w106_BLEEPLEFTversionMismatc "Gateway: w106 BLEEPLEF tversion mismatch";
CM_ SG_ 62 GTW_w107_BLEEPRIGHTversionMismat "Gateway: w107 BLEEPRIGH tversion mismatch";
CM_ SG_ 62 GTW_w108_BLEEPREARversionMismatc "Gateway: w108 BLEEPREA rversion mismatch";
CM_ SG_ 62 GTW_w109_failedToStartUpdater "Gateway: w109 failed to start updater";
CM_ SG_ 62 GTW_w110_readMdioFailed "Gateway: w110 read mdio failed";
CM_ SG_ 62 GTW_w111_writeMdioFailed "Gateway: w111 write mdio failed";
CM_ SG_ 62 GTW_w112_z4bDisabled "Gateway: w112 z4b disabled";
CM_ SG_ 62 GTW_w113_unrecognizedCanMessage "Gateway: w113 unrecognized can message";
CM_ SG_ 62 GTW_w114_updtRetried "Gateway: w114 updt retried";
CM_ SG_ 62 GTW_w115_hrlEventFileAvail "Gateway: w115 hrl event file avail";
CM_ SG_ 62 GTW_w116_switchInitFailed "Gateway: w116 switch init failed";
CM_ SG_ 62 GTW_w117_unexpectedDestructiveRe "Gateway: w117 unexpected destructive reset status";
CM_ SG_ 62 GTW_w118_unexpectedFunctionalRes "Gateway: w118 unexpected functional reset status";
CM_ SG_ 62 GTW_w120_switchUnlocked "Gateway: w120 switch unlocked";
CM_ SG_ 62 GTW_w122_BDY_canFault "Gateway: w122 BDY can fault";
CM_ SG_ 62 GTW_w123_BDYbusOverloaded "Gateway: w123 BD ybus overloaded";
CM_ SG_ 62 GTW_w125_switchReplayUnlocked "Gateway: w125 switch replay unlocked";
CM_ SG_ 62 GTW_w127_noFilePointersAvailable "Gateway: w127 no file pointers available";
CM_ SG_ 62 GTW_w129_ICRversionMismatch "Gateway: w129 IC rversion mismatch";
CM_ SG_ 62 GTW_w133_adspFaultDetected "Gateway: w133 adsp fault detected";
CM_ SG_ 62 GTW_w134_disableFeatureFailed "Gateway: w134 disable feature failed";
CM_ SG_ 62 GTW_w135_canLogQueueFull "Gateway: w135 can log queue full";
CM_ SG_ 62 GTW_w136_hrlGameModeFileAvail "Gateway: w136 hrl game mode file avail";
CM_ SG_ 62 GTW_w137_lowHeap "Gateway: w137 low heap";
CM_ SG_ 62 GTW_w138_sdCardEndOfLife "Gateway: w138 sd card end of life";
CM_ SG_ 62 GTW_w139_CMPDversionMismatch "Gateway: w139 CMP dversion mismatch";
CM_ SG_ 62 GTW_w140_cancoreHeartbeat "Gateway: w140 cancore heartbeat";
CM_ SG_ 62 GTW_w141_teleCANETHis "Gateway: w141 tele CANET his";
CM_ SG_ 62 GTW_w143_possibleCanWakeIssue "Gateway: w143 possible can wake issue";
CM_ SG_ 62 GTW_w144_hrlStateMachine "Gateway: w144 hrl state machine";
CM_ SG_ 62 GTW_w145_carConfigsNotWritten "Gateway: w145 car configs not written";
CM_ SG_ 62 GTW_w146_performancePackageMisma "Gateway: w146 performance package mismatch";
CM_ SG_ 62 GTW_w147_updateAbortFor12v "Gateway: w147 update abort for12v";
CM_ SG_ 62 GTW_w149_rtcTimeSetInPast "Gateway: w149 rtc time set in past";
CM_ SG_ 62 GTW_w150_HCM3LversionMismatch "Gateway: w150 HCM3 lversion mismatch";
CM_ SG_ 62 GTW_w151_HCM3RversionMismatch "Gateway: w151 HCM3 rversion mismatch";
CM_ SG_ 62 GTW_w153_externalRtcAlarmFailure "Gateway: w153 external rtc alarm failure";
CM_ SG_ 62 GTW_w155_PMversionMismatch "Gateway: w155 p mversion mismatch";
CM_ SG_ 62 GTW_w165_USMversionMismatch "Gateway: w165 US mversion mismatch";
CM_ SG_ 62 GTW_w166_nErrCanFaultVeh "Gateway: w166 n err can fault veh";
CM_ SG_ 62 GTW_w167_nErrCanFaultCh "Gateway: w167 n err can fault ch";
CM_ SG_ 62 GTW_w168_nErrCanFaultParty "Gateway: w168 n err can fault party";
CM_ SG_ 62 GTW_w169_TPMSsoftWarnFrontLeft "Gateway: w169 TPM ssoft warn front left";
CM_ SG_ 62 GTW_w170_TPMSsoftWarnFrontRight "Gateway: w170 TPM ssoft warn front right";
CM_ SG_ 62 GTW_w171_TPMSsoftWarnRearLeft "Gateway: w171 TPM ssoft warn rear left";
CM_ SG_ 62 GTW_w172_TPMSsoftWarnRearRight "Gateway: w172 TPM ssoft warn rear right";
CM_ SG_ 62 GTW_w173_TPMShardWarnFrontLeft "Gateway: w173 TPM shard warn front left";
CM_ SG_ 62 GTW_w174_TPMShardWarnFrontRight "Gateway: w174 TPM shard warn front right";
CM_ SG_ 62 GTW_w175_TPMShardWarnRearLeft "Gateway: w175 TPM shard warn rear left";
CM_ SG_ 62 GTW_w176_TPMShardWarnRearRight "Gateway: w176 TPM shard warn rear right";
CM_ SG_ 62 GTW_w186_swrPrecaution "Gateway: w186 swr precaution";
CM_ SG_ 62 GTW_w218_switchOTPIncorrect "Gateway: w218 switch OTP incorrect";
CM_ SG_ 62 GTW_w219_CMPSversionMismatch "Gateway: w219 CMP sversion mismatch";
CM_ SG_ 62 GTW_w223_LVBMSversionMismatch "Gateway: w223 LVBM sversion mismatch";
CM_ SG_ 62 GTW_w224_sdCardUpgradeNeeded "Gateway: w224 sd card upgrade needed";
CM_ SG_ 62 GTW_w225_resetOnSleepWake "Gateway: w225 reset on sleep wake";
CM_ SG_ 62 GTW_w226_DISPversionMismatch "Gateway: w226 DIS pversion mismatch";
CM_ SG_ 62 GTW_w227_DISPTOUCHversionMismatc "Gateway: w227 DISPTOUC hversion mismatch";
CM_ SG_ 62 GTW_w228_DISPOSDversionMismatch "Gateway: w228 DISPOS dversion mismatch";
CM_ SG_ 62 GTW_w229_displaySoftsetConnectio "Gateway: w229 display softset connection";
CM_ SG_ 62 GTW_w230_touchInterruptStorm "Gateway: w230 touch interrupt storm";
CM_ SG_ 62 GTW_w244_SDCRversionMismatch "Gateway: w244 SDC rversion mismatch";
CM_ SG_ 62 GTW_w245_apsNotDisabled "Gateway: w245 aps not disabled";
CM_ SG_ 62 GTW_w246_touchcoreHeartbeat "Gateway: w246 touchcore heartbeat";
CM_ SG_ 62 GTW_w255_rtc32KHzWatchdog "Gateway: w255 rtc32 k hz watchdog";
CM_ SG_ 62 GTW_w260_unknownPN "Gateway: w260 unknown PN";
CM_ SG_ 62 GTW_w261_adspWatchdog "Gateway: w261 adsp watchdog";
CM_ SG_ 62 GTW_w262_canLogBlockDropped "Gateway: w262 can log block dropped";
CM_ SG_ 62 GTW_w263_hrlUdpFileAvail "Gateway: w263 hrl udp file avail";
CM_ SG_ 62 GTW_w264_hrlPseudoFileAvail "Gateway: w264 hrl pseudo file avail";
CM_ SG_ 62 GTW_w265_optionFlagsError "Gateway: w265 option flags error";
CM_ SG_ 62 GTW_w266_dpp1MIA "Gateway: w266 dpp1 MIA";
CM_ SG_ 62 GTW_w267_dpp2MIA "Gateway: w267 dpp2 MIA";
CM_ SG_ 62 GTW_w268_stoMIA "Gateway: w268 sto MIA";
CM_ SG_ 62 GTW_w273_BLEEPREARLEFTversionMis "Gateway: w273 BLEEPREARLEF tversion mismatch";
CM_ SG_ 62 GTW_w274_BLEEPREARRIGHTversionMi "Gateway: w274 BLEEPREARRIGH tversion mismatch";
CM_ SG_ 62 GTW_w275_VDDCORE_DrMOS_Fault "Gateway: w275 VDDCORE dr MOS fault";
CM_ SG_ 62 GTW_w276_VDDSOC_DrMOS_Fault "Gateway: w276 VDDSOC dr MOS fault";
CM_ SG_ 62 GTW_w277_NonRevCDrMOSMitigationF "Gateway: w277 non rev c dr MOS mitigation failed";
CM_ SG_ 62 GTW_w278_ethSwitchCongested "Gateway: w278 eth switch congested";
CM_ SG_ 62 GTW_w279_adspRepeatedWatchdog "Gateway: w279 adsp repeated watchdog";
CM_ SG_ 62 GTW_w280_hrlFrameDropped "Gateway: w280 hrl frame dropped";
CM_ SG_ 62 GTW_w281_likelyMissedPoke "Gateway: w281 likely missed poke";
CM_ SG_ 62 GTW_w282_tcuPhyConfigurationFail "Gateway: w282 tcu phy configuration failed";
CM_ SG_ 62 GTW_w309_VCUSBversionMismatch "Gateway: w309 VCUS bversion mismatch";
CM_ SG_ 62 GTW_w311_canLogQueueFullBeforeFs "Gateway: w311 can log queue full before fs init";
CM_ SG_ 62 GTW_w312_hrlFileIncomplete "Gateway: w312 hrl file incomplete";
CM_ SG_ 62 GTW_w313_OSDActive "Gateway: w313 OSD active";
CM_ SG_ 62 GTW_w314_canLogBlockWriteErr "Gateway: w314 can log block write err";
CM_ SG_ 62 GTW_w316_sdCardChkdskRepair "Gateway: w316 sd card chkdsk repair";
CM_ SG_ 62 GTW_w317_sdCardChkdskRepairFaile "Gateway: w317 sd card chkdsk repair failed";
CM_ SG_ 62 GTW_w322_gestureUnrecognizedFrom "Gateway: w322 gesture unrecognized from moving";
CM_ SG_ 62 GTW_w323_gestureStartOutOfStrip "Gateway: w323 gesture start out of strip";
CM_ SG_ 62 GTW_w328_smartShiftDisabled "Gateway: w328 smart shift disabled";
CM_ SG_ 62 GTW_w329_FOHMversionMismatch "Gateway: w329 FOH mversion mismatch";
CM_ SG_ 62 GTW_w330_SWSLversionMismatch "Gateway: w330 SWS lversion mismatch";
CM_ SG_ 62 GTW_w331_SWSRversionMismatch "Gateway: w331 SWS rversion mismatch";
CM_ SG_ 62 GTW_w332_unknownDisplayPN "Gateway: w332 unknown display PN";
CM_ SG_ 62 GTW_w334_hrlFolderSpaceLow "Gateway: w334 hrl folder space low";
CM_ SG_ 62 GTW_w336_possibleCanTxIssue "Gateway: w336 possible can tx issue";
CM_ SG_ 62 GTW_w342_VCBLDCPPversionMismatch "Gateway: w342 VCBLDCP pversion mismatch";
CM_ SG_ 62 GTW_w348_VCBLDCFversionMismatch "Gateway: w348 VCBLDC fversion mismatch";
CM_ SG_ 62 GTW_w349_VCBLDCPBversionMismatch "Gateway: w349 VCBLDCP bversion mismatch";
CM_ SG_ 62 GTW_w350_mOSDCrcCheck "Gateway: w350 m OSD crc check";
CM_ SG_ 62 GTW_w351_sOSDCrcCheck "Gateway: w351 s OSD crc check";
CM_ SG_ 62 GTW_w352_mASILStatusCheck "Gateway: w352 m ASIL status check";
CM_ SG_ 62 GTW_w353_sASILStatusCheck "Gateway: w353 s ASIL status check";
CM_ SG_ 62 GTW_w354_EPASTPversionMismatch "Gateway: w354 EPAST pversion mismatch";
CM_ SG_ 62 GTW_w355_EPASTSversionMismatch "Gateway: w355 EPAST sversion mismatch";
CM_ SG_ 62 GTW_w356_touchGPIOStatusCheck "Gateway: w356 touch GPIO status check";
CM_ SG_ 62 GTW_w358_RGBIPFLversionMismatch "Gateway: w358 RGBIPF lversion mismatch";
CM_ SG_ 62 GTW_w359_RGBIPFRversionMismatch "Gateway: w359 RGBIPF rversion mismatch";
CM_ SG_ 62 GTW_w360_RGBDOORFLversionMismatc "Gateway: w360 RGBDOORF lversion mismatch";
CM_ SG_ 62 GTW_w361_RGBDOORRLversionMismatc "Gateway: w361 RGBDOORR lversion mismatch";
CM_ SG_ 62 GTW_w362_RGBDOORFRversionMismatc "Gateway: w362 RGBDOORF rversion mismatch";
CM_ SG_ 62 GTW_w363_RGBDOORRRversionMismatc "Gateway: w363 RGBDOORR rversion mismatch";
CM_ SG_ 62 GTW_w364_BLEEPCRADLEversionMisma "Gateway: w364 BLEEPCRADL eversion mismatch";
CM_ SG_ 62 GTW_w366_uiGearRequestMismatch "Gateway: w366 ui gear request mismatch";
CM_ SG_ 62 GTW_w376_blFailedToExecBootImg "Gateway: w376 bl failed to exec boot img";
CM_ SG_ 62 GTW_w380_DPBversionMismatch "Gateway: w380 DP bversion mismatch";
CM_ SG_ 62 GTW_w381_DPBCALversionMismatch "Gateway: w381 DPBCA lversion mismatch";
CM_ SG_ 62 GTW_w382_IDBversionMismatch "Gateway: w382 ID bversion mismatch";
CM_ SG_ 62 GTW_w383_IDB1versionMismatch "Gateway: w383 idb1version mismatch";
CM_ SG_ 62 GTW_w384_IDBCALversionMismatch "Gateway: w384 IDBCA lversion mismatch";
CM_ SG_ 62 GTW_w385_RCUversionMismatch "Gateway: w385 RC uversion mismatch";
CM_ SG_ 62 GTW_w386_RCUCALversionMismatch "Gateway: w386 RCUCA lversion mismatch";
CM_ SG_ 62 GTW_w387_externalRtcReadFailure "Gateway: w387 external rtc read failure";
CM_ SG_ 62 GTW_w388_adspWatchdogSkipped "Gateway: w388 adsp watchdog skipped";
CM_ SG_ 62 GTW_w389_rcmEventDetected "Gateway: w389 rcm event detected";
CM_ SG_ 62 GTW_w391_adspMacAddrCheckFailed "Gateway: w391 adsp mac addr check failed";
CM_ SG_ 62 GTW_w393_osdSramCrcMismatch "Gateway: w393 osd sram crc mismatch";
CM_ SG_ 62 GTW_w395_lwipIcmpError "Gateway: w395 lwip icmp error";
CM_ SG_ 62 GTW_w396_alreadyInReverse "Gateway: w396 already in reverse";
CM_ SG_ 62 GTW_w397_alreadyInDrive "Gateway: w397 already in drive";
CM_ SG_ 62 GTW_w398_awakeForExtendedTime "Gateway: w398 awake for extended time";
CM_ SG_ 62 GTW_w399_ethIfRxTcpipQueueDrop "Gateway: w399 eth if rx tcpip queue drop";
CM_ SG_ 62 GTW_w400_ethlSwitchOTPIncorrect "Gateway: w400 ethl switch OTP incorrect";
CM_ SG_ 62 GTW_w409_unexpectedResetCause "Gateway: w409 unexpected reset cause";
CM_ SG_ 62 GTW_w410_unexpectedResetCause2 "Gateway: w410 unexpected reset cause2";
CM_ SG_ 62 GTW_w414_socHeldInReset "Gateway: w414 soc held in reset";
CM_ BO_ 838 "Gateway message: autopilot override";
CM_ SG_ 838 GTW_autopilotOverrideState "Signals whether an autopilot trial or subscription is active";
CM_ SG_ 838 GTW_autopilotConfig "Current level of permanent Autopilot firmware";
CM_ SG_ 838 GTW_autopilotOverrideConfig "Current level of trial or subscription Autopilot firmware";
CM_ SG_ 838 GTW_autopilotOverrideExpireTime "Expiration time for the currently active autopilot trial or subscription";
BA_DEF_ BO_ "GenMsgCycleTime" INT 0 3600000;
BA_DEF_ BO_ "GenMsgSendType" ENUM "Cyclic","NotUsed","NotUsed","NotUsed","NotUsed","NotUsed","NotUsed","IfActive","NoMsgSendType","NotUsed";
BA_DEF_ BO_ "VFrameFormat" ENUM "StandardCAN","ExtendedCAN","reserved","J1939PG","reserved","reserved","reserved","reserved","reserved","reserved","reserved","reserved","reserved","reserved","StandardCAN_FD","ExtendedCAN_FD";
BA_DEF_ BO_ "CANFD_BRS" ENUM "0","1";
BA_DEF_ SG_ "GenSigSNA" STRING;
BA_DEF_ SG_ "SystemSignalLongSymbol" STRING;
BA_DEF_ SG_ "Confidence" ENUM "validated","plausible","layout-only","contradicted";
BA_DEF_DEF_ "GenMsgCycleTime" 0;
BA_DEF_DEF_ "GenMsgSendType" "NoMsgSendType";
BA_DEF_DEF_ "VFrameFormat" "StandardCAN";
BA_DEF_DEF_ "CANFD_BRS" "1";
BA_DEF_DEF_ "GenSigSNA" "";
BA_DEF_DEF_ "SystemSignalLongSymbol" "";
BA_DEF_DEF_ "Confidence" "layout-only";
BA_ "GenMsgCycleTime" BO_ 1000 100;
BA_ "GenMsgSendType" BO_ 1000 0;
BA_ "GenMsgCycleTime" BO_ 742 1000;
BA_ "GenMsgSendType" BO_ 742 0;
BA_ "GenMsgCycleTime" BO_ 744 100;
BA_ "GenMsgSendType" BO_ 744 0;
BA_ "GenMsgCycleTime" BO_ 981 1000;
BA_ "GenMsgSendType" BO_ 981 0;
BA_ "GenMsgCycleTime" BO_ 1621 100;
BA_ "GenMsgSendType" BO_ 1621 0;
BA_ "GenMsgCycleTime" BO_ 373 20;
BA_ "GenMsgSendType" BO_ 373 0;
BA_ "GenMsgCycleTime" BO_ 888 1000;
BA_ "GenMsgSendType" BO_ 888 0;
BA_ "GenMsgCycleTime" BO_ 282 1000;
BA_ "GenMsgSendType" BO_ 282 0;
BA_ "GenMsgCycleTime" BO_ 62 100;
BA_ "GenMsgSendType" BO_ 62 0;
BA_ "GenMsgCycleTime" BO_ 838 1000;
BA_ "GenMsgSendType" BO_ 838 0;
BA_ "Confidence" SG_ 1000 EPBR_matrixIndex 1;
BA_ "Confidence" SG_ 1000 EPBR_a001_WatchdogReset 1;
BA_ "Confidence" SG_ 1000 EPBR_a002_PowerLossReset 1;
BA_ "Confidence" SG_ 1000 EPBR_a003_SWAssertion 1;
BA_ "Confidence" SG_ 1000 EPBR_a005_CANTXError 1;
BA_ "Confidence" SG_ 1000 EPBR_a006_CANTX_cyclicError 1;
BA_ "Confidence" SG_ 1000 EPBR_a012_CPUReset 1;
BA_ "Confidence" SG_ 1000 EPBR_a013_AlertManagerFault 1;
BA_ "Confidence" SG_ 1000 EPBR_a015_NVMMError 1;
BA_ "Confidence" SG_ 1000 EPBR_a016_NVMMRecordError 1;
BA_ "Confidence" SG_ 1000 EPBR_a021_TaskSchedulerError 1;
BA_ "Confidence" SG_ 1000 EPBR_a022_TaskInitError 1;
BA_ "Confidence" SG_ 1000 EPBR_a029_CoreDump 1;
BA_ "Confidence" SG_ 1000 EPBR_a030_ECULogUploadRequest 1;
BA_ "Confidence" SG_ 1000 EPBR_a031_UDSActive 1;
BA_ "Confidence" SG_ 1000 EPBR_a041_HighCPULoad 1;
BA_ "Confidence" SG_ 1000 EPBR_a042_HighStackUsage 1;
BA_ "Confidence" SG_ 1000 EPBR_a043_Task1msError 1;
BA_ "Confidence" SG_ 1000 EPBR_a044_Task10msError 1;
BA_ "Confidence" SG_ 1000 EPBR_a045_Task100msError 1;
BA_ "Confidence" SG_ 1000 EPBR_a046_Task1000msError 1;
BA_ "Confidence" SG_ 1000 EPBR_a057_HVP_MIA 1;
BA_ "Confidence" SG_ 1000 EPBR_a058_inputRHighSyncDebug 1;
BA_ "Confidence" SG_ 1000 EPBR_a059_inputResistanceHigh 1;
BA_ "Confidence" SG_ 1000 EPBR_a060_engineeringBuild 1;
BA_ "Confidence" SG_ 1000 EPBR_a061_XCPConnected 1;
BA_ "Confidence" SG_ 1000 EPBR_a062_XCPWasConnected 1;
BA_ "Confidence" SG_ 1000 EPBR_a063_SwitchFault 1;
BA_ "Confidence" SG_ 1000 EPBR_a064_busSleepReqTimeout 1;
BA_ "Confidence" SG_ 1000 EPBR_a081_APP_MIA 1;
BA_ "Confidence" SG_ 1000 EPBR_a082_VCRIGHT_IPC_MIA 1;
BA_ "Confidence" SG_ 1000 EPBR_a083_VCLEFT_IPC_MIA 1;
BA_ "Confidence" SG_ 1000 EPBR_a084_TPMS_MIA 1;
BA_ "Confidence" SG_ 1000 EPBR_a085_CCCM_MIA 1;
BA_ "Confidence" SG_ 1000 EPBR_a086_VCBATT_MIA 1;
BA_ "Confidence" SG_ 1000 EPBR_a087_DIREL_MIA 1;
BA_ "Confidence" SG_ 1000 EPBR_a088_DIRER_MIA 1;
BA_ "Confidence" SG_ 1000 EPBR_a089_IBST_MIA 1;
BA_ "Confidence" SG_ 1000 EPBR_a090_APS_MIA 1;
BA_ "Confidence" SG_ 1000 EPBR_a091_CMPD_MIA 1;
BA_ "Confidence" SG_ 1000 EPBR_a092_VCSEATD_MIA 1;
BA_ "Confidence" SG_ 1000 EPBR_a093_VCSEATP_MIA 1;
BA_ "Confidence" SG_ 1000 EPBR_a094_EPAS3P_MIA 1;
BA_ "Confidence" SG_ 1000 EPBR_a095_CHG_MIA 1;
BA_ "Confidence" SG_ 1000 EPBR_a096_OCS1P_MIA 1;
BA_ "Confidence" SG_ 1000 EPBR_a097_CMP_MIA 1;
BA_ "Confidence" SG_ 1000 EPBR_a098_DIR_MIA 1;
BA_ "Confidence" SG_ 1000 EPBR_a099_PARK_MIA 1;
BA_ "Confidence" SG_ 1000 EPBR_a100_CANbus_MIA 1;
BA_ "Confidence" SG_ 1000 EPBR_a101_PM_MIA 1;
BA_ "Confidence" SG_ 1000 EPBR_a102_PTC_MIA 1;
BA_ "Confidence" SG_ 1000 EPBR_a103_CP_MIA 1;
BA_ "Confidence" SG_ 1000 EPBR_a104_DAS_MIA 1;
BA_ "Confidence" SG_ 1000 EPBR_a105_TAS_MIA 1;
BA_ "Confidence" SG_ 1000 EPBR_a106_PCS_MIA 1;
BA_ "Confidence" SG_ 1000 EPBR_a107_BMS_MIA 1;
BA_ "Confidence" SG_ 1000 EPBR_a108_DIF_MIA 1;
BA_ "Confidence" SG_ 1000 EPBR_a109_RCM_MIA 1;
BA_ "Confidence" SG_ 1000 EPBR_a110_GTW_MIA 1;
BA_ "Confidence" SG_ 1000 EPBR_a111_EPBR_MIA 1;
BA_ "Confidence" SG_ 1000 EPBR_a112_EPBL_MIA 1;
BA_ "Confidence" SG_ 1000 EPBR_a113_UI_MIA 1;
BA_ "Confidence" SG_ 1000 EPBR_a114_ESP_MIA 1;
BA_ "Confidence" SG_ 1000 EPBR_a115_VCSEC_MIA 1;
BA_ "Confidence" SG_ 1000 EPBR_a116_VCRIGHT_MIA 1;
BA_ "Confidence" SG_ 1000 EPBR_a117_VCLEFT_MIA 1;
BA_ "Confidence" SG_ 1000 EPBR_a118_VCFRONT_MIA 1;
BA_ "Confidence" SG_ 1000 EPBR_a119_SCCM_MIA 1;
BA_ "Confidence" SG_ 1000 EPBR_a120_DI_DRIVE_MIA 1;
BA_ "Confidence" SG_ 1000 EPBR_a121_nDriveFault 1;
BA_ "Confidence" SG_ 1000 EPBR_a122_Oc 1;
BA_ "Confidence" SG_ 1000 EPBR_a123_Uc 1;
BA_ "Confidence" SG_ 1000 EPBR_a124_calOutOfBounds 1;
BA_ "Confidence" SG_ 1000 EPBR_a125_IdleVMismatch 1;
BA_ "Confidence" SG_ 1000 EPBR_a126_MotorNVoltLow 1;
BA_ "Confidence" SG_ 1000 EPBR_a127_MotorNVoltHigh 1;
BA_ "Confidence" SG_ 1000 EPBR_a128_MotorPVoltHigh 1;
BA_ "Confidence" SG_ 1000 EPBR_a129_ICR_MIA 1;
BA_ "Confidence" SG_ 1000 EPBR_a130_BB_MIA 1;
BA_ "Confidence" SG_ 1000 EPBR_a131_RCU_MIA 1;
BA_ "Confidence" SG_ 1000 EPBR_a132_VCBATT1_MIA 1;
BA_ "Confidence" SG_ 1000 EPBR_a134_NvOv 1;
BA_ "Confidence" SG_ 1000 EPBR_a135_NvUv 1;
BA_ "Confidence" SG_ 1000 EPBR_a136_PvOv 1;
BA_ "Confidence" SG_ 1000 EPBR_a137_PvUv 1;
BA_ "Confidence" SG_ 1000 EPBR_a138_NvmDualFailure 1;
BA_ "Confidence" SG_ 1000 EPBR_a139_NvmRedundancyLoss 1;
BA_ "Confidence" SG_ 1000 EPBR_a140_NvmSlowWrite 1;
BA_ "Confidence" SG_ 1000 EPBR_a141_invalidState 1;
BA_ "Confidence" SG_ 1000 EPBR_a170_12vOv 1;
BA_ "Confidence" SG_ 1000 EPBR_a171_12vUv 1;
BA_ "Confidence" SG_ 1000 EPBR_a172_SPI_MIA 1;
BA_ "Confidence" SG_ 1000 EPBR_a173_hiCurrentMissing 1;
BA_ "Confidence" SG_ 1000 EPBR_a174_csmReleaseFailed 1;
BA_ "Confidence" SG_ 1000 EPBR_a175_csmReleaseRetry 1;
BA_ "Confidence" SG_ 1000 EPBR_a176_csmApplyFailed 1;
BA_ "Confidence" SG_ 1000 EPBR_a177_csmApplyRetry 1;
BA_ "Confidence" SG_ 1000 EPBR_a178_caliperStateUnknown 1;
BA_ "Confidence" SG_ 1000 EPBR_a179_epbProblem 1;
BA_ "Confidence" SG_ 1000 EPBR_a180_dynamicActive 1;
BA_ "Confidence" SG_ 1000 EPBR_a181_TooSteepGradeToPark 1;
BA_ "Confidence" SG_ 1000 EPBR_a182_OneEPBAppliedUnsecEnv 1;
BA_ "Confidence" SG_ 1000 EPBR_a183_cdpNotAvailable 1;
BA_ "Confidence" SG_ 1000 EPBR_a184_dynamicParkAbort 1;
BA_ "Confidence" SG_ 1000 EPBR_a185_summonAborted 1;
BA_ "Confidence" SG_ 1000 EPBR_a186_externalParkAbort 1;
BA_ "Confidence" SG_ 1000 EPBR_a187_cdpDynamic 1;
BA_ "Confidence" SG_ 1000 EPBR_a188_epbDynamic 1;
BA_ "Confidence" SG_ 1000 EPBR_a189_epbDynamicParkCanceled 1;
BA_ "Confidence" SG_ 1000 EPBR_a190_csmApplyDegraded 1;
BA_ "Confidence" SG_ 1000 EPBR_a191_csmReleaseDegraded 1;
BA_ "Confidence" SG_ 1000 EPBR_a195_parkForDriverIsLeaving 1;
BA_ "Confidence" SG_ 1000 EPBR_a196_freeRollModeActive 1;
BA_ "Confidence" SG_ 1000 EPBR_a197_freeRollModeAtSpeed 1;
BA_ "Confidence" SG_ 1000 EPBR_a198_holdClampComplete 1;
BA_ "Confidence" SG_ 1000 EPBR_a200_PmUnparkNotAllowed 1;
BA_ "Confidence" SG_ 1000 EPBR_a202_remoteEpbConfigIncompa 1;
BA_ "SystemSignalLongSymbol" SG_ 1000 EPBR_a202_remoteEpbConfigIncompa "EPBR_a202_remoteEpbConfigIncompatible";
BA_ "Confidence" SG_ 1000 EPBR_a203_hwBrakeTypeMismatch 1;
BA_ "Confidence" SG_ 1000 EPBR_a210_parkForDriverIsLeaving 1;
BA_ "SystemSignalLongSymbol" SG_ 1000 EPBR_a210_parkForDriverIsLeaving "EPBR_a210_parkForDriverIsLeavingDebug";
BA_ "Confidence" SG_ 1000 EPBR_a216_SPI_MIA_debugData1 1;
BA_ "Confidence" SG_ 1000 EPBR_a217_SPI_MIA_debugData2 1;
BA_ "Confidence" SG_ 1000 EPBR_a225_epbActiveDecel 1;
BA_ "Confidence" SG_ 1000 EPBR_a241_diOutputLocked 1;
BA_ "Confidence" SG_ 1000 EPBR_a242_hvOutputLocked 1;
BA_ "Confidence" SG_ 1000 EPBR_a243_bdwUnavailable 1;
BA_ "Confidence" SG_ 1000 EPBR_a244_WinchModeActive 1;
BA_ "Confidence" SG_ 1000 EPBR_a245_serviceModeActive 1;
BA_ "Confidence" SG_ 1000 EPBR_a246_idleFaultApply 1;
BA_ "Confidence" SG_ 1000 EPBR_a247_csmDynamicApplyRetry 1;
BA_ "Confidence" SG_ 1000 EPBR_a248_csmDynamicApplyFailed 1;
BA_ "Confidence" SG_ 1000 EPBR_a249_idleFaultRelease 1;
BA_ "Confidence" SG_ 1000 EPBR_a250_WinchModeCanceled 1;
BA_ "Confidence" SG_ 1000 EPBR_a251_currentVarianceHigh 1;
BA_ "Confidence" SG_ 1000 EPBR_a252_winchModePending 1;
BA_ "Confidence" SG_ 1000 EPBR_a253_esmReleaseBlocked 1;
BA_ "Confidence" SG_ 1000 EPBR_a254_showStalkParkButtonFau 1;
BA_ "SystemSignalLongSymbol" SG_ 1000 EPBR_a254_showStalkParkButtonFau "EPBR_a254_showStalkParkButtonFaultOnUi";
BA_ "Confidence" SG_ 1000 EPBR_a256_epbSystemApply 1;
BA_ "Confidence" SG_ 1000 EPBR_a261_winchModeWithoutSteeri 1;
BA_ "SystemSignalLongSymbol" SG_ 1000 EPBR_a261_winchModeWithoutSteeri "EPBR_a261_winchModeWithoutSteering";
BA_ "Confidence" SG_ 1000 EPBR_a262_cannotPrepareWinchMode 1;
BA_ "Confidence" SG_ 1000 EPBR_a263_epbRecoveryPark 1;
BA_ "Confidence" SG_ 1000 EPBR_a264_winchModeDeactivated 1;
BA_ "Confidence" SG_ 1000 EPBR_a272_vhclPwrStateMsmtch 1;
BA_ "Confidence" SG_ 1000 EPBR_a300_leftRightConfusion 1;
BA_ "Confidence" SG_ 1000 EPBR_a301_oocSpeedViolation 1;
BA_ "Confidence" SG_ 1000 EPBR_a302_csmLongRelease 1;
BA_ "Confidence" SG_ 1000 EPBR_a303_clampingOccuredEarly 1;
BA_ "Confidence" SG_ 1000 EPBR_a304_rearSeatControllerEFus 1;
BA_ "SystemSignalLongSymbol" SG_ 1000 EPBR_a304_rearSeatControllerEFus "EPBR_a304_rearSeatControllerEFuseTrip";
BA_ "Confidence" SG_ 1000 EPBR_a305_premiumAmpEFuseTrip 1;
BA_ "Confidence" SG_ 1000 EPBR_a350_ensOutOfRange 1;
BA_ "Confidence" SG_ 1000 EPBR_a352_audioCurrentSpikeData 1;
BA_ "Confidence" SG_ 1000 EPBR_a353_missingSpeedUnableToPa 1;
BA_ "SystemSignalLongSymbol" SG_ 1000 EPBR_a353_missingSpeedUnableToPa "EPBR_a353_missingSpeedUnableToPark";
BA_ "Confidence" SG_ 1000 EPBR_a354_parkedForLowBrakeFluid 1;
BA_ "SystemSignalLongSymbol" SG_ 1000 EPBR_a354_parkedForLowBrakeFluid "EPBR_a354_parkedForLowBrakeFluidMode";
BA_ "Confidence" SG_ 1000 EPBR_a355_brakeHwAndEpbHwMismatc 1;
BA_ "SystemSignalLongSymbol" SG_ 1000 EPBR_a355_brakeHwAndEpbHwMismatc "EPBR_a355_brakeHwAndEpbHwMismatch";
BA_ "Confidence" SG_ 1000 EPBR_a356_parkingForStationaryDe 1;
BA_ "SystemSignalLongSymbol" SG_ 1000 EPBR_a356_parkingForStationaryDe "EPBR_a356_parkingForStationaryDetect";
BA_ "Confidence" SG_ 1000 EPBR_a357_brakesTooHotForSlope 1;
BA_ "Confidence" SG_ 1000 EPBR_a358_brakesTooHotForSlopeWi 1;
BA_ "SystemSignalLongSymbol" SG_ 1000 EPBR_a358_brakesTooHotForSlopeWi "EPBR_a358_brakesTooHotForSlopeWithOnlyOneEpb";
BA_ "Confidence" SG_ 1000 EPBR_a360_ibstBrakeSwitchInvalid 1;
BA_ "Confidence" SG_ 1000 EPBR_a361_espBrakeSwitchInvalid 1;
BA_ "Confidence" SG_ 1000 EPBR_a362_ibstPressedEspNotPress 1;
BA_ "SystemSignalLongSymbol" SG_ 1000 EPBR_a362_ibstPressedEspNotPress "EPBR_a362_ibstPressedEspNotPressedMismatch";
BA_ "Confidence" SG_ 1000 EPBR_a363_ibstNotPressedEspPress 1;
BA_ "SystemSignalLongSymbol" SG_ 1000 EPBR_a363_ibstNotPressedEspPress "EPBR_a363_ibstNotPressedEspPressedMismatch";
BA_ "Confidence" SG_ 1000 EPBR_a364_espMasterCylCompOverTh 1;
BA_ "SystemSignalLongSymbol" SG_ 1000 EPBR_a364_espMasterCylCompOverTh "EPBR_a364_espMasterCylCompOverThreshold";
BA_ "Confidence" SG_ 1000 EPBR_a365_TooSteepToParkWithTrai 1;
BA_ "SystemSignalLongSymbol" SG_ 1000 EPBR_a365_TooSteepToParkWithTrai "EPBR_a365_TooSteepToParkWithTrailerWarning";
BA_ "Confidence" SG_ 1000 EPBR_a366_TooSteepToParkWithTrai 1;
BA_ "SystemSignalLongSymbol" SG_ 1000 EPBR_a366_TooSteepToParkWithTrai "EPBR_a366_TooSteepToParkWithTrailerUnSecEnv";
BA_ "Confidence" SG_ 742 EPBR_frontSeatCushionFanCur 0;
BA_ "Confidence" SG_ 742 EPBR_frontSeatBackrestFanCur 0;
BA_ "Confidence" SG_ 742 EPBR_frontSeatCushionFanDuty 0;
BA_ "Confidence" SG_ 742 EPBR_frontSeatCushionFanEn 0;
BA_ "Confidence" SG_ 742 EPBR_frontSeatBackrestFanEn 0;
BA_ "Confidence" SG_ 742 EPBR_frontSeatBackrestFanDuty 0;
BA_ "Confidence" SG_ 744 EPBR_systemStatus 0;
BA_ "Confidence" SG_ 744 EPBR_freeRollModeStatus 0;
BA_ "Confidence" SG_ 744 EPBR_driverIsLeaving 0;
BA_ "Confidence" SG_ 744 EPBR_driverIsLeavingAnySpeed 0;
BA_ "Confidence" SG_ 744 EPBR_systemCdpAvailable 0;
BA_ "Confidence" SG_ 744 EPBR_chimeRequest 0;
BA_ "Confidence" SG_ 744 EPBR_telltale 0;
BA_ "GenSigSNA" SG_ 744 EPBR_telltale "7";
BA_ "Confidence" SG_ 744 EPBR_audioCurrentSpikeDetected 0;
BA_ "Confidence" SG_ 744 EPBR_redundantBrakingEnabled 0;
BA_ "Confidence" SG_ 744 EPBR_summonEnabled 0;
BA_ "Confidence" SG_ 744 EPBR_brakeLight 0;
BA_ "Confidence" SG_ 744 EPBR_epbConfigMismatch 0;
BA_ "Confidence" SG_ 744 EPBR_brakeConfirmedPressed 0;
BA_ "Confidence" SG_ 744 EPBR_requestUserConfirmation 0;
BA_ "Confidence" SG_ 744 EPBR_uiWinchModeMiscBlocking 0;
BA_ "Confidence" SG_ 744 EPBR_winchModeActive 0;
BA_ "Confidence" SG_ 744 EPBR_updateMode 0;
BA_ "Confidence" SG_ 744 EPBR_winchModePermissive 0;
BA_ "Confidence" SG_ 744 EPBR_winchModePending 0;
BA_ "Confidence" SG_ 744 EPBR_cdpRequest 0;
BA_ "Confidence" SG_ 744 EPBR_uiParkAvailable 0;
BA_ "Confidence" SG_ 744 EPBR_brakeDiscWipeRequest 0;
BA_ "GenSigSNA" SG_ 744 EPBR_brakeDiscWipeRequest "3";
BA_ "Confidence" SG_ 744 EPBR_showUiGearShifter 0;
BA_ "Confidence" SG_ 744 EPBR_uiWinchModeLvStatus 0;
BA_ "Confidence" SG_ 744 EPBR_contactorCycleNotNeededForW 0;
BA_ "SystemSignalLongSymbol" SG_ 744 EPBR_contactorCycleNotNeededForW "EPBR_contactorCycleNotNeededForWinchEntry";
BA_ "Confidence" SG_ 744 EPBR_showStalkFaultedOnUi 0;
BA_ "Confidence" SG_ 744 EPBR_espPowerRequest 0;
BA_ "Confidence" SG_ 744 EPBR_okToPark 0;
BA_ "Confidence" SG_ 744 EPBR_hornRequest 0;
BA_ "Confidence" SG_ 744 EPBR_winchModeAvailable 0;
BA_ "Confidence" SG_ 744 EPBR_bothDisconnected 0;
BA_ "Confidence" SG_ 744 EPBR_blockDrive 0;
BA_ "Confidence" SG_ 744 EPBR_statusCounter 0;
BA_ "Confidence" SG_ 744 EPBR_statusChecksum 0;
BA_ "Confidence" SG_ 1575 EPBR_udsResponseData_H 1;
BA_ "Confidence" SG_ 1575 EPBR_udsResponseData_L 1;
BA_ "Confidence" SG_ 981 ESP_matrixIndex 1;
BA_ "SystemSignalLongSymbol" SG_ 981 ESP_a193_DIchassisControlChecksu "ESP_a193_DIchassisControlChecksum";
BA_ "SystemSignalLongSymbol" SG_ 981 ESP_a269_DIRELTorqueCommandInval "ESP_a269_DIRELTorqueCommandInvalid";
BA_ "SystemSignalLongSymbol" SG_ 981 ESP_a271_DIRELTorqueActualInvali "ESP_a271_DIRELTorqueActualInvalid";
BA_ "SystemSignalLongSymbol" SG_ 981 ESP_a276_DIRERTorqueCommandInval "ESP_a276_DIRERTorqueCommandInvalid";
BA_ "SystemSignalLongSymbol" SG_ 981 ESP_a278_DIRERTorqueActualInvali "ESP_a278_DIRERTorqueActualInvalid";
BA_ "SystemSignalLongSymbol" SG_ 981 ESP_a279_lifetimeManagementOverr "ESP_a279_lifetimeManagementOverrun";
BA_ "SystemSignalLongSymbol" SG_ 981 ESP_a282_trackModeABSRequestInva "ESP_a282_trackModeABSRequestInvalid";
BA_ "SystemSignalLongSymbol" SG_ 981 ESP_a283_secondaryCollisionMitig "ESP_a283_secondaryCollisionMitigationActive";
BA_ "SystemSignalLongSymbol" SG_ 981 ESP_a284_scmRequestInvalidChecks "ESP_a284_scmRequestInvalidChecksum";
BA_ "SystemSignalLongSymbol" SG_ 981 ESP_a287_failedBrakeCircuitDetec "ESP_a287_failedBrakeCircuitDetected";
BA_ "SystemSignalLongSymbol" SG_ 981 ESP_a296_roadWheelAngleHealthDeg "ESP_a296_roadWheelAngleHealthDegraded";
BA_ "SystemSignalLongSymbol" SG_ 981 ESP_a297_roadWheelAngleHealthFau "ESP_a297_roadWheelAngleHealthFaulted";
BA_ "SystemSignalLongSymbol" SG_ 981 ESP_a298_RSArearSteerStatusTimeo "ESP_a298_RSArearSteerStatusTimeout";
BA_ "SystemSignalLongSymbol" SG_ 981 ESP_a300_RSArearSteerStatusCheck "ESP_a300_RSArearSteerStatusChecksum";
BA_ "SystemSignalLongSymbol" SG_ 981 ESP_a302_rearRoadWheelAngleHealt "ESP_a302_rearRoadWheelAngleHealthDegraded";
BA_ "SystemSignalLongSymbol" SG_ 981 ESP_a303_rearRoadWheelAngleHealt "ESP_a303_rearRoadWheelAngleHealthFaulted";
BA_ "SystemSignalLongSymbol" SG_ 981 ESP_a304_rearVCLVPowerStateTimeo "ESP_a304_rearVCLVPowerStateTimeout";
BA_ "SystemSignalLongSymbol" SG_ 981 ESP_a306_rearVCLVPowerStateCheck "ESP_a306_rearVCLVPowerStateChecksum";
BA_ "SystemSignalLongSymbol" SG_ 981 ESP_a307_rearVCLVPowerStateCount "ESP_a307_rearVCLVPowerStateCounter";
BA_ "SystemSignalLongSymbol" SG_ 981 ESP_a310_brakeLatencyReductionAc "ESP_a310_brakeLatencyReductionActive";
BA_ "SystemSignalLongSymbol" SG_ 981 ESP_a319_AES_BackupActuatorActiv "ESP_a319_AES_BackupActuatorActive";
BA_ "SystemSignalLongSymbol" SG_ 981 ESP_a334_BrakePedalAppliedInvali "ESP_a334_BrakePedalAppliedInvalid";
BA_ "SystemSignalLongSymbol" SG_ 981 ESP_a337_pReductionPotentialInva "ESP_a337_pReductionPotentialInvalid";
BA_ "SystemSignalLongSymbol" SG_ 981 ESP_a341_EnhancedPressureBuildAc "ESP_a341_EnhancedPressureBuildActive";
BA_ "SystemSignalLongSymbol" SG_ 981 ESP_a342_EnhancedPressureBuildNo "ESP_a342_EnhancedPressureBuildNotActive";
BA_ "SystemSignalLongSymbol" SG_ 981 ESP_a343_EnhancedPressureBuildLt "ESP_a343_EnhancedPressureBuildLtmReached";
BA_ "SystemSignalLongSymbol" SG_ 981 ESP_a351_ActuatorYellowLampReque "ESP_a351_ActuatorYellowLampRequested";
BA_ "SystemSignalLongSymbol" SG_ 981 ESP_a353_PressureSensorImplausHi "ESP_a353_PressureSensorImplausHigh";
BA_ "SystemSignalLongSymbol" SG_ 981 ESP_a358_externalActuatorFallbac "ESP_a358_externalActuatorFallback";
BA_ "SystemSignalLongSymbol" SG_ 981 ESP_a359_externalActuatorNoExtRe "ESP_a359_externalActuatorNoExtReq";
BA_ "SystemSignalLongSymbol" SG_ 981 ESP_a362_BBbrakeActuationChecksu "ESP_a362_BBbrakeActuationChecksum";
BA_ "SystemSignalLongSymbol" SG_ 981 ESP_a366_ActuatorBlendingModeReq "ESP_a366_ActuatorBlendingModeReqNotAvailable";
BA_ "SystemSignalLongSymbol" SG_ 981 ESP_a367_CBDS_fillBufferThreshol "ESP_a367_CBDS_fillBufferThreshold";
BA_ "SystemSignalLongSymbol" SG_ 981 ESP_a369_LargeLeakageDetectedByD "ESP_a369_LargeLeakageDetectedByDPB";
BA_ "Confidence" SG_ 1621 ESP_udsResponseData 1;
BA_ "Confidence" SG_ 373 ESP_wheelSpeedFrL 1;
BA_ "Confidence" SG_ 373 ESP_wheelSpeedFrR 1;
BA_ "Confidence" SG_ 373 ESP_wheelSpeedReL 1;
BA_ "Confidence" SG_ 373 ESP_wheelSpeedReR 1;
BA_ "Confidence" SG_ 888 GTW_GTW_SOS_ECALL_RQST 0;
BA_ "Confidence" SG_ 888 GTW_LTE_ECALL_LOCK 0;
BA_ "Confidence" SG_ 282 GTW_BKP_BATT_MON 1;
BA_ "GenSigSNA" SG_ 282 GTW_BKP_BATT_MON "4095";
BA_ "Confidence" SG_ 282 GTW_BKP_BATT_NTC_P 1;
BA_ "GenSigSNA" SG_ 282 GTW_BKP_BATT_NTC_P "4095";
BA_ "Confidence" SG_ 282 GTW_ECALL_GPS_ANT_BIAS 1;
BA_ "GenSigSNA" SG_ 282 GTW_ECALL_GPS_ANT_BIAS "4095";
BA_ "Confidence" SG_ 282 GTW_ECALL_MIC_DIAG 1;
BA_ "GenSigSNA" SG_ 282 GTW_ECALL_MIC_DIAG "4095";
BA_ "Confidence" SG_ 282 GTW_SOS_ECALL_nRQST_BUF 1;
BA_ "GenSigSNA" SG_ 282 GTW_SOS_ECALL_nRQST_BUF "4095";
BA_ "Confidence" SG_ 1384 GTW_alertID 1;
BA_ "Confidence" SG_ 1384 GTW_alertState 1;
BA_ "Confidence" SG_ 1384 GTW_a049_headerError 1;
BA_ "Confidence" SG_ 1384 GTW_a062_bmpWatchdogReason 1;
BA_ "Confidence" SG_ 1384 GTW_a063_VEH_faultConfinement 1;
BA_ "Confidence" SG_ 1384 GTW_a064_CH_faultConfinement 1;
BA_ "Confidence" SG_ 1384 GTW_a065_PARTY_faultConfinement 1;
BA_ "Confidence" SG_ 1384 GTW_a077_bmpPmicErrorType 1;
BA_ "Confidence" SG_ 1384 GTW_a078_loadPercent 1;
BA_ "Confidence" SG_ 1384 GTW_a079_loadPercent 1;
BA_ "Confidence" SG_ 1384 GTW_a080_loadPercent 1;
BA_ "Confidence" SG_ 1384 GTW_a081_ISOTPmsgType 1;
BA_ "Confidence" SG_ 1384 GTW_a081_udsSID 1;
BA_ "Confidence" SG_ 1384 GTW_a122_BDY_faultConfinement 1;
BA_ "Confidence" SG_ 1384 GTW_a261_failureReason 1;
BA_ "Confidence" SG_ 1384 GTW_a277_mitigationFailureReason 1;
BA_ "Confidence" SG_ 1384 GTW_a279_failureReason 1;
BA_ "Confidence" SG_ 1384 GTW_a317_status 1;
BA_ "Confidence" SG_ 1384 GTW_a317_errorCode 1;
BA_ "Confidence" SG_ 62 GTW_matrixIndex 1;
BA_ "SystemSignalLongSymbol" SG_ 62 GTW_w016_BLEEPCENTERversionMisma "GTW_w016_BLEEPCENTERversionMismatch";
BA_ "SystemSignalLongSymbol" SG_ 62 GTW_w093_sdCardInvReqOverflowBas "GTW_w093_sdCardInvReqOverflowBase";
BA_ "SystemSignalLongSymbol" SG_ 62 GTW_w094_sdCardInvReqOverflowCou "GTW_w094_sdCardInvReqOverflowCount";
BA_ "SystemSignalLongSymbol" SG_ 62 GTW_w104_sdCardDriverArgCorrupte "GTW_w104_sdCardDriverArgCorrupted";
BA_ "SystemSignalLongSymbol" SG_ 62 GTW_w106_BLEEPLEFTversionMismatc "GTW_w106_BLEEPLEFTversionMismatch";
BA_ "SystemSignalLongSymbol" SG_ 62 GTW_w107_BLEEPRIGHTversionMismat "GTW_w107_BLEEPRIGHTversionMismatch";
BA_ "SystemSignalLongSymbol" SG_ 62 GTW_w108_BLEEPREARversionMismatc "GTW_w108_BLEEPREARversionMismatch";
BA_ "SystemSignalLongSymbol" SG_ 62 GTW_w117_unexpectedDestructiveRe "GTW_w117_unexpectedDestructiveResetStatus";
BA_ "SystemSignalLongSymbol" SG_ 62 GTW_w118_unexpectedFunctionalRes "GTW_w118_unexpectedFunctionalResetStatus";
BA_ "SystemSignalLongSymbol" SG_ 62 GTW_w146_performancePackageMisma "GTW_w146_performancePackageMismatch";
BA_ "SystemSignalLongSymbol" SG_ 62 GTW_w227_DISPTOUCHversionMismatc "GTW_w227_DISPTOUCHversionMismatch";
BA_ "SystemSignalLongSymbol" SG_ 62 GTW_w229_displaySoftsetConnectio "GTW_w229_displaySoftsetConnection";
BA_ "SystemSignalLongSymbol" SG_ 62 GTW_w273_BLEEPREARLEFTversionMis "GTW_w273_BLEEPREARLEFTversionMismatch";
BA_ "SystemSignalLongSymbol" SG_ 62 GTW_w274_BLEEPREARRIGHTversionMi "GTW_w274_BLEEPREARRIGHTversionMismatch";
BA_ "SystemSignalLongSymbol" SG_ 62 GTW_w277_NonRevCDrMOSMitigationF "GTW_w277_NonRevCDrMOSMitigationFailed";
BA_ "SystemSignalLongSymbol" SG_ 62 GTW_w282_tcuPhyConfigurationFail "GTW_w282_tcuPhyConfigurationFailed";
BA_ "SystemSignalLongSymbol" SG_ 62 GTW_w311_canLogQueueFullBeforeFs "GTW_w311_canLogQueueFullBeforeFsInit";
BA_ "SystemSignalLongSymbol" SG_ 62 GTW_w317_sdCardChkdskRepairFaile "GTW_w317_sdCardChkdskRepairFailed";
BA_ "SystemSignalLongSymbol" SG_ 62 GTW_w322_gestureUnrecognizedFrom "GTW_w322_gestureUnrecognizedFromMoving";
BA_ "SystemSignalLongSymbol" SG_ 62 GTW_w360_RGBDOORFLversionMismatc "GTW_w360_RGBDOORFLversionMismatch";
BA_ "SystemSignalLongSymbol" SG_ 62 GTW_w361_RGBDOORRLversionMismatc "GTW_w361_RGBDOORRLversionMismatch";
BA_ "SystemSignalLongSymbol" SG_ 62 GTW_w362_RGBDOORFRversionMismatc "GTW_w362_RGBDOORFRversionMismatch";
BA_ "SystemSignalLongSymbol" SG_ 62 GTW_w363_RGBDOORRRversionMismatc "GTW_w363_RGBDOORRRversionMismatch";
BA_ "SystemSignalLongSymbol" SG_ 62 GTW_w364_BLEEPCRADLEversionMisma "GTW_w364_BLEEPCRADLEversionMismatch";
BA_ "Confidence" SG_ 838 GTW_autopilotOverrideState 1;
BA_ "Confidence" SG_ 838 GTW_autopilotConfig 1;
BA_ "Confidence" SG_ 838 GTW_autopilotOverrideConfig 1;
BA_ "Confidence" SG_ 838 GTW_autopilotOverrideExpireTime 0;
VAL_ 1000 EPBR_matrixIndex 6 "AlertMatrix6" 5 "AlertMatrix5" 4 "AlertMatrix4" 3 "AlertMatrix3" 2 "AlertMatrix2" 1 "AlertMatrix1" 0 "AlertMatrix0" ;
VAL_ 744 EPBR_systemStatus 8 "EPB_VEHICLE_STATUS_MISMATCH" 7 "EPB_VEHICLE_STATUS_FAULT_SECURE" 6 "EPB_VEHICLE_STATUS_FAULT" 5 "EPB_VEHICLE_STATUS_RELEASING" 4 "EPB_VEHICLE_STATUS_PARKING" 3 "EPB_VEHICLE_STATUS_DYNAMIC" 2 "EPB_VEHICLE_STATUS_PARKED" 1 "EPB_VEHICLE_STATUS_RELEASED" 0 "EPB_VEHICLE_STATUS_UNKNOWN" ;
VAL_ 744 EPBR_freeRollModeStatus 2 "EPB_FREE_ROLL_MODE_ENABLED" 1 "EPB_FREE_ROLL_MODE_AVAILABLE" 0 "EPB_FREE_ROLL_MODE_UNAVAILABLE" ;
VAL_ 744 EPBR_chimeRequest 4 "EPB_CHIME_REQUEST_ACTIVE_DECEL" 3 "EPB_CHIME_REQUEST_ABOUT_TO_ACTIVE_DECEL" 2 "EPB_CHIME_REQUEST_GPO" 1 "EPB_CHIME_REQUEST_GENERAL" 0 "EPB_CHIME_REQUEST_NONE" ;
VAL_ 744 EPBR_telltale 7 "EPB_TELLTALE_SNA" 4 "EPB_TELLTALE_LAMP_RED_FLASH" 3 "EPB_TELLTALE_LAMP_AMBER_ON" 2 "EPB_TELLTALE_LAMP_RED_ON" 1 "EPB_TELLTALE_LAMP_RED_PARKED" 0 "EPB_TELLTALE_LAMP_OFF" ;
VAL_ 744 EPBR_cdpRequest 1 "EPB_CDP_REQUESTED" 0 "EPB_CDP_NOT_REQUESTED" ;
VAL_ 744 EPBR_uiParkAvailable 2 "EPB_AVAIL_REAPPLIED" 1 "EPB_AVAIL_AVAILABLE" 0 "EPB_AVAIL_NOT_AVAILABLE" ;
VAL_ 744 EPBR_brakeDiscWipeRequest 3 "EPB_BRAKEDISCWIPE_REQUEST_SNA" 2 "EPB_BRAKEDISCWIPE_REQUEST_STRONG" 1 "EPB_BRAKEDISCWIPE_REQUEST_LIGHT" 0 "EPB_BRAKEDISCWIPE_REQUEST_NONE" ;
VAL_ 744 EPBR_uiWinchModeLvStatus 3 "EPB_LV_OK" 2 "EPB_LV_BLOCKED_TIMER_RUNNING" 1 "EPB_LV_BLOCKED_INPUT_VOLTAGE_LOW" 0 "EPB_LV_BLOCKED_BATTERY" ;
VAL_ 981 ESP_matrixIndex 6 "AlertMatrix6" 5 "AlertMatrix5" 4 "AlertMatrix4" 3 "AlertMatrix3" 2 "AlertMatrix2" 1 "AlertMatrix1" 0 "AlertMatrix0" ;
VAL_ 373 ESP_wheelSpeedFrL 8191 "SNA" ;
VAL_ 373 ESP_wheelSpeedFrR 8191 "SNA" ;
VAL_ 373 ESP_wheelSpeedReL 8191 "SNA" ;
VAL_ 373 ESP_wheelSpeedReR 8191 "SNA" ;
VAL_ 282 GTW_BKP_BATT_MON 4095 "SNA" ;
VAL_ 282 GTW_BKP_BATT_NTC_P 4095 "SNA" ;
VAL_ 282 GTW_ECALL_GPS_ANT_BIAS 4095 "SNA" ;
VAL_ 282 GTW_ECALL_MIC_DIAG 4095 "SNA" ;
VAL_ 282 GTW_SOS_ECALL_nRQST_BUF 4095 "SNA" ;
VAL_ 1384 GTW_alertID 414 "a414_socHeldInReset" 410 "a410_unexpectedResetCause2" 409 "a409_unexpectedResetCause" 400 "a400_ethlSwitchOTPIncorrect" 399 "a399_ethIfRxTcpipQueueDrop" 398 "a398_awakeForExtendedTime" 397 "a397_alreadyInDrive" 396 "a396_alreadyInReverse" 395 "a395_lwipIcmpError" 393 "a393_osdSramCrcMismatch" 391 "a391_adspMacAddrCheckFailed" 389 "a389_rcmEventDetected" 388 "a388_adspWatchdogSkipped" 387 "a387_externalRtcReadFailure" 386 "a386_RCUCALversionMismatch" 385 "a385_RCUversionMismatch" 384 "a384_IDBCALversionMismatch" 383 "a383_IDB1versionMismatch" 382 "a382_IDBversionMismatch" 381 "a381_DPBCALversionMismatch" 380 "a380_DPBversionMismatch" 376 "a376_blFailedToExecBootImg" 366 "a366_uiGearRequestMismatch" 364 "a364_BLEEPCRADLEversionMismatch" 363 "a363_RGBDOORRRversionMismatch" 362 "a362_RGBDOORFRversionMismatch" 361 "a361_RGBDOORRLversionMismatch" 360 "a360_RGBDOORFLversionMismatch" 359 "a359_RGBIPFRversionMismatch" 358 "a358_RGBIPFLversionMismatch" 356 "a356_touchGPIOStatusCheck" 355 "a355_EPASTSversionMismatch" 354 "a354_EPASTPversionMismatch" 353 "a353_sASILStatusCheck" 352 "a352_mASILStatusCheck" 351 "a351_sOSDCrcCheck" 350 "a350_mOSDCrcCheck" 349 "a349_VCBLDCPBversionMismatch" 348 "a348_VCBLDCFversionMismatch" 342 "a342_VCBLDCPPversionMismatch" 336 "a336_possibleCanTxIssue" 334 "a334_hrlFolderSpaceLow" 332 "a332_unknownDisplayPN" 331 "a331_SWSRversionMismatch" 330 "a330_SWSLversionMismatch" 329 "a329_FOHMversionMismatch" 328 "a328_smartShiftDisabled" 323 "a323_gestureStartOutOfStrip" 322 "a322_gestureUnrecognizedFromMoving" 317 "a317_sdCardChkdskRepairFailed" 316 "a316_sdCardChkdskRepair" 314 "a314_canLogBlockWriteErr" 313 "a313_OSDActive" 312 "a312_hrlFileIncomplete" 311 "a311_canLogQueueFullBeforeFsInit" 309 "a309_VCUSBversionMismatch" 282 "a282_tcuPhyConfigurationFailed" 281 "a281_likelyMissedPoke" 280 "a280_hrlFrameDropped" 279 "a279_adspRepeatedWatchdog" 278 "a278_ethSwitchCongested" 277 "a277_NonRevCDrMOSMitigationFailed" 276 "a276_VDDSOC_DrMOS_Fault" 275 "a275_VDDCORE_DrMOS_Fault" 274 "a274_BLEEPREARRIGHTversionMismatch" 273 "a273_BLEEPREARLEFTversionMismatch" 268 "a268_stoMIA" 267 "a267_dpp2MIA" 266 "a266_dpp1MIA" 265 "a265_optionFlagsError" 264 "a264_hrlPseudoFileAvail" 263 "a263_hrlUdpFileAvail" 262 "a262_canLogBlockDropped" 261 "a261_adspWatchdog" 260 "a260_unknownPN" 255 "a255_rtc32KHzWatchdog" 246 "a246_touchcoreHeartbeat" 245 "a245_apsNotDisabled" 244 "a244_SDCRversionMismatch" 230 "a230_touchInterruptStorm" 229 "a229_displaySoftsetConnection" 228 "a228_DISPOSDversionMismatch" 227 "a227_DISPTOUCHversionMismatch" 226 "a226_DISPversionMismatch" 225 "a225_resetOnSleepWake" 224 "a224_sdCardUpgradeNeeded" 223 "a223_LVBMSversionMismatch" 219 "a219_CMPSversionMismatch" 218 "a218_switchOTPIncorrect" 186 "a186_swrPrecaution" 176 "a176_TPMShardWarnRearRight" 175 "a175_TPMShardWarnRearLeft" 174 "a174_TPMShardWarnFrontRight" 173 "a173_TPMShardWarnFrontLeft" 172 "a172_TPMSsoftWarnRearRight" 171 "a171_TPMSsoftWarnRearLeft" 170 "a170_TPMSsoftWarnFrontRight" 169 "a169_TPMSsoftWarnFrontLeft" 168 "a168_nErrCanFaultParty" 167 "a167_nErrCanFaultCh" 166 "a166_nErrCanFaultVeh" 165 "a165_USMversionMismatch" 155 "a155_PMversionMismatch" 153 "a153_externalRtcAlarmFailure" 151 "a151_HCM3RversionMismatch" 150 "a150_HCM3LversionMismatch" 149 "a149_rtcTimeSetInPast" 147 "a147_updateAbortFor12v" 146 "a146_performancePackageMismatch" 145 "a145_carConfigsNotWritten" 144 "a144_hrlStateMachine" 143 "a143_possibleCanWakeIssue" 141 "a141_teleCANETHis" 140 "a140_cancoreHeartbeat" 139 "a139_CMPDversionMismatch" 138 "a138_sdCardEndOfLife" 137 "a137_lowHeap" 136 "a136_hrlGameModeFileAvail" 135 "a135_canLogQueueFull" 134 "a134_disableFeatureFailed" 133 "a133_adspFaultDetected" 129 "a129_ICRversionMismatch" 127 "a127_noFilePointersAvailable" 125 "a125_switchReplayUnlocked" 123 "a123_BDYbusOverloaded" 122 "a122_BDY_canFault" 120 "a120_switchUnlocked" 118 "a118_unexpectedFunctionalResetStatus" 117 "a117_unexpectedDestructiveResetStatus" 116 "a116_switchInitFailed" 115 "a115_hrlEventFileAvail" 114 "a114_updtRetried" 113 "a113_unrecognizedCanMessage" 112 "a112_z4bDisabled" 111 "a111_writeMdioFailed" 110 "a110_readMdioFailed" 109 "a109_failedToStartUpdater" 108 "a108_BLEEPREARversionMismatch" 107 "a107_BLEEPRIGHTversionMismatch" 106 "a106_BLEEPLEFTversionMismatch" 105 "a105_eBuckConfigured" 104 "a104_sdCardDriverArgCorrupted" 103 "a103_sdCardFormatted" 101 "a101_switchWatchdog" 100 "a100_CBCversionMismatch" 99 "a099_SWCversionMismatch" 98 "a098_HCMRversionMismatch" 97 "a097_HCMLversionMismatch" 96 "a096_sdCardFatCorrupted" 95 "a095_sdCardFull" 94 "a094_sdCardInvReqOverflowCount" 93 "a093_sdCardInvReqOverflowBase" 92 "a092_sdCardInvReqZero" 91 "a091_lowStack" 90 "a090_ocuFailed" 89 "a089_sdCardWatchdog" 88 "a088_sdCardInvReqParallel" 87 "a087_ocuInProgress" 86 "a086_ocu" 84 "a084_canFrameDropped" 83 "a083_udsMsgDroppedByTcpStack" 82 "a082_sdCardBSCorrupted" 81 "a081_udsMessageRejected" 80 "a080_CHbusOverloaded" 79 "a079_PARTYbusOverloaded" 78 "a078_VEHbusOverloaded" 77 "a077_bmpPmicError" 76 "a076_ethInterfaceReset" 75 "a075_epas3sMIA" 74 "a074_epas3pMIA" 73 "a073_steeringWheelReset" 72 "a072_updateFailure" 71 "a071_hrlTrigger" 70 "a070_hrlDump" 69 "a069_diskioErr" 68 "a068_prodKeyMissing" 67 "a067_tcpDebug" 66 "a066_exception" 65 "a065_PARTY_canFault" 64 "a064_CH_canFault" 63 "a063_VEH_canFault" 62 "a062_bmpWatchdog" 61 "a061_bmpSleepFailure" 60 "a060_unFused" 59 "a059_inFactoryMode" 58 "a058_rtcAlarmFailure" 57 "a057_i2cFailure" 55 "a055_OPCFversionMismatch" 54 "a054_OPCRversionMismatch" 53 "a053_busSleepFailure" 52 "a052_ifTxSpans" 51 "a051_sdCardFileSystemFailure" 50 "a050_sdCardInitFailure" 49 "a049_corruptedManifest" 48 "a048_EPAS3SversionMismatch" 47 "a047_VCRIGHTversionMismatch" 46 "a046_VCLEFTversionMismatch" 45 "a045_VCFRONTversionMismatch" 43 "a043_THSversionMismatch" 42 "a042_TASversionMismatch" 41 "a041_VCSECversionMismatch" 40 "a040_SCCMversionMismatch" 39 "a039_RCMCALversionMismatch" 38 "a038_RCMversionMismatch" 37 "a037_RADCversionMismatch" 36 "a036_PTCversionMismatch" 35 "a035_PMFversionMismatch" 34 "a034_PMRversionMismatch" 33 "a033_PCSCPU2versionMismatch" 32 "a032_PCSversionMismatch" 31 "a031_PARKversionMismatch" 30 "a030_OCS1PversionMismatch" 29 "a029_IBSTCALversionMismatch" 28 "a028_IBSTversionMismatch" 27 "a027_HVPversionMismatch" 26 "a026_GTWversionMismatch" 25 "a025_ESPCALversionMismatch" 24 "a024_ESPversionMismatch" 23 "a023_EPBRversionMismatch" 22 "a022_EPBLversionMismatch" 21 "a021_EPAS3PversionMismatch" 20 "a020_DIRversionMismatch" 19 "a019_CPversionMismatch" 18 "a018_CMPversionMismatch" 17 "a017_BMSversionMismatch" 16 "a016_BLEEPCENTERversionMismatch" 15 "a015_DIFversionMismatch" 14 "a014_APSversionMismatch" 12 "a012_maincoreWatchdog" 11 "a011_cancoreWatchdog" 10 "a010_wdTaskCount" 9 "a009_lateTask" 8 "a008_ifPbufAllocError" 7 "a007_ifRxBufError" 6 "a006_ifTxOutputFull" 5 "a005_stackOverflowHook" 4 "a004_mallocHook" 3 "a003_logWriteRecord" 2 "a002_taskError" 1 "a001_canEthTxQueue" 0 "ALERT_DO_NOT_USE_ZERO" ;
VAL_ 1384 GTW_alertState 1 "SET" 0 "CLEARED" ;
VAL_ 1384 GTW_a049_headerError 3 "HEADER_READ_FAIL" 2 "MUID_LIST_UNEXPECTED" 1 "HEADER_INFO_BAD" 0 "HEADER_OK" ;
VAL_ 1384 GTW_a062_bmpWatchdogReason 2 "WAKE_FAILURE" 1 "RUNTIME_FAILURE" 0 "WATCHDOG_NONE" ;
VAL_ 1384 GTW_a063_VEH_faultConfinement 2 "BUS_OFF" 1 "ERROR_PASSIVE" 0 "ERROR_ACTIVE" ;
VAL_ 1384 GTW_a064_CH_faultConfinement 2 "BUS_OFF" 1 "ERROR_PASSIVE" 0 "ERROR_ACTIVE" ;
VAL_ 1384 GTW_a065_PARTY_faultConfinement 2 "BUS_OFF" 1 "ERROR_PASSIVE" 0 "ERROR_ACTIVE" ;
VAL_ 1384 GTW_a077_bmpPmicErrorType 4 "INTERNAL_SM" 3 "OT" 2 "MEM_CORRUPT" 1 "OC_OV_CC" 0 "NONE" ;
VAL_ 1384 GTW_a081_ISOTPmsgType 3 "FLOW" 2 "CONSECUTIVE" 1 "FIRST" 0 "SINGLE" ;
VAL_ 1384 GTW_a081_udsSID 536870912 "MAX_VALUE" 16384 "ECU_RESET_SOFT" 8192 "ECU_RESET_KEY_OFF_ON" 4096 "ECU_RESET_HARD" 2048 "PING_TP" 1024 "DSC_EXTDS" 512 "SA" 256 "RQTE" 128 "TRD" 64 "RQUL" 32 "RQDL" 16 "RC_RRR" 8 "RC_STPR" 4 "RC_STR" 2 "WDBI" 1 "RBDI" ;
VAL_ 1384 GTW_a122_BDY_faultConfinement 2 "BUS_OFF" 1 "ERROR_PASSIVE" 0 "ERROR_ACTIVE" ;
VAL_ 1384 GTW_a261_failureReason 6 "INCORRECT_TYPE" 5 "INCORRECT_SEQ_NO" 4 "INCORRECT_ID" 3 "INCORRECT_ADDRESS" 2 "INCORRECT_LENGTH" 1 "RECEIVE_ERROR" 0 "NO_ERROR" ;
VAL_ 1384 GTW_a277_mitigationFailureReason 7 "FAILED_NVRAM_WRITE" 6 "FAILED_NVRAM_WRITE_PROTECTED" 5 "FAILED_REGISTERS_WRITE_PROTECTED" 4 "FAILED_REGISTER_WRITE" 3 "FAILED_REGISTER_READ" 2 "FAILED_ICE_NOT_AWAKE" 1 "NOT_NEEDED" 0 "APPLIED_SUCCESSFULLY" ;
VAL_ 1384 GTW_a279_failureReason 6 "INCORRECT_TYPE" 5 "INCORRECT_SEQ_NO" 4 "INCORRECT_ID" 3 "INCORRECT_ADDRESS" 2 "INCORRECT_LENGTH" 1 "RECEIVE_ERROR" 0 "NO_ERROR" ;
VAL_ 1384 GTW_a317_status 7 "MASK" 4 "PARTIAL" 3 "FAILED" 2 "SUCCESS" 1 "NOT_NEEDED" ;
VAL_ 1384 GTW_a317_errorCode 19 "FS_INFO_INVALID_SIG" 18 "FS_INFO_SECTOR_NOT_FOUND" 17 "FS_INFO_READ_FAILED" 16 "FS_INFO_WRITE_FAILED" 15 "INVALID_CLUSTER" 14 "DIR_TOO_DEEP" 13 "UNKNOWN_FS" 12 "CLUSTER_IN_USE" 11 "FAT_MISMATCHED" 10 "FAT_READ_FAILED" 9 "FAT_WRITE_FAILED" 8 "NOT_FAT32" 7 "BAD_SECTOR_SIZE" 6 "BR_READ_FAILED" 5 "MBR_READ_FAILED" 4 "DISK_INIT_FAILED" 3 "INSUFFICIENT_MEMORY" 2 "ERROR_FOUND_FIXED" 1 "ERROR_FOUND" 0 "NO_ERROR" ;
VAL_ 62 GTW_matrixIndex 6 "AlertMatrix6" 5 "AlertMatrix5" 4 "AlertMatrix4" 3 "AlertMatrix3" 2 "AlertMatrix2" 1 "AlertMatrix1" 0 "AlertMatrix0" ;
VAL_ 838 GTW_autopilotOverrideState 3 "TIMEBOUND_SUBSCRIPTION" 2 "TRIAL" 1 "SUBSCRIPTION" 0 "BASE" ;
VAL_ 838 GTW_autopilotConfig 4 "BASIC" 3 "SELF_DRIVING" 2 "ENHANCED" 1 "HIGHWAY" 0 "NONE" ;
VAL_ 838 GTW_autopilotOverrideConfig 4 "BASIC" 3 "SELF_DRIVING" 2 "ENHANCED" 1 "HIGHWAY" 0 "NONE" ;
